VERSION ""

NS_ :

BS_:

BU_: FUSION IVI CMS

BO_ 2365479471 ASC1_A: 8 FUSION
 SG_ ASC1NomLvFAxis : 0|4@1+ (1,0) [0|15] "" IVI
 SG_ ASC1NomLvRAxis : 4|4@1+ (1,0) [0|15] "" IVI
 SG_ ASC1BlwNomLvFAxis : 8|2@1+ (1,0) [0|3] "" Vector__XXX
 SG_ ASC1BlwNomLvRAxis : 10|2@1+ (1,0) [0|3] "" Vector__XXX
 SG_ ASC1AbvNomLvFAxis : 12|2@1+ (1,0) [0|3] "" Vector__XXX
 SG_ ASC1AbvNomLvRAxis : 14|2@1+ (1,0) [0|3] "" Vector__XXX
 SG_ ASC1LowCtrlFAxis : 16|2@1+ (1,0) [0|3] "" Vector__XXX
 SG_ ASC1LowCtrlRAxis : 18|2@1+ (1,0) [0|3] "" Vector__XXX
 SG_ ASC1LiftCtrlFAxis : 20|2@1+ (1,0) [0|3] "" Vector__XXX
 SG_ ASC1LiftCtrlRAxis : 22|2@1+ (1,0) [0|3] "" Vector__XXX
 SG_ ASC1KneelingInfo : 24|4@1+ (1,0) [0|15] "" IVI
 SG_ ASC1LvCtrlM : 28|4@1+ (1,0) [0|15] "" Vector__XXX
 SG_ SADev : 32|2@1+ (1,0) [0|3] "" Vector__XXX
 SG_ VehMotion : 34|2@1+ (1,0) [0|3] "" Vector__XXX
 SG_ DoorRls : 36|2@1+ (1,0) [0|3] "" Vector__XXX
 SG_ ASC1LiftAxle1P : 38|2@1+ (1,0) [0|3] "" Vector__XXX
 SG_ FABumpR : 40|2@1+ (1,0) [0|3] "" Vector__XXX
 SG_ RABumpR : 42|2@1+ (1,0) [0|3] "" Vector__XXX
 SG_ LA2Pos : 46|2@1+ (1,0) [0|3] "" Vector__XXX
 SG_ SuspenRmCtrl1 : 48|2@1+ (1,0) [0|3] "" Vector__XXX
 SG_ SuspenRmCtrl2 : 50|2@1+ (1,0) [0|3] "" Vector__XXX
 SG_ SuspCtrlrefuInfo : 56|4@1+ (1,0) [0|15] "" Vector__XXX

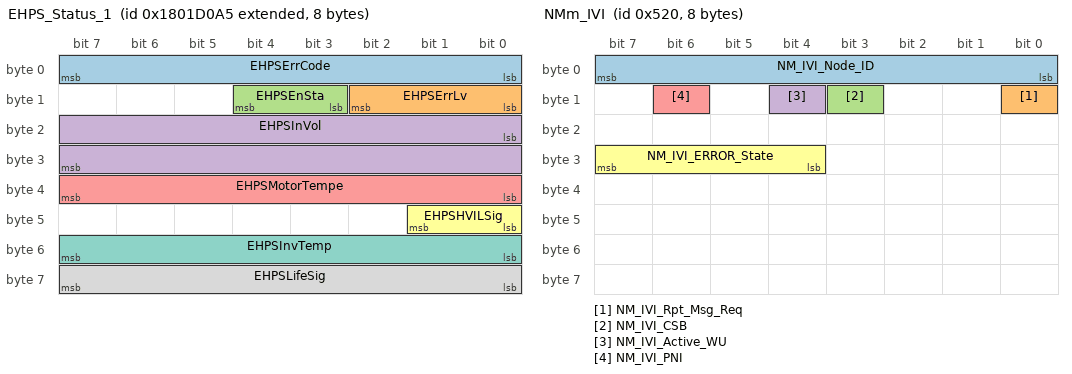
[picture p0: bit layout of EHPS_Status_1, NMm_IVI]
BO_ 2550255781 EHPS_Status_1: 8 FUSION
 SG_ EHPSErrCode : 0|8@1+ (1,0) [0|255] "" Vector__XXX
 SG_ EHPSErrLv : 8|3@1+ (1,0) [0|7] "" IVI
 SG_ EHPSEnSta : 11|2@1+ (1,0) [0|3] "" Vector__XXX
 SG_ EHPSInVol : 16|16@1+ (0.1,0) [0|1000] "V" Vector__XXX
 SG_ EHPSMotorTempe : 32|8@1+ (1,-40) [-40|200] "degC" Vector__XXX
 SG_ EHPSHVILSig : 40|2@1+ (1,0) [0|3] "" Vector__XXX
 SG_ EHPSInvTemp : 48|8@1+ (1,-40) [-40|150] "degC" Vector__XXX
 SG_ EHPSLifeSig : 56|8@1+ (1,0) [0|255] "" Vector__XXX

BO_ 2565865739 EBC1: 8 FUSION
 SG_ ASREngCtrlAtc : 0|2@1+ (1,0) [0|3] "" IVI
 SG_ ASRBrakeCtrlAtc : 2|2@1+ (1,0) [0|3] "" IVI
 SG_ AntiLBrakABSAct : 4|2@1+ (1,0) [0|3] "" Vector__XXX
 SG_ EBSBrakeSw : 6|2@1+ (1,0) [0|3] "" Vector__XXX
 SG_ BrakePedalPos : 8|8@1+ (0.4,0) [0|100] "%" Vector__XXX
 SG_ ABSOffroadSw : 16|2@1+ (1,0) [0|3] "" Vector__XXX
 SG_ ASROffroadSw : 18|2@1+ (1,0) [0|3] "" IVI
 SG_ ASRHillHolderSw : 20|2@1+ (1,0) [0|3] "" IVI
 SG_ TractCtrlOvrSw : 22|2@1+ (1,0) [0|3] "" Vector__XXX
 SG_ AcltrInterlockSw : 24|2@1+ (1,0) [0|3] "" Vector__XXX
 SG_ EngDerateSw : 26|2@1+ (1,0) [0|3] "" Vector__XXX
 SG_ EngAuxShutdownSw : 28|2@1+ (1,0) [0|3] "" Vector__XXX
 SG_ RmAccelEnSw : 30|2@1+ (1,0) [0|3] "" Vector__XXX
 SG_ EngRetSel : 32|8@1+ (0.4,0) [0|100] "%" Vector__XXX
 SG_ ABSFullyOper : 40|2@1+ (1,0) [0|3] "" IVI
 SG_ EBSRedWarnLampSta : 42|2@1+ (1,0) [0|3] "" IVI
 SG_ EBSAmWarnLampSta : 44|2@1+ (1,0) [0|3] "" IVI
 SG_ ATCASRInfoSig : 46|2@1+ (1,0) [0|3] "" IVI
 SG_ SACtrlBrakeCtrl : 48|8@1+ (1,0) [0|255] "SA" Vector__XXX
 SG_ HaltBrakeSw : 58|2@1+ (1,0) [0|3] "" Vector__XXX
 SG_ TrailerABSSta : 60|2@1+ (1,0) [0|3] "" Vector__XXX
 SG_ TrailerABSWarnSig : 62|2@1+ (1,0) [0|3] "" Vector__XXX

BO_ 513 IVI_P20_0: 64 IVI
 SG_ IVI_RrRoomlamp_Cmd : 0|1@0+ (1,0) [0|1] "" FUSION
 SG_ IVI_FrAtmoLamp_Cmd : 1|1@0+ (1,0) [0|1] "" FUSION
 SG_ IVI_RrAtmoLamp_Cmd : 2|1@0+ (1,0) [0|1] "" FUSION
 SG_ IVI_RrRmLampBright_Cmd : 6|4@0+ (1,0) [0|15] "" FUSION
 SG_ IVI_AmbiLgtSta : 7|1@0+ (1,0) [0|1] "" FUSION
 SG_ IVI_Passengerdoor_Sta : 10|1@0+ (1,0) [0|1] "" FUSION
 SG_ IVI_Frontindoorlight_Sta : 11|1@0+ (1,0) [0|1] "" FUSION
 SG_ IVI_FrRmLampBright_Cmd : 15|4@0+ (1,0) [0|15] "" FUSION

BO_ 602 METER1: 24 IVI
 SG_ METER_KPH_Calcu : 15|8@0+ (1,0) [0|254] "km/h" FUSION
 SG_ METER_MPH_Calcu : 23|8@0+ (1,0) [0|160] "mph" FUSION
 SG_ METER_KPH_Real : 31|12@0+ (0.125,0) [0|255.875] "km/h" FUSION
 SG_ METER_MPH_Real : 35|12@0+ (0.077675,0) [0|160.0105] "mph" FUSION
 SG_ Averaged_vehspeed : 49|10@0+ (1,0) [0|300] "km/h" FUSION
 SG_ AVGPwrConsumption : 71|16@0+ (0.1,-999.9) [-999.9|999.9] "Wh/km" FUSION
 SG_ APCforDTE : 87|16@0+ (0.1,-999.9) [-999.9|999.9] "Wh/km" FUSION
 SG_ AvailableTrip : 103|16@0+ (0.1,0) [0|999.9] "KM" FUSION
 SG_ ParkBrake : 112|1@0+ (1,0) [0|1] "" FUSION
 SG_ Charge : 113|1@0+ (1,0) [0|1] "" FUSION
 SG_ LEDlitWarnReq : 114|1@0+ (1,0) [0|1] "" FUSION
 SG_ Spd_Crl_Sta : 115|1@0+ (1,0) [0|1] "" FUSION
 SG_ Spd_Crl_Mode : 118|3@0+ (1,0) [0|7] "" FUSION
 SG_ Trip_B : 127|24@0+ (0.1,0) [0|99999.9] "KM" FUSION
 SG_ Trip_A : 151|24@0+ (0.1,0) [0|99999.9] "KM" FUSION
 SG_ ODOMETER : 175|24@0+ (0.1,0) [0|999999.9] "KM" FUSION

BO_ 1168 IVI1: 20 IVI
 SG_ FCP_FrEvt_BtnSyncReq : 16|1@0+ (1,0) [0|1] "" FUSION
 SG_ FCP_MidEvt_BtnAutoReq : 17|1@0+ (1,0) [0|1] "" FUSION
 SG_ FCP_FrEvt_BtnAutoReq : 18|1@0+ (1,0) [0|1] "" FUSION
 SG_ FCP_FrEvt_BtnACReq : 19|1@0+ (1,0) [0|1] "" FUSION
 SG_ FCP_FrEvt_BtnACMaxReq : 20|1@0+ (1,0) [0|1] "" FUSION
 SG_ VehACModReq : 23|3@0+ (1,0) [0|7] "" FUSION
 SG_ LINKtoDrive : 24|1@0+ (1,0) [0|1] "" FUSION
 SG_ SmartEco_Mode_SW : 25|1@0+ (1,0) [0|1] "" FUSION
 SG_ OTA_CancelDL_Req : 26|1@0+ (1,0) [0|1] "" FUSION
 SG_ IVI_OTA_Upd_Sta : 28|2@0+ (1,0) [0|3] "" FUSION
 SG_ OTA_UpdStart_Req : 29|1@0+ (1,0) [0|1] "" FUSION
 SG_ OTA_SuspendDL_Req : 30|1@0+ (1,0) [0|1] "" FUSION
 SG_ OTA_DL_Req : 31|1@0+ (1,0) [0|1] "" FUSION
 SG_ AmbLigh_SafetyAlert_SW : 32|1@0+ (1,0) [0|1] "" FUSION
 SG_ AmbLigh_LowBatAlert_SW : 33|1@0+ (1,0) [0|1] "" FUSION
 SG_ AmbLight_WlcmLight_SW : 34|1@0+ (1,0) [0|1] "" FUSION
 SG_ AmbLight_DimInDark_SW : 35|1@0+ (1,0) [0|1] "" FUSION
 SG_ AmbLight_SW : 36|1@0+ (1,0) [0|1] "" FUSION
 SG_ OpenDrOpenWdo_SW : 37|1@0+ (1,0) [0|1] "" FUSION
 SG_ Upd_Countdown_Cancel : 38|1@0+ (1,0) [0|1] "" FUSION
 SG_ Upd_Countdown_Skip : 39|1@0+ (1,0) [0|1] "" FUSION
 SG_ AmbLightColorSet : 46|7@0+ (1,0) [0|127] "" FUSION
 SG_ Sched_OTA_wake : 47|1@0+ (1,0) [0|1] "" FUSION
 SG_ A2B_Node_sta : 55|1@0+ (1,0) [0|1] "" FUSION
 SG_ Sched_Chg_St_Time_Min : 61|6@0+ (1,0) [0|59] "MINUTE" FUSION
 SG_ Sched_Chg_Day_Set : 62|1@0+ (1,0) [0|1] "" FUSION
 SG_ Re_Radio_Sta : 63|1@0+ (1,0) [0|1] "" FUSION
 SG_ Sched_Chg_St_Time_HR : 68|5@0+ (1,0) [0|23] "HOUR" FUSION
 SG_ UserSet : 71|3@0+ (1,0) [0|7] "" FUSION
 SG_ Sched_Chg_End_Time_Min : 77|6@0+ (1,0) [0|59] "MINUTE" FUSION
 SG_ Sched_Chg_End_Time_HR : 84|5@0+ (1,0) [0|23] "HOUR" FUSION
 SG_ BrkAbn_GoReady_SW : 85|1@0+ (1,0) [0|1] "" FUSION
 SG_ OTA_CompNTFY_Pres : 86|1@0+ (1,0) [0|1] "" FUSION
 SG_ mFRD_link_Sta : 87|1@0+ (1,0) [0|1] "" FUSION
 SG_ IVI_Time_Check : 95|8@0+ (1,0) [0|255] "" FUSION
 SG_ IVI_Time_Second : 101|6@0+ (1,0) [0|63] "SECOND" FUSION
 SG_ PW_CLOSE_IMD : 102|1@0+ (1,0) [0|1] "" FUSION
 SG_ PW_CONTINUE_USE : 103|1@0+ (1,0) [0|1] "" FUSION
 SG_ IVI_Time_Minute : 109|6@0+ (1,0) [0|63] "MINUTE" FUSION
 SG_ IVI_Time_Day : 116|5@0+ (1,0) [0|31] "DAY" FUSION
 SG_ IVI_DelAccReq_Sta : 119|3@0+ (1,0) [0|7] "" FUSION
 SG_ IVI_Time_Hour : 124|5@0+ (1,0) [0|31] "HOUR" FUSION
 SG_ IVI_CreateAccReq_Sta : 127|3@0+ (1,0) [0|7] "" FUSION
 SG_ IVI_Time_Month : 131|4@0+ (1,0) [0|12] "MONTH" FUSION
 SG_ IVI_LinkKey_Sta : 135|4@0+ (1,0) [0|15] "" FUSION
 SG_ IVI_Time_Year : 142|7@0+ (1,2000) [2000|2127] "YEAR" FUSION
 SG_ IVI_LinkAccReq_Sta : 143|1@0+ (1,0) [0|1] "" FUSION
 SG_ IVI_LinkAcc_Sta : 146|3@0+ (1,0) [0|7] "" FUSION
 SG_ IVI_FrTrunk_UnlockReq_Sta : 147|1@0+ (1,0) [0|1] "" FUSION
 SG_ IVI_CLWin_LockDoorSW_Sta : 148|1@0+ (1,0) [0|1] "" FUSION
 SG_ IVI_Lock_SoundSW_Sta : 149|1@0+ (1,0) [0|1] "" FUSION
 SG_ AmbLightBrightnessSet : 54|7@0+ (1,0) [0|127] "" FUSION
 SG_ IVI_Located_STA : 79|2@0+ (1,0) [0|3] "" FUSION
 SG_ IVI_AutoTheme_But_Sta : 154|1@0+ (1,0) [0|1] "" FUSION
 SG_ IVI_NAVI_Foreground_Sta : 155|1@0+ (1,0) [0|1] "" FUSION
 SG_ IVI_HMI_Undefined_Sta : 158|3@0+ (1,0) [0|7] "" FUSION
 SG_ IVI_QuickRefresh_Sta : 159|1@0+ (1,0) [0|1] "" FUSION
 SG_ IVI_DMS_SW_Sta : 150|1@0+ (1,0) [0|1] "" FUSION
 SG_ IVI_AirRefresh_ByDMS_Sta : 151|1@0+ (1,0) [0|1] "" FUSION
 SG_ IVI_SWC_VibMode_Sta : 111|2@0+ (1,0) [0|3] "" FUSION
 SG_ IVI_sigScreenReq_Sta : 152|1@0+ (1,0) [0|1] "" FUSION
 SG_ IVI_DSEAT_anti_set_Sta : 153|1@0+ (1,0) [0|1] "" FUSION

BO_ 1173 IVI2: 64 IVI
 SG_ Perd_V2L : 3|4@0+ (1,0) [0|15] "" FUSION
 SG_ SOC_V2LLimit : 7|4@0+ (5,20) [20|80] "%" FUSION
 SG_ Walkaway_Lock_SW : 8|1@0+ (1,0) [0|1] "" FUSION
 SG_ FalseNPrevent_SW : 10|1@0+ (1,0) [0|1] "" FUSION
 SG_ IVI_CreepSW_Req : 11|1@0+ (1,0) [0|1] "" FUSION
 SG_ IVI_CfmTo_Rdy : 15|1@0+ (1,0) [0|1] "" FUSION
 SG_ IVI_Req_V2L : 17|2@0+ (1,0) [0|2] "" FUSION
 SG_ IVI_PSEATHeater_Cmd : 20|3@0+ (1,0) [0|7] "" FUSION
 SG_ IVI_DSEATHeater_Cmd : 23|3@0+ (1,0) [0|7] "" FUSION
 SG_ Light_ShowStop_Req : 28|1@0+ (1,0) [0|1] "" FUSION
 SG_ Light_ShowStart_Req : 29|1@0+ (1,0) [0|1] "" FUSION
 SG_ WlcmLight_Mode : 31|2@0+ (1,0) [0|3] "" FUSION
 SG_ IVI_SWC_LUndefined_Sta : 75|4@0+ (1,0) [0|15] "" FUSION
 SG_ IVI_SWC_RUndefined_Sta : 79|4@0+ (1,0) [0|15] "" FUSION
 SG_ Sched_Chg_limit : 84|5@0+ (2,50) [50|100] "%" FUSION
 SG_ METER_Malfunc_Sta : 89|2@0+ (1,0) [0|2] "" FUSION
 SG_ sigFootReq : 90|1@0+ (1,0) [0|1] "" FUSION
 SG_ sigFaceReq : 91|1@0+ (1,0) [0|1] "" FUSION
 SG_ Sched_Chg_Start : 92|1@0+ (1,0) [0|1] "" FUSION
 SG_ Sched_Chg_wake : 93|1@0+ (1,0) [0|1] "" FUSION
 SG_ Sched_Chg_butt : 94|1@0+ (1,0) [0|1] "" FUSION
 SG_ Sched_Chg_Stop : 95|1@0+ (1,0) [0|1] "" FUSION
 SG_ L_RRD_ControlCommand : 102|7@0+ (1,0) [0|127] "%" FUSION
 SG_ IVI_Start_Chg_req : 103|1@0+ (1,0) [0|1] "" FUSION
 SG_ L_RLD_ControlCommand : 110|7@0+ (1,0) [0|127] "%" FUSION
 SG_ IVI_Stop_Chg_req : 111|1@0+ (1,0) [0|1] "" FUSION
 SG_ L_Pas_ControlCommand : 118|7@0+ (1,0) [0|127] "%" FUSION
 SG_ IVI_Unlock_Chg_req : 119|1@0+ (1,0) [0|1] "" FUSION
 SG_ L_Drv_ControlCommand : 126|7@0+ (1,0) [0|127] "%" FUSION
 SG_ TPMS_Cali_Butt : 127|1@0+ (1,0) [0|1] "" FUSION
 SG_ GPS_LONG : 135|32@0+ (1,0) [0|4.294967295E9] "" FUSION
 SG_ GPS_LAT : 167|32@0+ (1,0) [0|4.294967295E9] "SECOND" FUSION
 SG_ sigSetTempZon1Req : 197|6@0+ (0.5,17) [17|32] "Deg^C" FUSION
 SG_ sigHvacFrontReq : 198|1@0+ (1,0) [0|1] "" FUSION
 SG_ sigDfrstReq : 199|1@0+ (1,0) [0|1] "" FUSION
 SG_ sigSetTempZon2Req : 205|6@0+ (0.5,17) [17|32] "Deg^C" FUSION
 SG_ sigRecircReq : 206|1@0+ (1,0) [0|1] "" FUSION
 SG_ sigHvacReq : 207|1@0+ (1,0) [0|1] "" FUSION
 SG_ AEB_BUTT : 209|2@0+ (1,0) [0|3] "" FUSION
 SG_ sigSetTempZon3Req : 215|6@0+ (0.5,17) [17|32] "Deg^C" FUSION
 SG_ sigAirIntenZon3Req : 219|4@0+ (1,0) [0|15] "" FUSION
 SG_ sigAirIntenZon1Req : 223|4@0+ (1,0) [0|15] "" FUSION
 SG_ BSDMute_BUTT : 225|2@0+ (1,0) [0|3] "" FUSION
 SG_ sigWindDirZon3Req : 228|3@0+ (1,0) [0|7] "" FUSION
 SG_ FCWMute_BUTT : 233|2@0+ (1,0) [0|3] "" FUSION
 SG_ LKA_BUTT : 235|2@0+ (1,0) [0|3] "" FUSION
 SG_ ODAMute_BUTT : 237|2@0+ (1,0) [0|3] "" FUSION
 SG_ LDWMute_BUTT : 239|2@0+ (1,0) [0|3] "" FUSION
 SG_ NAVI_Speed_Limit_A : 241|2@0+ (1,0) [0|3] "" FUSION
 SG_ Temperature_unit : 242|1@0+ (1,0) [0|1] "" FUSION
 SG_ Distance_unit : 243|1@0+ (1,0) [0|1] "" FUSION
 SG_ ESC_SW_Cmd : 245|2@0+ (1,0) [0|3] "" FUSION
 SG_ IVI_Panel_Act : 246|1@0+ (1,0) [0|1] "" FUSION
 SG_ sigHvacRearReq : 247|1@0+ (1,0) [0|1] "" FUSION
 SG_ Time_system : 255|8@0+ (1,0) [0|255] "" FUSION
 SG_ Pressure_unit : 263|8@0+ (1,0) [0|255] "" FUSION
 SG_ IVI_Screen : 269|6@0+ (1,0) [0|62] "" FUSION
 SG_ TurnSwTimeSet : 271|2@0+ (1,0) [0|3] "" FUSION
 SG_ NAVI_Direction_STA : 279|8@0+ (1,0) [0|255] "" FUSION
 SG_ OFF_AC_MODE : 282|3@0+ (1,0) [0|7] "" FUSION
 SG_ IVI_PW_Mode_Req : 284|2@0+ (1,0) [0|3] "" FUSION
 SG_ User_p_upload : 285|1@0+ (1,0) [0|1] "" FUSION
 SG_ CameraWrn : 286|1@0+ (1,0) [0|1] "" FUSION
 SG_ Wifi_Reset : 287|1@0+ (1,0) [0|1] "" FUSION
 SG_ NAVI_Cam_Dist_info : 295|8@0+ (1,0) [0|255] "m" FUSION
 SG_ IVI_Panel_X_Coor : 303|12@0+ (1,0) [0|4095] "" FUSION
 SG_ IVI_Panel_Y_Coor : 307|12@0+ (1,0) [0|4095] "" FUSION
 SG_ HeadLampSW : 321|2@0+ (1,0) [0|3] "" FUSION
 SG_ NAVI_State : 323|2@0+ (1,0) [0|3] "" FUSION
 SG_ Wifi_Sta_IVI_TBOX : 327|4@0+ (1,0) [0|15] "" FUSION
 SG_ MFRD_N_Bright_Req : 334|7@0+ (1,0) [0|100] "%" FUSION
 SG_ User_p_download : 335|1@0+ (1,0) [0|1] "" FUSION
 SG_ PSEAT_vent_req : 338|3@0+ (1,0) [0|7] "" FUSION
 SG_ FFogLampSW : 339|1@0+ (1,0) [0|1] "" FUSION
 SG_ DSEAT_vent_req : 342|3@0+ (1,0) [0|7] "" FUSION
 SG_ RFogLampSW : 343|1@0+ (1,0) [0|1] "" FUSION
 SG_ IVI_PTG_Mode_SW : 345|2@0+ (1,0) [0|3] "" FUSION
 SG_ IVI_PTG_Sta_SW : 347|2@0+ (1,0) [0|3] "" FUSION
 SG_ SLG_Sw : 349|2@0+ (1,0) [0|3] "" FUSION
 SG_ FS_Off_Sw : 351|2@0+ (1,0) [0|3] "" FUSION
 SG_ CAAS_Sw : 353|2@0+ (1,0) [0|3] "" FUSION
 SG_ DSEAT_entryfun_set : 354|1@0+ (1,0) [0|1] "" FUSION
 SG_ DSEAT_anti_set : 355|1@0+ (1,0) [0|1] "" FUSION
 SG_ IVI_TrailerCheckReq_Sta : 356|1@0+ (1,0) [0|1] "" FUSION
 SG_ TPMS_Res_Butt : 357|1@0+ (1,0) [0|1] "" FUSION
 SG_ FollowMeSW : 358|1@0+ (1,0) [0|1] "" FUSION
 SG_ SetUnlockSingle : 359|1@0+ (1,0) [0|1] "" FUSION
 SG_ IVI_Mute_Sta : 360|1@0+ (1,0) [0|1] "" FUSION
 SG_ IVI_PTG_USSta_SW : 361|1@0+ (1,0) [0|1] "" FUSION
 SG_ IVI_WI_MAIN_SW : 362|1@0+ (1,0) [0|1] "" FUSION
 SG_ IVI_RR_Def_Req : 363|1@0+ (1,0) [0|1] "" FUSION
 SG_ IVI_Night_Mode_Sta : 364|1@0+ (1,0) [0|1] "" FUSION
 SG_ IVI_Status : 365|1@0+ (1,0) [0|1] "" FUSION
 SG_ LVDAMute_BUTT : 367|2@0+ (1,0) [0|3] "" FUSION
 SG_ NAVI_Distance_info : 375|24@0+ (1,0) [0|1.6777215E7] "m" FUSION
 SG_ Hood_Latch_SW : 393|2@0+ (1,0) [0|3] "" FUSION
 SG_ IVI_TrailerModeSW_Sta : 394|1@0+ (1,0) [0|1] "" FUSION
 SG_ RCTA_BUTT : 396|2@0+ (1,0) [0|3] "" FUSION
 SG_ IVI_Pwroff_req : 397|1@0+ (1,0) [0|1] "" FUSION
 SG_ IVI_Trigger_req : 398|1@0+ (1,0) [0|1] "" FUSION
 SG_ AVM_Err_STA : 399|1@0+ (1,0) [0|1] "" FUSION
 SG_ SenstivityPosition : 403|4@0+ (1,0) [0|15] "" FUSION
 SG_ AVM_Parking_mode : 407|4@0+ (1,0) [0|15] "" FUSION
 SG_ NAVI_Tunnel : 411|12@0+ (1,0) [0|2000] "m" FUSION
 SG_ NAVI_ForwardLinkLevel : 415|4@0+ (1,0) [0|15] "" FUSION
 SG_ NAVI_Tollgate : 427|12@0+ (1,0) [0|2000] "m" FUSION
 SG_ NAVI_LinkClass : 431|4@0+ (1,0) [0|15] "" FUSION
 SG_ NAVI_SpeedLimit : 444|5@0+ (1,0) [0|31] "km/h" FUSION
 SG_ NAVI_RoadClass : 447|3@0+ (1,0) [0|7] "" FUSION
 SG_ RoomLampMode : 455|1@0+ (1,0) [0|1] "" FUSION
 SG_ AC_Chg_Cur_Set : 462|7@0+ (1,5) [5|132] "A" FUSION
 SG_ IVI_SWC_ACCMode_Sta : 463|1@0+ (1,0) [0|1] "" FUSION
 SG_ SOC_Limit_Set : 468|5@0+ (2,50) [50|100] "%" FUSION
 SG_ CDL_Lock_Butt : 469|1@0+ (1,0) [0|1] "" FUSION
 SG_ CDL_Unlock_Butt : 470|1@0+ (1,0) [0|1] "" FUSION
 SG_ SOC_ADJ_BUTT : 471|1@0+ (1,0) [0|1] "" FUSION
 SG_ Roll_Mode_SW_Cmd : 473|2@0+ (1,0) [0|3] "" FUSION
 SG_ TCS_SW_Cmd : 475|2@0+ (1,0) [0|3] "" FUSION
 SG_ SLIF_BUTT : 477|2@0+ (1,0) [0|2] "" FUSION
 SG_ Roll_Eng_Mode : 478|1@0+ (1,0) [0|1] "" FUSION
 SG_ IVI_LVChrgFuncSW : 497|2@0+ (1,0) [0|3] "" FUSION
 SG_ IVI_PwrLockSW : 499|2@0+ (1,0) [0|3] "" FUSION
 SG_ IVI_CoastDwSW : 501|2@0+ (1,0) [0|3] "" FUSION
 SG_ IVI_ActvDmpDisabSW : 503|2@0+ (1,0) [0|3] "" FUSION
 SG_ AVM_parking_cancel : 505|2@0+ (1,0) [0|3] "" FUSION
 SG_ AVM_parking_excute : 507|2@0+ (1,0) [0|3] "" FUSION
 SG_ AVM_OFF_Rec_Butt : 508|1@0+ (1,0) [0|1] "" FUSION
 SG_ Approach_Unlock_SW : 9|1@0+ (1,0) [0|1] "" FUSION
 SG_ IVI_ISA_OffsetSpd : 451|4@0+ (1,0) [0|14] "" FUSION
 SG_ IVI_PTG_Open_Height : 14|3@0+ (1,0) [0|7] "" FUSION
 SG_ IVI_ChargePortSW_Sta : 479|1@0+ (1,0) [0|1] "" FUSION
 SG_ IVI_SLIF_Warning_Sta : 453|2@0+ (1,0) [0|3] "" FUSION
 SG_ IVI_ACC_Adaptive_Sta : 454|1@0+ (1,0) [0|1] "" FUSION
 SG_ IVI_PSEAT_Slide_Cmd : 49|2@0+ (1,0) [0|3] "" FUSION
 SG_ IVI_DSEAT_FroEdge_Height_Cmd : 51|2@0+ (1,0) [0|3] "" FUSION
 SG_ IVI_DSEAT_Height_Cmd : 53|2@0+ (1,0) [0|3] "" FUSION
 SG_ IVI_DSEAT_Recline_Cmd : 55|2@0+ (1,0) [0|3] "" FUSION
 SG_ IVI_PSEAT_Recline_Cmd : 41|2@0+ (1,0) [0|3] "" FUSION
 SG_ IVI_DSEAT_Memory_OPTCLS_Sta : 42|1@0+ (1,0) [0|1] "" FUSION
 SG_ IVI_SetTempZon2_Sta : 47|5@0+ (1,0) [0|31] "" FUSION
 SG_ IVI_AirIntZ3_Cmd : 34|3@0+ (1,0) [0|7] "" FUSION
 SG_ IVI_SetTempZon1_Sta : 39|5@0+ (1,0) [0|31] "" FUSION
 SG_ IVI_DSEAT_Slide_Cmd : 25|2@0+ (1,0) [0|3] "" FUSION
 SG_ IVI_DSEAT_Memory1_Sta : 27|1@0+ (1,0) [0|1] "" FUSION
 SG_ IVI_DSEAT_Memory2_Sta : 26|1@0+ (1,0) [0|1] "" FUSION
 SG_ DMS_Status : 61|2@0+ (1,0) [0|3] "" FUSION
 SG_ DMS_Warning_Distraction : 59|2@0+ (1,0) [0|3] "" FUSION
 SG_ DMS_Warning_Fatigue : 57|2@0+ (1,0) [0|3] "" FUSION
 SG_ DMS_Warning_Unresponsive : 62|1@0+ (1,0) [0|1] "" FUSION

BO_ 1312 NMm_IVI: 8 IVI
 SG_ NM_IVI_Node_ID : 7|8@0+ (1,0) [0|127] "" FUSION
 SG_ NM_IVI_Rpt_Msg_Req : 8|1@0+ (1,0) [0|1] "" FUSION
 SG_ NM_IVI_CSB : 11|1@0+ (1,0) [0|1] "" FUSION
 SG_ NM_IVI_Active_WU : 12|1@0+ (1,0) [0|1] "" FUSION
 SG_ NM_IVI_PNI : 14|1@0+ (1,0) [0|1] "" FUSION
 SG_ NM_IVI_ERROR_State : 31|4@0+ (1,0) [0|8] "" FUSION

BO_ 1568 DiagRespFromIVI: 8 IVI
 SG_ DiagRespFromIVI : 7|64@0+ (1,0) [0|0] "" FUSION

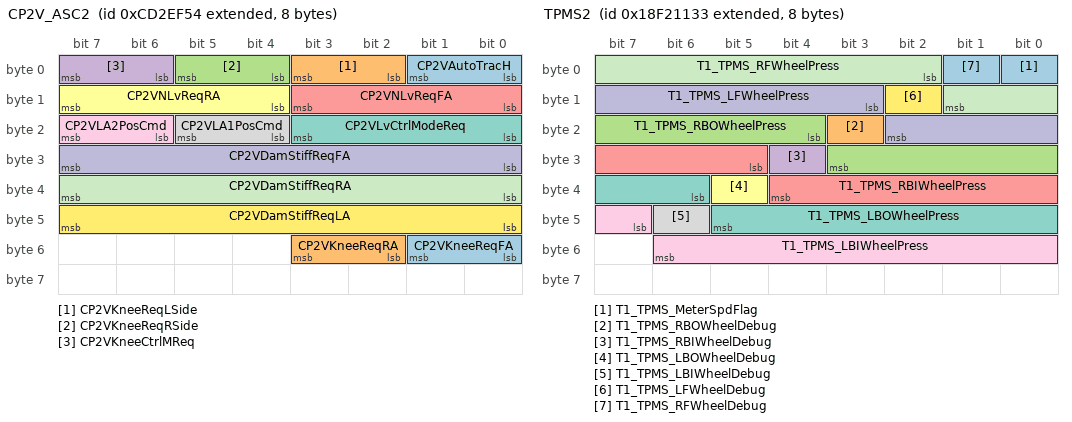
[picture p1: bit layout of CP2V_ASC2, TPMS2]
BO_ 2362634068 CP2V_ASC2: 8 IVI
 SG_ CP2VAutoTracH : 0|2@1+ (1,0) [0|3] "" FUSION
 SG_ CP2VKneeReqLSide : 2|2@1+ (1,0) [0|3] "" FUSION
 SG_ CP2VKneeReqRSide : 4|2@1+ (1,0) [0|3] "" FUSION
 SG_ CP2VKneeCtrlMReq : 6|2@1+ (1,0) [0|3] "" FUSION
 SG_ CP2VNLvReqFA : 8|4@1+ (1,0) [0|15] "" FUSION
 SG_ CP2VNLvReqRA : 12|4@1+ (1,0) [0|15] "" FUSION
 SG_ CP2VLvCtrlModeReq : 16|4@1+ (1,0) [0|15] "" FUSION
 SG_ CP2VLA1PosCmd : 20|2@1+ (1,0) [0|3] "" FUSION
 SG_ CP2VLA2PosCmd : 22|2@1+ (1,0) [0|3] "" FUSION
 SG_ CP2VDamStiffReqFA : 24|8@1+ (0.4,0) [0|102] "%" FUSION
 SG_ CP2VDamStiffReqRA : 32|8@1+ (0.4,0) [0|102] "%" FUSION
 SG_ CP2VDamStiffReqLA : 40|8@1+ (0.4,0) [0|102] "%" FUSION
 SG_ CP2VKneeReqFA : 48|2@1+ (1,0) [0|3] "" FUSION
 SG_ CP2VKneeReqRA : 50|2@1+ (1,0) [0|3] "" FUSION

BO_ 2147484162 FD2_CE100_1: 32 FUSION
 SG_ FDC_VCU_DACStatus_Sta : 7|2@0+ (1,0) [0|3] "" IVI
 SG_ FDC_VCU_TUpASta_Sta : 5|2@0+ (1,0) [0|3] "" IVI
 SG_ FDC_BCM_WelcomeDemo_Sta : 3|1@0+ (1,0) [0|1] "" IVI
 SG_ FDC_BCM_TgateSWL_Sta : 2|1@0+ (1,0) [0|1] "" IVI
 SG_ FDC_BCM_TgateSWR_Sta : 1|1@0+ (1,0) [0|1] "" IVI

BO_ 2566000691 TPMS1: 8 FUSION
 SG_ T1_TPMS_RBOPressIndi : 4|2@1+ (1,0) [0|3] "" IVI
 SG_ T1_TPMS_LBOPressIndi : 6|2@1+ (1,0) [0|3] "" IVI
 SG_ T1_TPMS_RBIPressIndi : 8|2@1+ (1,0) [0|3] "" IVI
 SG_ T1_TPMS_LBIPressIndi : 10|2@1+ (1,0) [0|3] "" IVI
 SG_ T1_TPMS_RBOWheelTmpIndi : 14|1@1+ (1,0) [0|1] "" IVI
 SG_ T1_TPMS_LBOWheelTmpIndi : 15|1@1+ (1,0) [0|1] "" IVI
 SG_ T1_TPMS_RBIWheelTmpIndi : 16|1@1+ (1,0) [0|1] "" IVI
 SG_ T1_TPMS_LBIWheelTmpIndi : 17|1@1+ (1,0) [0|1] "" IVI
 SG_ T1_TPMS_RBOSensorFail : 20|1@1+ (1,0) [0|1] "" IVI
 SG_ T1_TPMS_LBOSensorFail : 21|1@1+ (1,0) [0|1] "" IVI
 SG_ T1_TPMS_RBISensorFail : 22|1@1+ (1,0) [0|1] "" IVI
 SG_ T1_TPMS_LBISensorFail : 23|1@1+ (1,0) [0|1] "" IVI
 SG_ T1_TPMS_RBOBatWarn : 26|1@1+ (1,0) [0|1] "" IVI
 SG_ T1_TPMS_LBOBatWarn : 27|1@1+ (1,0) [0|1] "" IVI
 SG_ T1_TPMS_RBIBatWarn : 28|1@1+ (1,0) [0|1] "" IVI
 SG_ T1_TPMS_LBIBatWarn : 29|1@1+ (1,0) [0|1] "" IVI
 SG_ T1_TPMS_TPMSExist : 30|1@1+ (1,0) [0|1] "" Vector__XXX
 SG_ T1_TPMS_TPMSHWVer : 40|8@1+ (1,0) [0|255] "" Vector__XXX
 SG_ T1_TPMS_TPMSSWVer : 48|8@1+ (1,0) [0|255] "" Vector__XXX
 SG_ T1_TPMS_RFPressIndi : 0|2@1+ (1,0) [0|3] "" Vector__XXX
 SG_ T1_TPMS_TPMSWarnIndi : 31|2@1+ (1,0) [0|3] "" Vector__XXX
 SG_ T1_TPMS_LFBatWarn : 25|1@1+ (1,0) [0|1] "" Vector__XXX
 SG_ T1_TPMS_LFPressIndi : 2|2@1+ (1,0) [0|3] "" Vector__XXX
 SG_ T1_TPMS_LFSensorFail : 19|1@1+ (1,0) [0|1] "" Vector__XXX
 SG_ T1_TPMS_LFWheelTmpIndi : 13|1@1+ (1,0) [0|1] "" Vector__XXX
 SG_ T1_TPMS_RFBatWarn : 24|1@1+ (1,0) [0|1] "" Vector__XXX
 SG_ T1_TPMS_RFSensorFail : 18|1@1+ (1,0) [0|1] "" Vector__XXX
 SG_ T1_TPMS_RFWheelTmpIndi : 12|1@1+ (1,0) [0|1] "" Vector__XXX

BO_ 2566000947 TPMS2: 8 FUSION
 SG_ T1_TPMS_MeterSpdFlag : 0|1@1+ (1,0) [0|1] "" Vector__XXX
 SG_ T1_TPMS_RBOWheelDebug : 19|1@1+ (1,0) [0|1] "" Vector__XXX
 SG_ T1_TPMS_RBOWheelPress : 20|8@1+ (1,0) [0|254] "psi" IVI
 SG_ T1_TPMS_RBIWheelDebug : 28|1@1+ (1,0) [0|1] "" Vector__XXX
 SG_ T1_TPMS_RBIWheelPress : 29|8@1+ (1,0) [0|254] "psi" IVI
 SG_ T1_TPMS_LBOWheelDebug : 37|1@1+ (1,0) [0|1] "" Vector__XXX
 SG_ T1_TPMS_LBOWheelPress : 38|8@1+ (1,0) [0|254] "psi" IVI
 SG_ T1_TPMS_LBIWheelDebug : 46|1@1+ (1,0) [0|1] "" Vector__XXX
 SG_ T1_TPMS_LBIWheelPress : 47|8@1+ (1,0) [0|254] "psi" IVI
 SG_ T1_TPMS_LFWheelPress : 11|8@1+ (1,0) [0|250] "" Vector__XXX
 SG_ T1_TPMS_RFWheelPress : 2|8@1+ (1,0) [0|250] "" Vector__XXX
 SG_ T1_TPMS_LFWheelDebug : 10|1@1+ (1,0) [0|1] "" Vector__XXX
 SG_ T1_TPMS_RFWheelDebug : 1|1@1+ (1,0) [0|1] "" Vector__XXX

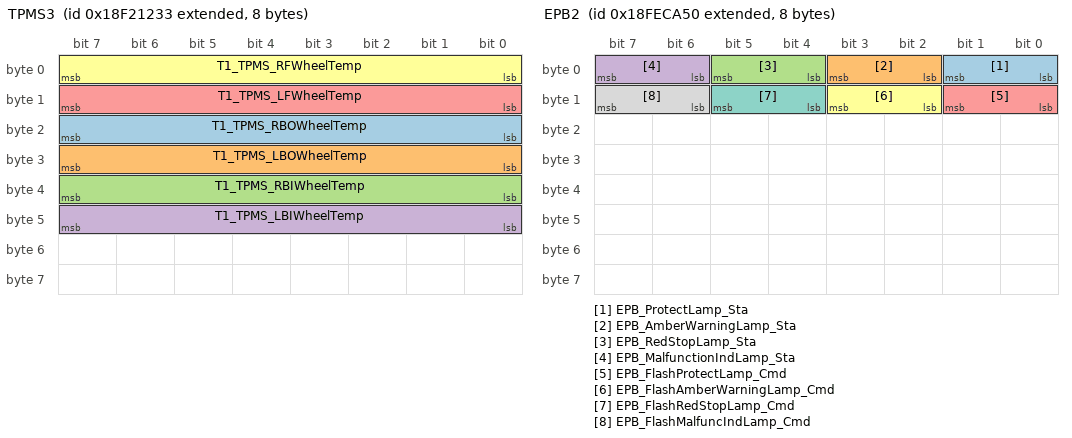
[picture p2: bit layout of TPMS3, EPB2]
BO_ 2566001203 TPMS3: 8 FUSION
 SG_ T1_TPMS_RBOWheelTemp : 16|8@1+ (1,-40) [-40|125] "deg^C" IVI
 SG_ T1_TPMS_LBOWheelTemp : 24|8@1+ (1,-40) [-40|125] "deg^C" IVI
 SG_ T1_TPMS_RBIWheelTemp : 32|8@1+ (1,-40) [-40|125] "deg^C" IVI
 SG_ T1_TPMS_LBIWheelTemp : 40|8@1+ (1,-40) [-40|215] "deg^C" IVI
 SG_ T1_TPMS_LFWheelTemp : 8|8@1+ (1,-40) [-40|215] "Deg^C" Vector__XXX
 SG_ T1_TPMS_RFWheelTemp : 0|8@1+ (1,-40) [-40|215] "Deg^C" Vector__XXX

BO_ 2566844752 EPB1: 8 FUSION
 SG_ EPB_ParkingBrake_Sta : 2|2@1+ (1,0) [0|3] "" IVI

BO_ 2566834768 EPB2: 8 FUSION
 SG_ EPB_ProtectLamp_Sta : 0|2@1+ (1,0) [0|3] "" Vector__XXX
 SG_ EPB_AmberWarningLamp_Sta : 2|2@1+ (1,0) [0|3] "" Vector__XXX
 SG_ EPB_RedStopLamp_Sta : 4|2@1+ (1,0) [0|3] "" Vector__XXX
 SG_ EPB_MalfunctionIndLamp_Sta : 6|2@1+ (1,0) [0|3] "" Vector__XXX
 SG_ EPB_FlashProtectLamp_Cmd : 8|2@1+ (1,0) [0|3] "" Vector__XXX
 SG_ EPB_FlashAmberWarningLamp_Cmd : 10|2@1+ (1,0) [0|3] "" Vector__XXX
 SG_ EPB_FlashRedStopLamp_Cmd : 12|2@1+ (1,0) [0|3] "" Vector__XXX
 SG_ EPB_FlashMalfuncIndLamp_Cmd : 14|2@1+ (1,0) [0|3] "" Vector__XXX

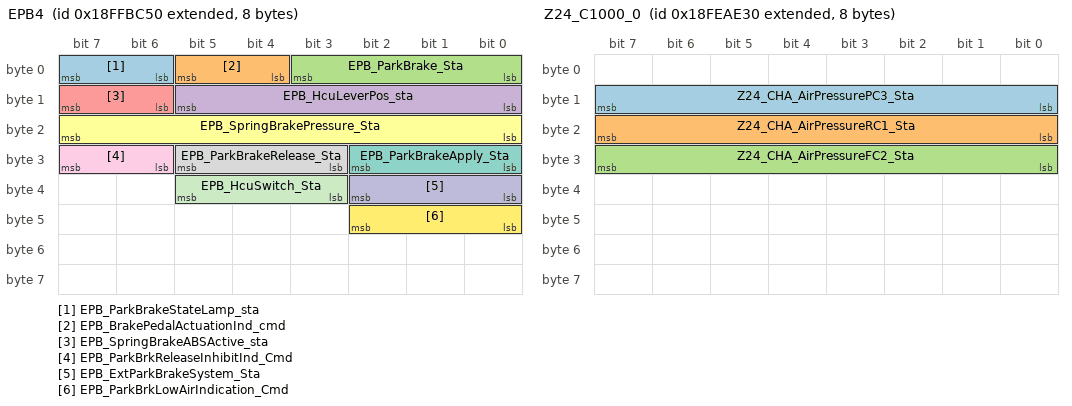
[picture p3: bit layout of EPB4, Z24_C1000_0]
BO_ 2566896720 EPB4: 8 FUSION
 SG_ EPB_ParkBrakeStateLamp_sta : 6|2@1+ (1,0) [0|3] "" IVI
 SG_ EPB_BrakePedalActuationInd_cmd : 4|2@1+ (1,0) [0|3] "" IVI
 SG_ EPB_ParkBrake_Sta : 0|4@1+ (1,0) [0|15] "" IVI
 SG_ EPB_HcuLeverPos_sta : 8|6@1+ (2,0) [0|126] "%" IVI
 SG_ EPB_SpringBrakeABSActive_sta : 14|2@1+ (1,0) [0|3] "" IVI
 SG_ EPB_SpringBrakePressure_Sta : 16|8@1+ (5,0) [0|1250] "KPa" IVI
 SG_ EPB_ParkBrakeApply_Sta : 24|3@1+ (1,0) [0|7] "" IVI
 SG_ EPB_ParkBrakeRelease_Sta : 27|3@1+ (1,0) [0|7] "" IVI
 SG_ EPB_ParkBrkReleaseInhibitInd_Cmd : 30|2@1+ (1,0) [0|3] "" IVI
 SG_ EPB_ExtParkBrakeSystem_Sta : 32|3@1+ (1,0) [0|7] "" IVI
 SG_ EPB_HcuSwitch_Sta : 35|3@1+ (1,0) [0|7] "" IVI
 SG_ EPB_ParkBrkLowAirIndication_Cmd : 40|3@1+ (1,0) [0|7] "" IVI

BO_ 515 Z24_CE100_0: 32 FUSION
 SG_ Z24_BCM_FLTurnLampC_Sta : 7|8@0+ (10,0) [0|2550] "mA" Vector__XXX
 SG_ Z24_BCM_FRTurnLampC_Sta : 15|8@0+ (10,0) [0|2550] "mA" Vector__XXX
 SG_ Z24_BCM_RLTurnLampC_Sta : 23|8@0+ (10,0) [0|2550] "mA" Vector__XXX
 SG_ Z24_BCM_RRTurnLampC_Sta : 31|8@0+ (10,0) [0|2550] "mA" Vector__XXX
 SG_ Z24_BCM_FWiperProtection_Sta : 39|1@0+ (1,0) [0|1] "" Vector__XXX
 SG_ Z24_BCM_FWiperAS_Sta : 38|1@0+ (1,0) [0|1] "" Vector__XXX
 SG_ Z24_BCM_EmExitOP_Sta : 37|1@0+ (1,0) [0|1] "" Vector__XXX
 SG_ Z24_BCM_innerBuzzer_Sta : 36|1@0+ (1,0) [0|1] "" Vector__XXX
 SG_ Z24_BCM_SeatBeltSW_Sta : 35|1@0+ (1,0) [0|1] "" IVI

BO_ 2566827568 Z24_C1000_0: 8 FUSION
 SG_ Z24_CHA_AirPressurePC3_Sta : 8|8@1+ (8,0) [0|1400] "KPa" Vector__XXX
 SG_ Z24_CHA_AirPressureRC1_Sta : 16|8@1+ (8,0) [0|1400] "KPa" IVI
 SG_ Z24_CHA_AirPressureFC2_Sta : 24|8@1+ (8,0) [0|1400] "KPa" IVI

BO_ 2565865967 FD2_C200_1: 8 FUSION
 SG_ FDC_CHA_CACTempWarn_Sta : 48|1@0+ (1,0) [0|1] "" IVI
 SG_ FDC_CHA_CACPresWarn_Sta : 9|1@1+ (1,0) [0|1] "" IVI

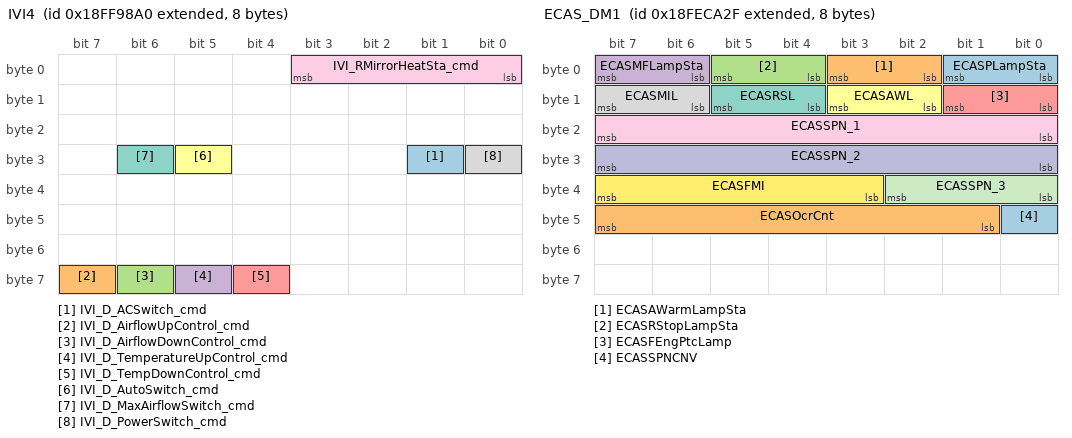
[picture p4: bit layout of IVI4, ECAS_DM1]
BO_ 2566887584 IVI4: 8 IVI
 SG_ IVI_D_ACSwitch_cmd : 25|1@0+ (1,0) [0|1] "" FUSION
 SG_ IVI_D_AirflowUpControl_cmd : 63|1@0+ (1,0) [0|1] "" FUSION
 SG_ IVI_D_AirflowDownControl_cmd : 62|1@0+ (1,0) [0|1] "" FUSION
 SG_ IVI_D_TemperatureUpControl_cmd : 61|1@0+ (1,0) [0|1] "" FUSION
 SG_ IVI_D_TempDownControl_cmd : 60|1@0+ (1,0) [0|1] "" FUSION
 SG_ IVI_D_AutoSwitch_cmd : 29|1@0+ (1,0) [0|1] "" FUSION
 SG_ IVI_D_MaxAirflowSwitch_cmd : 30|1@0+ (1,0) [0|1] "" FUSION
 SG_ IVI_D_PowerSwitch_cmd : 24|1@0+ (1,0) [0|1] "" FUSION
 SG_ IVI_RMirrorHeatSta_cmd : 3|4@0+ (1,0) [0|15] "" FUSION

BO_ 2566834735 ECAS_DM1: 8 FUSION
 SG_ ECASPLampSta : 0|2@1+ (1,0) [0|3] "" Vector__XXX
 SG_ ECASAWarmLampSta : 2|2@1+ (1,0) [0|3] "" IVI
 SG_ ECASRStopLampSta : 4|2@1+ (1,0) [0|3] "" Vector__XXX
 SG_ ECASMFLampSta : 6|2@1+ (1,0) [0|3] "" Vector__XXX
 SG_ ECASFEngPtcLamp : 8|2@1+ (1,0) [0|3] "" Vector__XXX
 SG_ ECASAWL : 10|2@1+ (1,0) [0|3] "" Vector__XXX
 SG_ ECASRSL : 12|2@1+ (1,0) [0|3] "" Vector__XXX
 SG_ ECASMIL : 14|2@1+ (1,0) [0|3] "" Vector__XXX
 SG_ ECASSPN_1 : 16|8@1+ (1,0) [0|255] "" Vector__XXX
 SG_ ECASSPN_2 : 24|8@1+ (1,0) [0|255] "" Vector__XXX
 SG_ ECASSPN_3 : 32|3@1+ (1,0) [0|7] "" Vector__XXX
 SG_ ECASFMI : 35|5@1+ (1,0) [0|31] "" Vector__XXX
 SG_ ECASSPNCNV : 40|1@1+ (1,0) [0|1] "" Vector__XXX
 SG_ ECASOcrCnt : 41|7@1+ (1,0) [0|127] "" Vector__XXX

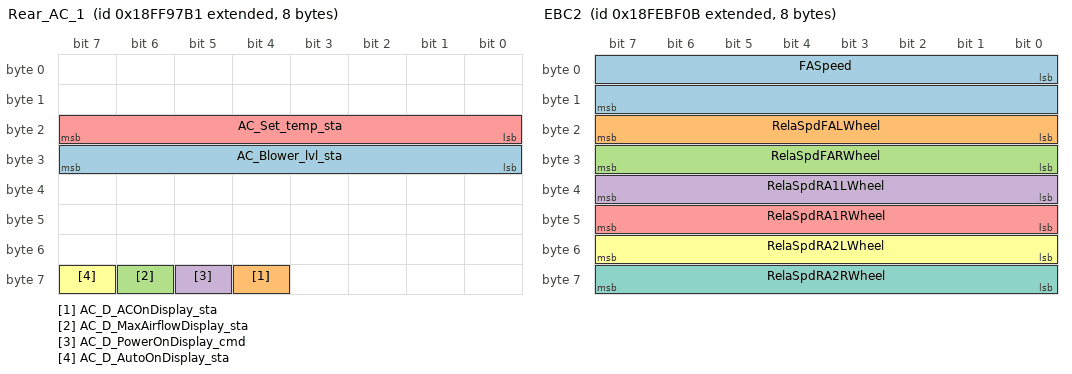
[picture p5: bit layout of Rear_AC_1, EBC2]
BO_ 2566887345 Rear_AC_1: 8 FUSION
 SG_ AC_Blower_lvl_sta : 31|8@0+ (1,0) [0|255] "" IVI
 SG_ AC_D_ACOnDisplay_sta : 60|1@0+ (1,0) [0|1] "" IVI
 SG_ AC_D_MaxAirflowDisplay_sta : 62|1@0+ (1,0) [0|1] "" IVI
 SG_ AC_D_PowerOnDisplay_cmd : 61|1@0+ (1,0) [0|1] "" IVI
 SG_ AC_Set_temp_sta : 23|8@0+ (1,0) [0|25] "Deg^C" IVI
 SG_ AC_D_AutoOnDisplay_sta : 63|1@0+ (1,0) [0|1] "" Vector__XXX

BO_ 2566831883 EBC2: 8 FUSION
 SG_ FASpeed : 0|16@1+ (0.00390625,0) [0|250.99609375] "km/h" Vector__XXX
 SG_ RelaSpdFALWheel : 16|8@1+ (0.0625,-7.8125) [-7.8125|7.8125] "km/h" Vector__XXX
 SG_ RelaSpdFARWheel : 24|8@1+ (0.0625,-7.8125) [-7.8125|7.8125] "km/h" Vector__XXX
 SG_ RelaSpdRA1LWheel : 32|8@1+ (0.0625,-7.8125) [-7.8125|7.8125] "km/h" Vector__XXX
 SG_ RelaSpdRA1RWheel : 40|8@1+ (0.0625,-7.8125) [-7.8125|7.8125] "km/h" Vector__XXX
 SG_ RelaSpdRA2LWheel : 48|8@1+ (0.0625,-7.8125) [-7.8125|7.8125] "km/h" Vector__XXX
 SG_ RelaSpdRA2RWheel : 56|8@1+ (0.0625,-7.8125) [-7.8125|7.8125] "km/h" Vector__XXX

BO_ 1175 IVI3: 32 IVI
 SG_ IVI_CLBlower_Y_Sta : 38|7@0+ (1,0) [0|127] "%" FUSION
 SG_ IVI_CLBlower_Z_Sta : 46|7@0+ (1,0) [0|127] "%" FUSION
 SG_ IVI_CRBlower_Y_Sta : 54|7@0+ (1,0) [0|127] "%" FUSION
 SG_ IVI_CRBlower_Z_Sta : 62|7@0+ (1,0) [0|127] "%" FUSION
 SG_ IVI_DrBlower_Mode_Sta : 71|2@0+ (1,0) [0|3] "" FUSION
 SG_ IVI_DrBlower_Y_Sta : 6|7@0+ (1,0) [0|127] "%" FUSION
 SG_ IVI_DrBlower_Z_Sta : 14|7@0+ (1,0) [0|127] "%" FUSION
 SG_ IVI_LSEATvent_Cmd : 101|3@0+ (1,0) [0|7] "" FUSION
 SG_ IVI_MLFMost_Cmd : 31|1@0+ (1,0) [0|1] "" FUSION
 SG_ IVI_MLFootLift_Cmd : 75|2@0+ (1,0) [0|3] "" FUSION
 SG_ IVI_MLNapMode_Cmd : 23|1@0+ (1,0) [0|1] "" FUSION
 SG_ IVI_MLRecliner_Cmd : 79|2@0+ (1,0) [0|3] "" FUSION
 SG_ IVI_MLRestore_Cmd : 15|1@0+ (1,0) [0|1] "" FUSION
 SG_ IVI_MLSEATvent_Cmd : 93|3@0+ (1,0) [0|7] "" FUSION
 SG_ IVI_MLSeatLift_Cmd : 73|2@0+ (1,0) [0|3] "" FUSION
 SG_ IVI_MLSldRestore_Cmd : 7|1@0+ (1,0) [0|1] "" FUSION
 SG_ IVI_MLSlider_Cmd : 77|2@0+ (1,0) [0|3] "" FUSION
 SG_ IVI_MLZeroGravity_Cmd : 39|1@0+ (1,0) [0|1] "" FUSION
 SG_ IVI_MRFMost_Cmd : 94|1@0+ (1,0) [0|1] "" FUSION
 SG_ IVI_MRFootLift_Cmd : 83|2@0+ (1,0) [0|3] "" FUSION
 SG_ IVI_MRNapMode_Cmd : 63|1@0+ (1,0) [0|1] "" FUSION
 SG_ IVI_MRRecliner_Cmd : 87|2@0+ (1,0) [0|3] "" FUSION
 SG_ IVI_MRRestore_Cmd : 55|1@0+ (1,0) [0|1] "" FUSION
 SG_ IVI_MRSEATvent_Cmd : 90|3@0+ (1,0) [0|7] "" FUSION
 SG_ IVI_MRSeatLift_Cmd : 81|2@0+ (1,0) [0|3] "" FUSION
 SG_ IVI_MRSldRestore_Cmd : 47|1@0+ (1,0) [0|1] "" FUSION
 SG_ IVI_MRSlider_Cmd : 85|2@0+ (1,0) [0|3] "" FUSION
 SG_ IVI_MRZeroGravity_Cmd : 95|1@0+ (1,0) [0|1] "" FUSION
 SG_ IVI_PsBlower_Mode_Sta : 69|2@0+ (1,0) [0|3] "" FUSION
 SG_ IVI_PsBlower_Y_Sta : 22|7@0+ (1,0) [0|127] "%" FUSION
 SG_ IVI_PsBlower_Z_Sta : 30|7@0+ (1,0) [0|127] "%" FUSION
 SG_ IVI_RSEATvent_Cmd : 98|3@0+ (1,0) [0|7] "" FUSION

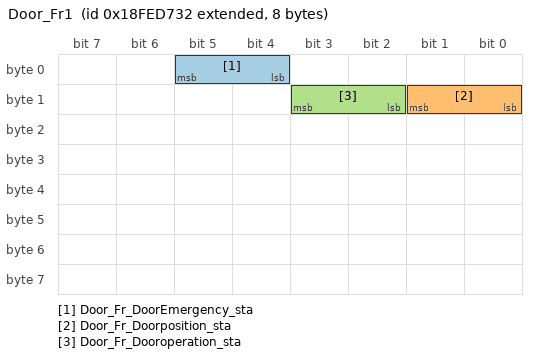
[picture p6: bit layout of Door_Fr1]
BO_ 2566838066 Door_Fr1: 8 FUSION
 SG_ Door_Fr_DoorEmergency_sta : 4|2@1+ (1,0) [0|3] "" Vector__XXX
 SG_ Door_Fr_Doorposition_sta : 8|2@1+ (1,0) [0|3] "" IVI
 SG_ Door_Fr_Dooroperation_sta : 10|2@1+ (1,0) [0|3] "" Vector__XXX

CM_ SG_ 2365479471 ASC1NomLvFAxis "Nominal level front axle";
CM_ SG_ 2365479471 ASC1NomLvRAxis "Nominal level rear axle";
CM_ SG_ 2365479471 ASC1BlwNomLvFAxis "Below nominal level front axle";
CM_ SG_ 2365479471 ASC1BlwNomLvRAxis "Below nominal level rear axle";
CM_ SG_ 2365479471 ASC1AbvNomLvFAxis "Above nominal level front axle";
CM_ SG_ 2365479471 ASC1AbvNomLvRAxis "Above nominal level rear axle";
CM_ SG_ 2365479471 ASC1LowCtrlFAxis "Lowering control mode front axle";
CM_ SG_ 2365479471 ASC1LowCtrlRAxis "Lowering control mode rear axle";
CM_ SG_ 2365479471 ASC1LiftCtrlFAxis "Lifting control mode front axle";
CM_ SG_ 2365479471 ASC1LiftCtrlRAxis "Lifting control mode rear axle";
CM_ SG_ 2365479471 ASC1KneelingInfo "Kneeling information
ECAS側傾指示";
CM_ SG_ 2365479471 ASC1LvCtrlM "Level control mode";
CM_ SG_ 2365479471 SADev "Security device";
CM_ SG_ 2365479471 VehMotion "Vehicle motion inhibit";
CM_ SG_ 2365479471 DoorRls "Door release";
CM_ SG_ 2365479471 ASC1LiftAxle1P "Lift axle 1 position";
CM_ SG_ 2365479471 FABumpR "Front axle in bumper range";
CM_ SG_ 2365479471 RABumpR "Rear axle in bumper range";
CM_ SG_ 2365479471 LA2Pos "Lift axle 2 position";
CM_ SG_ 2365479471 SuspenRmCtrl1 "Suspension Remote control #1";
CM_ SG_ 2365479471 SuspenRmCtrl2 "Suspension Remote control #2";
CM_ SG_ 2365479471 SuspCtrlrefuInfo "Suspension control refusal information";
CM_ SG_ 2550255781 EHPSErrCode "EHPS故障代碼
EHPS fault code
詳見動力總成系統故障代碼總冊-EHPS
Refer to powertrain system failure code general -EHPS";
CM_ SG_ 2550255781 EHPSErrLv "EHPS故障等級
EHPS fault level";
CM_ SG_ 2550255781 EHPSEnSta "EHPS使能狀態
EHPS enable state";
CM_ SG_ 2550255781 EHPSInVol "EHPS輸入電壓
EHPS input voltage";
CM_ SG_ 2550255781 EHPSMotorTempe "EHPS電機溫度(預留）
EHPS_Motor_Temperature（reserved）";
CM_ SG_ 2550255781 EHPSHVILSig "高壓互鎖信號(預留）
HV_interlock signal（reserved）";
CM_ SG_ 2550255781 EHPSInvTemp "EHPS溫度
The EHPS temperature";
CM_ SG_ 2550255781 EHPSLifeSig "EHPS生命信號
EHPS Life signal";
CM_ SG_ 2565865739 ASREngCtrlAtc "State signal which indicates that ASR engine control has been commanded to be active. Active means that ASR actually tries to control the engine. This state signal is independent of other control commands to the engine (e.g., from the transmission) which may have higher priority.

00b = ASR engine control passive but installed
01b = ASR engine control active
10b = Reserved
11b = Not available";
CM_ SG_ 2565865739 ASRBrakeCtrlAtc "State signal which indicates that ASR brake control is active. Active means that ASR actually controls wheel brake pressure at one or more wheels of the driven axle(s).

00b = ASR brake control passive but installed
01b = ASR brake control active
10b = Reserved
11b = Not available";
CM_ SG_ 2565865739 AntiLBrakABSAct "State signal which indicates that the ABS is active.  The signal is set active when wheel brake pressure actually starts to be modulated by ABS and is reset to passive when all wheels are in a stable condition for a certain time.  The signal can also be set active when driven wheels are in high slip  (e.g., caused by retarder).  Whenever the ABS system is not fully operational (due to a defect or during off-road ABS operation) , this signal is only valid for that part of the system that is still working.  ";
CM_ SG_ 2565865739 EBSBrakeSw "Switch signal which indicates that the brake pedal is being pressed.  The EBS brake switch is independent of the brake light switch and has no provisions for external connections.

00b = Brake pedal is not being pressed
01b = Brake pedal is being pressed
10b = Error
11b = Not available";
CM_ SG_ 2565865739 BrakePedalPos "Ratio of brake pedal position to maximum pedal position.  Used for electric brake applications. 0% means no braking. Also when there are two brake pedals on the machine (Left Brake Pedal Position SPN 3033 and Right Brake Pedal Position SPN 3032) the maximum of the two should be transmitted for Brake Pedal Position.";
CM_ SG_ 2565865739 ABSOffroadSw "Switch signal which indicates the position of the ABS off-road switch.

00b = ABS off-road switch passive
01b = ABS off-road switch active
10b = Error
11b = Not available";
CM_ SG_ 2565865739 ASROffroadSw "Switch signal which indicates the position of the ASR off-road switch.

00b = ASR off-road switch passive
01b = ASR off-road switch active
10b = Error
11b = Not available";
CM_ SG_ 2565865739 ASRHillHolderSw "Switch signal which indicates the position of the ASR “hill holder“ switch.

00b = ASR “hill holder“ switch passive
01b = ASR “hill holder“ switch active
10b = Error
11b = Not available";
CM_ SG_ 2565865739 TractCtrlOvrSw "Switch signal which indicates the position of the traction control override switch.  The traction control override signal disables the automatic traction control function allowing the wheels to spin.

00b = Off
01b = On
10b = Error
11b = Not available or not installed";
CM_ SG_ 2565865739 AcltrInterlockSw "Switch signal used to disable the accelerator and remote accelerator inputs, causing the engine to return to idle.

00b = Off
01b = On
10b = Error
11b = Not available";
CM_ SG_ 2565865739 EngDerateSw "Switch signal used to activate the torque limiting feature of the engine.  The specific nature of torque limiting should be verified with the manufacturer.

00b = Off
01b = On
10b = Error
11b = Not available";
CM_ SG_ 2565865739 EngAuxShutdownSw "Switch signal which requests that all engine fueling stop.

00b = Off
01b = On
10b = Error
11b = Not available";
CM_ SG_ 2565865739 RmAccelEnSw "Switch signal which indicates that the remote accelerator has been enabled and controls the engine.  

00b = Off
01b = On
10b = Error
11b = Not available

NOTE—The accelerator interlock switch (see SPN 972) must be disabled in order for the remote accelerator to perform engine control.";
CM_ SG_ 2565865739 EngRetSel "The position of the operator controlled selector, expressed as a percentage and determined by the ratio of the current position of the selector to its maximum possible position. Zero percent means no braking torque is requested by the operator from the engine while 100% means maximum braking.";
CM_ SG_ 2565865739 ABSFullyOper "Signal which indicates whether an ABS system is fully operational or whether its functionality is reduced by a defect or by an intended action (e.g., by activation of an ABS-off-road switch or during special diagnostic procedures).  There are cases where the signal is necessary to fulfill legal regulations for special applications (e.g., switching off integrated retarders).

00b = Not Fully Operational
01b = Fully Operational
10b = Reserved
11b = Not available";
CM_ SG_ 2565865739 EBSRedWarnLampSta "This parameter commands the EBS red optical warning signal

00b = Off
01b = On
10b = Reserved
11b = Take no action";
CM_ SG_ 2565865739 EBSAmWarnLampSta "This parameter commands the ABS/EBS amber/yellow optical warning signal

00b = Off
01b = On
10b = Reserved
11b = Take no action";
CM_ SG_ 2565865739 ATCASRInfoSig "This parameter commands the ATC/ASR driver information signal, for example a dash lamp.

00b = Off
01b = On 
10b = Reserved
11b = Take no action";
CM_ SG_ 2565865739 SACtrlBrakeCtrl "The source address of the SAE J1939 device currently controlling the brake system. Its value may be the source address of the ECU transmitting the message (which means that no external SAE J1939 message is providing the active command) or the source address of the SAE J1939 ECU that is currently providing the active command in a TSC1 (see PGN 0) or similar message.  Note that if this parameter value is the same as the source address of the device transmitting it, the control may be due to a message on a no";
CM_ SG_ 2565865739 HaltBrakeSw "Switch signal which indicates the position of the Railroad mode switch.

00b = Railroad mode switch passive (City/Highway mode)
01b = Railroad mode switch active (Railroad mode)
10b = Error
11b = Not available

Note:  This switch signal to be used to inform the ABS/ASR ECU or other ECUs that the vehicle is operating in a railroad mode vs. a normal driving mode. Railroad mode is when a vehicle (i.e. vocational truck) has deployed the railroad gear such that the vehicle can be driven on a railroad tra";
CM_ SG_ 2565865739 TrailerABSSta "Switch signal which indicates the position of the halt brake switch.

00b = Halt brake switch passive
01b = Halt brake switch active
10b = Error
11b = Not available";
CM_ SG_ 2565865739 TrailerABSWarnSig "State signal which indicates that ABS in the trailer is actively controlling the brakes.  A message is sent to the tractor from the trailer (i.e. by PLC). The receiving device in the tractor transfers this information to the J1939 network.  At the beginning of power on the message is sent by the trailer to indicate if this status information is supported. Timeout of the trailer ABS active can be done by monitoring of the Trailer warning light information.

00b = Trailer ABS Status Information Available B";
CM_ SG_ 513 IVI_RrRoomlamp_Cmd "Rear Room lamp";
CM_ SG_ 513 IVI_FrAtmoLamp_Cmd "Front Bright Set changing";
CM_ SG_ 513 IVI_RrAtmoLamp_Cmd "Rear Room lamp  changing";
CM_ SG_ 513 IVI_RrRmLampBright_Cmd "Rear Room Lamp  Bright adjustment";
CM_ SG_ 513 IVI_AmbiLgtSta "AmbiLgtSta";
CM_ SG_ 513 IVI_Passengerdoor_Sta "Passenger doort";
CM_ SG_ 513 IVI_Frontindoorlight_Sta "Front indoor light";
CM_ SG_ 513 IVI_FrRmLampBright_Cmd "Front Room Lamp  Bright adjustment";
CM_ SG_ 602 METER_KPH_Calcu "METER Calculated Speed(KPH)";
CM_ SG_ 602 METER_MPH_Calcu "METER Calculated Speed(MPH)";
CM_ SG_ 602 METER_KPH_Real "METER Real Speed(KPH)";
CM_ SG_ 602 METER_MPH_Real "METER Real Speed(MPH)";
CM_ SG_ 602 Averaged_vehspeed "Averaged_vehspeed";
CM_ SG_ 602 AVGPwrConsumption "average power consumption";
CM_ SG_ 602 AvailableTrip "Distance to Empty";
CM_ SG_ 602 ParkBrake "Park Brake";
CM_ SG_ 602 Charge "Charge";
CM_ SG_ 602 LEDlitWarnReq "LED lit Warning Request";
CM_ SG_ 602 Spd_Crl_Sta "Speed Control Function Status";
CM_ SG_ 602 Spd_Crl_Mode "Speed Control Function Mode";
CM_ SG_ 602 Trip_B "TripB";
CM_ SG_ 602 Trip_A "TripA";
CM_ SG_ 602 ODOMETER "Odometer";
CM_ SG_ 1168 FCP_FrEvt_BtnSyncReq "Sync Button Press";
CM_ SG_ 1168 FCP_MidEvt_BtnAutoReq "Middle Auto Button Press";
CM_ SG_ 1168 FCP_FrEvt_BtnAutoReq "Front Auto Button Press";
CM_ SG_ 1168 FCP_FrEvt_BtnACReq "AC Max Button Press max cooling";
CM_ SG_ 1168 FCP_FrEvt_BtnACMaxReq "AC Max Button Press max cooling";
CM_ SG_ 1168 VehACModReq "Vehicle Air Conition mode
0x2~0x5:Reserved
0x2~0x5:Reserved";
CM_ SG_ 1168 LINKtoDrive "LINK to Drive";
CM_ SG_ 1168 SmartEco_Mode_SW "Smart ECO Mode Switch";
CM_ SG_ 1168 OTA_CancelDL_Req "OTA Cancel Download Request";
CM_ SG_ 1168 IVI_OTA_Upd_Sta "IVI OTA Update Status";
CM_ SG_ 1168 OTA_UpdStart_Req "OTA Update Start Request";
CM_ SG_ 1168 OTA_SuspendDL_Req "OTA Suspend Download Request";
CM_ SG_ 1168 OTA_DL_Req "OTA Download Request";
CM_ SG_ 1168 AmbLigh_SafetyAlert_SW "AmbLight Safety alert Switch";
CM_ SG_ 1168 AmbLigh_LowBatAlert_SW "AmbLight Low battery alert Switch";
CM_ SG_ 1168 AmbLight_WlcmLight_SW "AmbLight Welcome light Switch";
CM_ SG_ 1168 AmbLight_DimInDark_SW "AmbLight Dimmed In Dark Switch";
CM_ SG_ 1168 AmbLight_SW "AmbLight Switch";
CM_ SG_ 1168 OpenDrOpenWdo_SW "Open Door Link Open Window Switch";
CM_ SG_ 1168 Upd_Countdown_Cancel "Update Countdown Cancel";
CM_ SG_ 1168 Upd_Countdown_Skip "Update Countdown Skip";
CM_ SG_ 1168 AmbLightColorSet "AmbLight Color Set";
CM_ SG_ 1168 Sched_OTA_wake "Scheduled OTA wake up";
CM_ SG_ 1168 A2B_Node_sta "A2B node status";
CM_ SG_ 1168 Sched_Chg_St_Time_Min "Scheduled Charging Start Time Minute Setting";
CM_ SG_ 1168 Sched_Chg_Day_Set "Scheduled Charging Daily setting";
CM_ SG_ 1168 Re_Radio_Sta "Re-active Radio Status";
CM_ SG_ 1168 Sched_Chg_St_Time_HR "Scheduled Charging Start Time Hour Setting";
CM_ SG_ 1168 UserSet "UserSet";
CM_ SG_ 1168 Sched_Chg_End_Time_Min "Scheduled Charging End Time Minute Setting";
CM_ SG_ 1168 Sched_Chg_End_Time_HR "Scheduled Charging End Time Hour Setting";
CM_ SG_ 1168 BrkAbn_GoReady_SW "Brake Abnormal Go Ready";
CM_ SG_ 1168 OTA_CompNTFY_Pres "OTA Complete notify presented";
CM_ SG_ 1168 mFRD_link_Sta "Meter FRD Link status";
CM_ SG_ 1168 IVI_Time_Check "IVI_GPS Satellite Time_Check Sum";
CM_ SG_ 1168 IVI_Time_Second "IVI_GPS Satellite Time_Second";
CM_ SG_ 1168 PW_CLOSE_IMD "Power Close Immediately";
CM_ SG_ 1168 PW_CONTINUE_USE "Power Continue Use";
CM_ SG_ 1168 IVI_Time_Minute "IVI_GPS Satellite Time_Minute";
CM_ SG_ 1168 IVI_Time_Day "IVI_GPS Satellite Time_Day";
CM_ SG_ 1168 IVI_DelAccReq_Sta "IVI Delete account request";
CM_ SG_ 1168 IVI_Time_Hour "IVI_GPS Satellite Time_Hour";
CM_ SG_ 1168 IVI_CreateAccReq_Sta "IVI Create account request";
CM_ SG_ 1168 IVI_Time_Month "IVI_GPS Satellite Time_Month";
CM_ SG_ 1168 IVI_LinkKey_Sta "Target key of link key function";
CM_ SG_ 1168 IVI_Time_Year "IVI_GPS Satellite Time_Year";
CM_ SG_ 1168 IVI_LinkAccReq_Sta "IVI link target key to target user request";
CM_ SG_ 1168 IVI_LinkAcc_Sta "Target user of link key function (0x6 is default user, is not linkable)";
CM_ SG_ 1168 IVI_FrTrunk_UnlockReq_Sta "IVI Front Trunk Unlock Request";
CM_ SG_ 1168 IVI_CLWin_LockDoorSW_Sta "Close window when lock door";
CM_ SG_ 1168 IVI_Lock_SoundSW_Sta "IVI_Lock_SoundSW_Sta";
CM_ SG_ 1168 AmbLightBrightnessSet "Ambient Light Brightness Set";
CM_ SG_ 1168 IVI_Located_STA "IVI_GPS Satellite Located status";
CM_ SG_ 1168 IVI_AutoTheme_But_Sta "IVI Auto Light/Dark Theme Button Status";
CM_ SG_ 1168 IVI_NAVI_Foreground_Sta "IVI Navigation Foreground Status";
CM_ SG_ 1168 IVI_HMI_Undefined_Sta "IVI HMI Undefined button Mode ";
CM_ SG_ 1168 IVI_QuickRefresh_Sta "IVI Quick Refresh Switch";
CM_ SG_ 1168 IVI_DMS_SW_Sta "IVI Driver Monitoring System Switch";
CM_ SG_ 1168 IVI_AirRefresh_ByDMS_Sta "IVI Air Refresh Detect by DMS switch";
CM_ SG_ 1168 IVI_SWC_VibMode_Sta "IVI Steering Wheel  Vibration Mode";
CM_ SG_ 1168 IVI_sigScreenReq_Sta "IVI SCREEN BLOWER REQUEST ";
CM_ SG_ 1168 IVI_DSEAT_anti_set_Sta "Driver Seat Antitheft on/off request";
CM_ SG_ 1173 Perd_V2L "V2L Period Setting";
CM_ SG_ 1173 SOC_V2LLimit "SOC V2LLimitation";
CM_ SG_ 1173 Walkaway_Lock_SW "Lock when walking away";
CM_ SG_ 1173 FalseNPrevent_SW "Prevent FALSE turn GEAR into N";
CM_ SG_ 1173 IVI_CreepSW_Req "IVI Creep On/Off Switch Request";
CM_ SG_ 1173 IVI_CfmTo_Rdy "IVI Confirm to Ready";
CM_ SG_ 1173 IVI_Req_V2L "Driver trigs V2L function via IVI";
CM_ SG_ 1173 IVI_PSEATHeater_Cmd "IVI Passenger seat heater request";
CM_ SG_ 1173 IVI_DSEATHeater_Cmd "IVI Driver seat heater request";
CM_ SG_ 1173 Light_ShowStop_Req "Light Show Stop Request";
CM_ SG_ 1173 Light_ShowStart_Req "Light Show Start Request";
CM_ SG_ 1173 WlcmLight_Mode "Welcome Light Mode";
CM_ SG_ 1173 IVI_SWC_LUndefined_Sta "IVI Steering Wheel Left Undefined button Mode";
CM_ SG_ 1173 IVI_SWC_RUndefined_Sta "IVI Steering Wheel Right Undefined button Mode ";
CM_ SG_ 1173 Sched_Chg_limit "Scheduled Charging charging limit";
CM_ SG_ 1173 METER_Malfunc_Sta "Meter Malfunction Status";
CM_ SG_ 1173 sigFootReq "FOOT BLOWER REQUEST";
CM_ SG_ 1173 sigFaceReq "FACE BLOWER REQUEST";
CM_ SG_ 1173 Sched_Chg_Start "Scheduled Charging Start";
CM_ SG_ 1173 Sched_Chg_wake "Scheduled Charging wake up";
CM_ SG_ 1173 Sched_Chg_butt "Scheduled Charging Button";
CM_ SG_ 1173 Sched_Chg_Stop "Scheduled Charging stop";
CM_ SG_ 1173 L_RRD_ControlCommand "Rear Right  window control command";
CM_ SG_ 1173 IVI_Start_Chg_req "IVI Start Charging Request";
CM_ SG_ 1173 L_RLD_ControlCommand "Rear Left window control command";
CM_ SG_ 1173 IVI_Stop_Chg_req "IVI Stop Charging Request";
CM_ SG_ 1173 L_Pas_ControlCommand "Passenger window control command";
CM_ SG_ 1173 IVI_Unlock_Chg_req "IVI unlock Charging port Request";
CM_ SG_ 1173 L_Drv_ControlCommand "Driver window control command";
CM_ SG_ 1173 TPMS_Cali_Butt "TPMS tire calibrate button";
CM_ SG_ 1173 GPS_LONG "GPS Location_Longitude";
CM_ SG_ 1173 GPS_LAT "GPS Location_Latitude";
CM_ SG_ 1173 sigSetTempZon1Req "Temperature setpoint  for HVAC Zone 1";
CM_ SG_ 1173 sigHvacFrontReq "Request for operation for the front HVAC (ON / OFF)";
CM_ SG_ 1173 sigDfrstReq "Defrost request for the HVAC (ON / AUTO)";
CM_ SG_ 1173 sigSetTempZon2Req "Temperature setpoint  for HVAC Zone 2";
CM_ SG_ 1173 sigRecircReq "Recirculation request for the HVAC (ON / AUTO)";
CM_ SG_ 1173 sigHvacReq "Request for operation for the HVAC (ON / OFF)";
CM_ SG_ 1173 AEB_BUTT "AEB  ON/OFF Buttom";
CM_ SG_ 1173 sigSetTempZon3Req "Temperature setpoint  for HVAC Zone 3";
CM_ SG_ 1173 sigAirIntenZon3Req "Request to HVAC FAN Level/Air Intensirty: 0-Max or Auto for zone 3
0xb~0xE:Reserved
0xb~0xE:Reserved
0xb~0xE:Reserved";
CM_ SG_ 1173 sigAirIntenZon1Req "Request to HVAC FAN Level/Air Intensirty: 0-Max or Auto for zone 1
0xb~0xE:Reserved
0xb~0xE:Reserved
0xb~0xE:Reserved";
CM_ SG_ 1173 BSDMute_BUTT "BSD Mute Buttom";
CM_ SG_ 1173 sigWindDirZon3Req "Request to HVAC Wind Direction Zone 3. 
Feed, Body and/or Auto";
CM_ SG_ 1173 FCWMute_BUTT "FCW Mute Buttom";
CM_ SG_ 1173 LKA_BUTT "LKA  ON/OFF Buttom";
CM_ SG_ 1173 ODAMute_BUTT "ODA Mute Buttom";
CM_ SG_ 1173 LDWMute_BUTT "LDW Mute Buttom";
CM_ SG_ 1173 NAVI_Speed_Limit_A "NAVI Speed Limitation Applicable";
CM_ SG_ 1173 Temperature_unit "Temperature unit";
CM_ SG_ 1173 Distance_unit "Distance unit";
CM_ SG_ 1173 ESC_SW_Cmd "ESC ON/OFF Buttom";
CM_ SG_ 1173 IVI_Panel_Act "IVI Touch Panel Active";
CM_ SG_ 1173 sigHvacRearReq "Request for operation for the rear HVAC (ON / OFF)";
CM_ SG_ 1173 Time_system "Time system";
CM_ SG_ 1173 Pressure_unit "Pressure unit";
CM_ SG_ 1173 IVI_Screen "IVI Screen
0x1d~0x3E:undefined";
CM_ SG_ 1173 TurnSwTimeSet "turning switch flash time set";
CM_ SG_ 1173 NAVI_Direction_STA "NAVI Direction Status";
CM_ SG_ 1173 OFF_AC_MODE "OFF AC MODE";
CM_ SG_ 1173 IVI_PW_Mode_Req "IVI Power Mode require";
CM_ SG_ 1173 User_p_upload "User profile upload";
CM_ SG_ 1173 CameraWrn "Speed cameras Warming";
CM_ SG_ 1173 Wifi_Reset "Wifi Reset between VIG and OBU";
CM_ SG_ 1173 NAVI_Cam_Dist_info "Navigation speed camera distance information";
CM_ SG_ 1173 IVI_Panel_X_Coor "IVI Touch Panel X coordinate";
CM_ SG_ 1173 IVI_Panel_Y_Coor "IVI Touch Panel Y coordinate";
CM_ SG_ 1173 HeadLampSW "Head Lamp Switch";
CM_ SG_ 1173 NAVI_State "Information for Navigation Status";
CM_ SG_ 1173 Wifi_Sta_IVI_TBOX "Wifi signal status between IVI and TBOX";
CM_ SG_ 1173 MFRD_N_Bright_Req "MFRD night Brightness setting";
CM_ SG_ 1173 User_p_download "User profile download";
CM_ SG_ 1173 PSEAT_vent_req "Passenger Seat Ventilate request
0= No Request,
1= Vent1,
2= Vent2,
3= Vent3,
4= Off";
CM_ SG_ 1173 FFogLampSW "Front Fog Lamp Switch";
CM_ SG_ 1173 DSEAT_vent_req "Driver Seat ventilate request";
CM_ SG_ 1173 RFogLampSW "Rear Fog Lamp Switch";
CM_ SG_ 1173 IVI_PTG_Mode_SW "Power Tail Gate Manual and Automatic mode Switch";
CM_ SG_ 1173 IVI_PTG_Sta_SW "Power Tail Gate Open and Close Switch";
CM_ SG_ 1173 SLG_Sw "Smart liftgate Switch Status";
CM_ SG_ 1173 FS_Off_Sw "F_USS Switch Status";
CM_ SG_ 1173 CAAS_Sw "Collision Avoidance Assistance System Switch Status";
CM_ SG_ 1173 DSEAT_entryfun_set "Driver Seat Entry on/off request";
CM_ SG_ 1173 DSEAT_anti_set "Driver Seat Antitheft on/off request";
CM_ SG_ 1173 IVI_TrailerCheckReq_Sta "Trailer Check request";
CM_ SG_ 1173 TPMS_Res_Butt "TPMS_Reset_button";
CM_ SG_ 1173 FollowMeSW "Follow Me Home SW";
CM_ SG_ 1173 SetUnlockSingle "Single Set Unlock DOOR SETTING";
CM_ SG_ 1173 IVI_Mute_Sta "IVI Mute status";
CM_ SG_ 1173 IVI_PTG_USSta_SW "Power Tail Gate Ultrasonic Switch";
CM_ SG_ 1173 IVI_WI_MAIN_SW "IVI Wiper Maintance_Switch";
CM_ SG_ 1173 IVI_RR_Def_Req "IVI Rear Deffogger Status";
CM_ SG_ 1173 IVI_Night_Mode_Sta "IVI Night Mode Status";
CM_ SG_ 1173 IVI_Status "IVI Status";
CM_ SG_ 1173 LVDAMute_BUTT "LDW Mute Buttom";
CM_ SG_ 1173 NAVI_Distance_info "NAVI Distance Information";
CM_ SG_ 1173 Hood_Latch_SW "Hood Latch Switch";
CM_ SG_ 1173 IVI_TrailerModeSW_Sta "Trailer Mode Switch";
CM_ SG_ 1173 RCTA_BUTT "RCTA ON/OFF Button";
CM_ SG_ 1173 IVI_Pwroff_req "IVI Power off request";
CM_ SG_ 1173 IVI_Trigger_req "IVI Trigger VCU to Ready request";
CM_ SG_ 1173 AVM_Err_STA "AVM Error Status";
CM_ SG_ 1173 SenstivityPosition "wiper Senstivity Position";
CM_ SG_ 1173 AVM_Parking_mode "AVM_Parking Mode";
CM_ SG_ 1173 NAVI_Tunnel "Information for Tunnel exist (Exist information shall be informed 500m ahead)";
CM_ SG_ 1173 NAVI_ForwardLinkLevel "Information for Forward Link Level in Freeway (Change information shall be informed 500m ahead)";
CM_ SG_ 1173 NAVI_Tollgate "Information for Tollgate exist (Exist information shall be informed 500m ahead)";
CM_ SG_ 1173 NAVI_LinkClass "Information for Link Class Value of Segment";
CM_ SG_ 1173 NAVI_SpeedLimit "Information for Current Link Speed Limit expressed as km/h or mph";
CM_ SG_ 1173 NAVI_RoadClass "Information for Road Class";
CM_ SG_ 1173 RoomLampMode "Room lampt on/off connected with car door open/close";
CM_ SG_ 1173 AC_Chg_Cur_Set "AC Charging Current Setting";
CM_ SG_ 1173 IVI_SWC_ACCMode_Sta "IVI Steering Wheel ACC Mode";
CM_ SG_ 1173 SOC_Limit_Set "SOC Charging Limitation Setting";
CM_ SG_ 1173 CDL_Lock_Butt "Central Door Lock_LOCK_Button";
CM_ SG_ 1173 CDL_Unlock_Butt "Central Door Lock_UNLOCK_Button";
CM_ SG_ 1173 SOC_ADJ_BUTT "SOC Charging Limitation Adjust Button";
CM_ SG_ 1173 Roll_Mode_SW_Cmd "Roll Mode Switch command";
CM_ SG_ 1173 TCS_SW_Cmd "TCS Switch command";
CM_ SG_ 1173 SLIF_BUTT "SLIF  ON/OFF Buttom";
CM_ SG_ 1173 Roll_Eng_Mode "Roll Engine Mode";
CM_ SG_ 1173 IVI_LVChrgFuncSW "IVI LV Charging function switch";
CM_ SG_ 1173 IVI_PwrLockSW "IVI Power State Lock Switch";
CM_ SG_ 1173 IVI_CoastDwSW "IVI Coastdown switch";
CM_ SG_ 1173 IVI_ActvDmpDisabSW "IVI Active Damping Disable Switch";
CM_ SG_ 1173 AVM_parking_cancel "auto parking cancel";
CM_ SG_ 1173 AVM_parking_excute "confirm and start to auto parking";
CM_ SG_ 1173 AVM_OFF_Rec_Butt "AVM KEYOFF Recording Button";
CM_ SG_ 1173 Approach_Unlock_SW "Unlock when approaching Switch";
CM_ SG_ 1173 IVI_ISA_OffsetSpd "IVI ISA Offset speed";
CM_ SG_ 1173 IVI_PTG_Open_Height "IVI 'PTG Open Height' Menu Status";
CM_ SG_ 1173 IVI_ChargePortSW_Sta "IVI Charge Port Switch";
CM_ SG_ 1173 IVI_SLIF_Warning_Sta "IVI SLIF Warning Status";
CM_ SG_ 1173 IVI_ACC_Adaptive_Sta "IVI ACC Adaptive Mode";
CM_ SG_ 1173 IVI_PSEAT_Slide_Cmd "IVI Passenger Seat Slide Adjustment";
CM_ SG_ 1173 IVI_DSEAT_FroEdge_Height_Cmd "IVI Driver Seat Front Edge Height Adjustment";
CM_ SG_ 1173 IVI_DSEAT_Height_Cmd "IVI Driver Seat Height Adjustment";
CM_ SG_ 1173 IVI_DSEAT_Recline_Cmd "IVI Driver Seat Recline Adjustment";
CM_ SG_ 1173 IVI_PSEAT_Recline_Cmd "IVI Passenger Seat Recline Adjustment";
CM_ SG_ 1173 IVI_DSEAT_Memory_OPTCLS_Sta "IVI Driver Seat Memory Options Closed ";
CM_ SG_ 1173 IVI_SetTempZon2_Sta "IVI Temperature setpoint? for HVAC Zone 2";
CM_ SG_ 1173 IVI_AirIntZ3_Cmd "IVI AiR intetion Zone 3 Command";
CM_ SG_ 1173 IVI_SetTempZon1_Sta "IVI Temperature setpoint? for HVAC Zone 1 ";
CM_ SG_ 1173 IVI_DSEAT_Slide_Cmd "IVI Driver Seat Slide Adjustment";
CM_ SG_ 1173 IVI_DSEAT_Memory1_Sta "IVI Driver Seat Memory 1 Button";
CM_ SG_ 1173 IVI_DSEAT_Memory2_Sta "IVI Driver Seat Memory 2 Button";
CM_ SG_ 1173 DMS_Status "DMS Status";
CM_ SG_ 1173 DMS_Warning_Distraction "DMS Warning Distraction";
CM_ SG_ 1173 DMS_Warning_Fatigue "DMS Warning Fatigue";
CM_ SG_ 1173 DMS_Warning_Unresponsive "DMS Warning Unresponsive";
CM_ SG_ 1312 NM_IVI_Node_ID "Source Node Identifier";
CM_ SG_ 1312 NM_IVI_Rpt_Msg_Req "Repeat Message Request";
CM_ SG_ 1312 NM_IVI_CSB "NM Coordinator Sleep Bit";
CM_ SG_ 1312 NM_IVI_Active_WU "Active Wakeup Bit";
CM_ SG_ 1312 NM_IVI_PNI "Partial Network Information Bit (PNI)";
CM_ SG_ 1312 NM_IVI_ERROR_State "Defined Error states of the CAN Controller";
CM_ SG_ 1568 DiagRespFromIVI "Diagnostic Response from IVI";
CM_ SG_ 2362634068 CP2VAutoTracH "Automatic traction help (load transfer)";
CM_ SG_ 2362634068 CP2VKneeReqLSide "Kneeling request left side";
CM_ SG_ 2362634068 CP2VKneeReqRSide "Kneeling request right side";
CM_ SG_ 2362634068 CP2VKneeCtrlMReq "Kneeling control mode request";
CM_ SG_ 2362634068 CP2VNLvReqFA "Nominal level request front axle";
CM_ SG_ 2362634068 CP2VNLvReqRA "Nominal level request rear axle";
CM_ SG_ 2362634068 CP2VLvCtrlModeReq "Level control mode reques";
CM_ SG_ 2362634068 CP2VLA1PosCmd "Lift axle 1 position command";
CM_ SG_ 2362634068 CP2VLA2PosCmd "Lift axle 2 position command";
CM_ SG_ 2362634068 CP2VDamStiffReqFA "Damper stiffness request front axle";
CM_ SG_ 2362634068 CP2VDamStiffReqRA "Damper stiffness request rear axle";
CM_ SG_ 2362634068 CP2VDamStiffReqLA "Damper stiffness request tag/lift axle";
CM_ SG_ 2362634068 CP2VKneeReqFA "Kneeling request front axle";
CM_ SG_ 2362634068 CP2VKneeReqRA "Kneeling request rear axle";
CM_ SG_ 2147484162 FDC_VCU_DACStatus_Sta "DAC Status";
CM_ SG_ 2147484162 FDC_VCU_TUpASta_Sta "Take Up Assist Status";
CM_ SG_ 2147484162 FDC_BCM_WelcomeDemo_Sta "welcome demo";
CM_ SG_ 2147484162 FDC_BCM_TgateSWL_Sta "Right Tailgate Switch Status";
CM_ SG_ 2147484162 FDC_BCM_TgateSWR_Sta "Left Tailgate Switch Status";
CM_ SG_ 2566000691 T1_TPMS_RBOPressIndi "Right_Back_outside Wheel Pressure Warning Indicator";
CM_ SG_ 2566000691 T1_TPMS_LBOPressIndi "Left_Back_outside Wheel Pressure Warning Indicator";
CM_ SG_ 2566000691 T1_TPMS_RBIPressIndi "Right_Back_Inside Wheel Pressure Warning Indicator";
CM_ SG_ 2566000691 T1_TPMS_LBIPressIndi "Left_Back_Inside Wheel Pressure Warning Indicator";
CM_ SG_ 2566000691 T1_TPMS_RBOWheelTmpIndi "Right_Back_Outside Wheel Temperature Warning Indicator";
CM_ SG_ 2566000691 T1_TPMS_LBOWheelTmpIndi "Left_Back_Outside Wheel Temperature Warning Indicator";
CM_ SG_ 2566000691 T1_TPMS_RBIWheelTmpIndi "Right_Back_Inside Wheel Temperature Warning Indicator";
CM_ SG_ 2566000691 T1_TPMS_LBIWheelTmpIndi "Left_Back_Inside Wheel Temperature Warning Indicator";
CM_ SG_ 2566000691 T1_TPMS_RBOSensorFail "Right_Back_Outside Wheel Sensor Fail Indicator";
CM_ SG_ 2566000691 T1_TPMS_LBOSensorFail "Left_Back_Outside Wheel Sensor Fail Indicator";
CM_ SG_ 2566000691 T1_TPMS_RBISensorFail "Right_Back_Inside Wheel Sensor Fail Indicator";
CM_ SG_ 2566000691 T1_TPMS_LBISensorFail "Left_Back_Inside Wheel Sensor Fail Indicator";
CM_ SG_ 2566000691 T1_TPMS_RBOBatWarn "Right_Back_Outside Wheel Battery Warning";
CM_ SG_ 2566000691 T1_TPMS_LBOBatWarn "Left_Back_Outside Wheel Battery Warning";
CM_ SG_ 2566000691 T1_TPMS_RBIBatWarn "Right_Back_Inside Wheel Battery Warning";
CM_ SG_ 2566000691 T1_TPMS_LBIBatWarn "Left_Back_Inside Wheel Battery Warning";
CM_ SG_ 2566000691 T1_TPMS_TPMSExist "TPMS Exist";
CM_ SG_ 2566000691 T1_TPMS_TPMSHWVer "TPMS Hardware Version Number";
CM_ SG_ 2566000691 T1_TPMS_TPMSSWVer "TPMS Software Version Number";
CM_ SG_ 2566000691 T1_TPMS_RFPressIndi "Right_Forward Wheel Pressure Warning Indicator";
CM_ SG_ 2566000691 T1_TPMS_TPMSWarnIndi "TPMS Warning Indicator";
CM_ SG_ 2566000691 T1_TPMS_LFBatWarn "Left_Forward Wheel Battery Warning";
CM_ SG_ 2566000691 T1_TPMS_LFPressIndi "Left_Forward Wheel Pressure Warning Indicator";
CM_ SG_ 2566000691 T1_TPMS_LFSensorFail "Left_Forward Wheel Sensor Fail Indicator";
CM_ SG_ 2566000691 T1_TPMS_LFWheelTmpIndi "Left_Forward Wheel Temperature Warning Indicator";
CM_ SG_ 2566000691 T1_TPMS_RFBatWarn "Right_Forward Wheel Battery Warning";
CM_ SG_ 2566000691 T1_TPMS_RFSensorFail "Right_Forward Wheel Sensor Fail Indicator";
CM_ SG_ 2566000691 T1_TPMS_RFWheelTmpIndi "Right_Forward Wheel Temperature Warning Indicator";
CM_ SG_ 2566000947 T1_TPMS_MeterSpdFlag "Couting Flag for Speed Signal Lost";
CM_ SG_ 2566000947 T1_TPMS_RBOWheelDebug "Right_Back_Outside wheel debug";
CM_ SG_ 2566000947 T1_TPMS_RBOWheelPress "Rirht_Back_Outside Wheel Pressure";
CM_ SG_ 2566000947 T1_TPMS_RBIWheelDebug "Right_Back_Inside wheel debug";
CM_ SG_ 2566000947 T1_TPMS_RBIWheelPress "Rirht_Back_Inside Wheel Pressure";
CM_ SG_ 2566000947 T1_TPMS_LBOWheelDebug "Left_Back_Outside wheel debug";
CM_ SG_ 2566000947 T1_TPMS_LBOWheelPress "Left_Back_Outside Wheel Pressure";
CM_ SG_ 2566000947 T1_TPMS_LBIWheelDebug "Left_Back_Inside wheel debug";
CM_ SG_ 2566000947 T1_TPMS_LBIWheelPress "Left_Back_Inside Wheel Pressure";
CM_ SG_ 2566000947 T1_TPMS_LFWheelPress "Left_Forward Wheel Pressure";
CM_ SG_ 2566000947 T1_TPMS_RFWheelPress "Right_Forward Wheel Pressure";
CM_ SG_ 2566000947 T1_TPMS_LFWheelDebug "Left_Forward wheel debug";
CM_ SG_ 2566000947 T1_TPMS_RFWheelDebug "Right_Forward wheel debug";
CM_ SG_ 2566001203 T1_TPMS_RBOWheelTemp "Right_Back_Outside Temperature";
CM_ SG_ 2566001203 T1_TPMS_LBOWheelTemp "Left_Back_Outside Temperature";
CM_ SG_ 2566001203 T1_TPMS_RBIWheelTemp "Right_Back_Inside Temperature";
CM_ SG_ 2566001203 T1_TPMS_LBIWheelTemp "Left_Back_Inside Temperature";
CM_ SG_ 2566001203 T1_TPMS_LFWheelTemp "Left_Forward Temperature";
CM_ SG_ 2566001203 T1_TPMS_RFWheelTemp "Right_Forward Temperature";
CM_ SG_ 2566844752 EPB_ParkingBrake_Sta "ParkingBrakeSwitch";
CM_ SG_ 2566834768 EPB_ProtectLamp_Sta "ProtectLampStatus";
CM_ SG_ 2566834768 EPB_AmberWarningLamp_Sta "AmberWarningLampStatus";
CM_ SG_ 2566834768 EPB_RedStopLamp_Sta "RedStopLampState";
CM_ SG_ 2566834768 EPB_MalfunctionIndLamp_Sta "MalfunctionIndicatorLampStatus";
CM_ SG_ 2566834768 EPB_FlashProtectLamp_Cmd "FlashProtectLamp";
CM_ SG_ 2566834768 EPB_FlashAmberWarningLamp_Cmd "FlashAmberWarningLamp";
CM_ SG_ 2566834768 EPB_FlashRedStopLamp_Cmd "FlashRedStopLamp";
CM_ SG_ 2566834768 EPB_FlashMalfuncIndLamp_Cmd "FlashMalfuncIndicatorLamp";
CM_ SG_ 2566896720 EPB_ParkBrakeStateLamp_sta "ParkBrakeStateLamp";
CM_ SG_ 2566896720 EPB_BrakePedalActuationInd_cmd "BrakePedalActuationIndicator";
CM_ SG_ 2566896720 EPB_ParkBrake_Sta "ParkBrakeState";
CM_ SG_ 2566896720 EPB_HcuLeverPos_sta "HcuLeverPos";
CM_ SG_ 2566896720 EPB_SpringBrakeABSActive_sta "SpringBrakeABSActive";
CM_ SG_ 2566896720 EPB_ParkBrakeRelease_Sta "ParkBrakeReleaseState";
CM_ SG_ 2566896720 EPB_ParkBrkReleaseInhibitInd_Cmd "ParkBrakeReleaseInhibitInd";
CM_ SG_ 2566896720 EPB_ExtParkBrakeSystem_Sta "ExtParkBrakeSystemState";
CM_ SG_ 2566896720 EPB_HcuSwitch_Sta "HcuSwitchState";
CM_ SG_ 2566896720 EPB_ParkBrkLowAirIndication_Cmd "ParkBrakeLowAirIndication";
CM_ SG_ 2566827568 Z24_CHA_AirPressurePC3_Sta "Parking Tank Pressure";
CM_ SG_ 2566827568 Z24_CHA_AirPressureRC1_Sta "Rear Tank Pressure";
CM_ SG_ 2566827568 Z24_CHA_AirPressureFC2_Sta "Front Tank Pressure";
CM_ SG_ 2565865967 FDC_CHA_CACTempWarn_Sta "Chasis Air Compressor over Temperature warning";
CM_ SG_ 2565865967 FDC_CHA_CACPresWarn_Sta "Brake system low pressure/pressure sensor invalid warning";
CM_ SG_ 2566887584 IVI_D_ACSwitch_cmd "compressor on/off";
CM_ SG_ 2566887584 IVI_D_AirflowUpControl_cmd "Airflow upcontrol";
CM_ SG_ 2566887584 IVI_D_AirflowDownControl_cmd "Airflow Downcontrol";
CM_ SG_ 2566887584 IVI_D_TemperatureUpControl_cmd "Temperature up control";
CM_ SG_ 2566887584 IVI_D_TempDownControl_cmd "Temperature down control";
CM_ SG_ 2566887584 IVI_D_AutoSwitch_cmd "Auto switch";
CM_ SG_ 2566887584 IVI_D_MaxAirflowSwitch_cmd "Max Airflow Switch";
CM_ SG_ 2566887584 IVI_D_PowerSwitch_cmd "AC PowerSwitch";
CM_ SG_ 2566887584 IVI_RMirrorHeatSta_cmd "Mirror Heat start ";
CM_ SG_ 2566834735 ECASPLampSta "Diagnostic Message 1-
Protect lamp status";
CM_ SG_ 2566834735 ECASAWarmLampSta "Diagnostic Message 1-
Amber warning lamp status";
CM_ SG_ 2566834735 ECASRStopLampSta "Diagnostic Message 1-
Red stop lamp status";
CM_ SG_ 2566834735 ECASMFLampSta "Diagnostic Message 1-Malfunction indicator lamp status";
CM_ SG_ 2566834735 ECASFEngPtcLamp "Flash engine protect lamp";
CM_ SG_ 2566834735 ECASAWL "Flash engine amber warning lamp
(AWL)";
CM_ SG_ 2566834735 ECASRSL "Flash engine red stop lamp (RSL)";
CM_ SG_ 2566834735 ECASMIL "Flash engine malfunction indicator lamp (MIL)";
CM_ SG_ 2566834735 ECASSPN_1 "SPN, 8 least significant bits of SPN
(most significant at bit 8)";
CM_ SG_ 2566834735 ECASSPN_2 "SPN, second byte of SPN
(most significant at bit 8)";
CM_ SG_ 2566834735 ECASSPN_3 "SPN, 3 most significant bits of SPN
(most significant at bit 8)";
CM_ SG_ 2566834735 ECASFMI "FMI";
CM_ SG_ 2566834735 ECASSPNCNV "SPN conversion method";
CM_ SG_ 2566834735 ECASOcrCnt "Occurence count";
CM_ SG_ 2566887345 AC_Blower_lvl_sta "Blower_lever";
CM_ SG_ 2566887345 AC_D_ACOnDisplay_sta "Switch on";
CM_ SG_ 2566887345 AC_D_MaxAirflowDisplay_sta "MaxAirflowDisplay";
CM_ SG_ 2566887345 AC_D_PowerOnDisplay_cmd "PowerOnDisplay";
CM_ SG_ 2566887345 AC_Set_temp_sta "setting tempertaure";
CM_ SG_ 2566887345 AC_D_AutoOnDisplay_sta "AutoOnDisplay";
CM_ SG_ 2566831883 FASpeed "Front Axle Vehicle Speed(64256~65535=Error)";
CM_ SG_ 2566831883 RelaSpdFALWheel "The speed of the front axle, left wheel relative to the front axle speed, SPN 904.";
CM_ SG_ 2566831883 RelaSpdFARWheel "The speed of the front axle, right wheel relative to the front axle speed, SPN 904.";
CM_ SG_ 2566831883 RelaSpdRA1LWheel "The speed of the rear axle #1, left wheel relative to the front axle speed, SPN 904.";
CM_ SG_ 2566831883 RelaSpdRA1RWheel "The speed of the rear axle #1, right wheel relative to the front axle speed, SPN 904.";
CM_ SG_ 2566831883 RelaSpdRA2LWheel "The speed of the rear axle #2, left wheel relative to the front axle speed, SPN 904.";
CM_ SG_ 2566831883 RelaSpdRA2RWheel "The speed of the rear axle #2, right wheel relative to the front axle speed, SPN 904.";
CM_ SG_ 1175 IVI_CLBlower_Y_Sta "IVI Center Left Blower Y axis Status";
CM_ SG_ 1175 IVI_CLBlower_Z_Sta "IVI Center Left Blower Z axis Status";
CM_ SG_ 1175 IVI_CRBlower_Y_Sta "IVI Center Right Blower Y axis Status";
CM_ SG_ 1175 IVI_CRBlower_Z_Sta "IVI Center Right Blower Z axis Status";
CM_ SG_ 1175 IVI_DrBlower_Mode_Sta "IVI Driver Blower Mode Switch";
CM_ SG_ 1175 IVI_DrBlower_Y_Sta "IVI Driver Blower Y axis Status";
CM_ SG_ 1175 IVI_DrBlower_Z_Sta "IVI Driver Blower Z axis Status";
CM_ SG_ 1175 IVI_LSEATvent_Cmd "IVI FL SEAT Vent command";
CM_ SG_ 1175 IVI_MLFMost_Cmd "IVI ML SEAT Forward to Most command";
CM_ SG_ 1175 IVI_MLFootLift_Cmd "IVI ML Foot Lift command";
CM_ SG_ 1175 IVI_MLNapMode_Cmd "IVI ML SEAT Nap Mode command";
CM_ SG_ 1175 IVI_MLRecliner_Cmd "IVI ML SEAT Recliner command";
CM_ SG_ 1175 IVI_MLRestore_Cmd "IVI ML SEAT Restore command";
CM_ SG_ 1175 IVI_MLSEATvent_Cmd "IVI ML SEAT Vent command";
CM_ SG_ 1175 IVI_MLSeatLift_Cmd "IVI ML SEAT Lift command";
CM_ SG_ 1175 IVI_MLSldRestore_Cmd "IVI ML SEAT Slider Restore command";
CM_ SG_ 1175 IVI_MLSlider_Cmd "IVI ML SEAT Slider command";
CM_ SG_ 1175 IVI_MLZeroGravity_Cmd "IVI ML Zero Gravity command";
CM_ SG_ 1175 IVI_MRFMost_Cmd "IVI MR SEAT Forward to Most command";
CM_ SG_ 1175 IVI_MRFootLift_Cmd "IVI MR Foot Lift command";
CM_ SG_ 1175 IVI_MRNapMode_Cmd "IVI MR SEAT Nap Mode command";
CM_ SG_ 1175 IVI_MRRecliner_Cmd "IVI MR SEAT Recliner command";
CM_ SG_ 1175 IVI_MRRestore_Cmd "IVI MR SEAT Restore command";
CM_ SG_ 1175 IVI_MRSEATvent_Cmd "IVI MR SEAT Vent command";
CM_ SG_ 1175 IVI_MRSeatLift_Cmd "IVI MR SEAT Lift command";
CM_ SG_ 1175 IVI_MRSldRestore_Cmd "IVI MR SEAT Slider Restore command";
CM_ SG_ 1175 IVI_MRSlider_Cmd "IVI MR SEAT Slider command";
CM_ SG_ 1175 IVI_MRZeroGravity_Cmd "IVI MR Zero Gravity command";
CM_ SG_ 1175 IVI_PsBlower_Mode_Sta "IVI Passenger Blower Mode Switch";
CM_ SG_ 1175 IVI_PsBlower_Y_Sta "IVI Passenger Blower Y axis Status";
CM_ SG_ 1175 IVI_PsBlower_Z_Sta "IVI Passenger Blower Z axis Status";
CM_ SG_ 1175 IVI_RSEATvent_Cmd "IVI FR SEAT Vent command";
CM_ SG_ 2566838066 Door_Fr_DoorEmergency_sta "Door Emergency";
CM_ SG_ 2566838066 Door_Fr_Doorposition_sta "Door position";
CM_ SG_ 2566838066 Door_Fr_Dooroperation_sta "Door operation";

BA_DEF_ BO_ "GenMsgSendType" ENUM "Cycle","NoMsgSendType","IfActive","Event","CA","CE";
BA_DEF_ BO_ "GenMsgNrOfRepetition" INT 0 0;
BA_DEF_ BO_ "GenMsgILSupport" ENUM "No","Yes";
BA_DEF_ BO_ "GenMsgDelayTime" INT 0 0;
BA_DEF_ BO_ "GenMsgCycleTimeFast" INT 0 0;
BA_DEF_ BO_ "GenMsgCycleTime" INT 0 0;
BA_DEF_ BO_ "DiagResponse" ENUM "No","Yes";
BA_DEF_ BO_ "DiagRequest" ENUM "No","Yes";
BA_DEF_ BO_ "NmMessage" ENUM "No","Yes";
BA_DEF_ BO_ "VFrameFormat" ENUM "StandardCAN","ExtendedCAN","reserved","reserved","reserved","reserved","reserved","reserved","reserved","reserved","reserved","reserved","reserved","reserved","StandardCAN_FD","ExtendedCAN_FD";
BA_DEF_ BO_ "DoIPLogicalAddress" STRING ;
BA_DEF_ BO_ "CANFD_BRS" ENUM "0","1";
BA_DEF_ BO_ "GenMsgRequestable" INT 0 1;
BA_DEF_ SG_ "GenSigInvalidValue" HEX 0 0;
BA_DEF_ SG_ "GenSigStartValue" HEX 0 0;
BA_DEF_ SG_ "GenSigInactiveValue" HEX 0 0;
BA_DEF_ SG_ "GenSigRoutingTimeoutValue_String" STRING ;
BA_DEF_ SG_ "GenSigRoutingTimeoutValue" HEX 0 0;
BA_DEF_ SG_ "GenSigSendType" ENUM "Cycle","OnWrite","OnWriteWithRepetition","OnChange","OnChangeWithRepetition","IfActive","IfActiveWithRepetition","NoSigSendType","vector_leerstring";
BA_DEF_ SG_ "SigType" ENUM "Default","Range","RangeSigned","ASCII","Discrete","Control","ReferencePGN","DTC","StringDelimiter","StringLength","StringLengthControl","MessageCounter","MessageChecksum";
BA_DEF_ SG_ "GenSigILSupport" ENUM "No","Yes";
BA_DEF_DEF_ "GenMsgSendType" "Cycle";
BA_DEF_DEF_ "GenMsgNrOfRepetition" 0;
BA_DEF_DEF_ "GenMsgILSupport" "Yes";
BA_DEF_DEF_ "GenMsgDelayTime" 0;
BA_DEF_DEF_ "GenMsgCycleTimeFast" 0;
BA_DEF_DEF_ "GenMsgCycleTime" 100;
BA_DEF_DEF_ "DiagResponse" "No";
BA_DEF_DEF_ "DiagRequest" "No";
BA_DEF_DEF_ "NmMessage" "No";
BA_DEF_DEF_ "VFrameFormat" "StandardCAN";
BA_DEF_DEF_ "DoIPLogicalAddress" "";
BA_DEF_DEF_ "CANFD_BRS" "1";
BA_DEF_DEF_ "GenMsgRequestable" 1;
BA_DEF_DEF_ "GenSigInvalidValue" 0;
BA_DEF_DEF_ "GenSigStartValue" 0;
BA_DEF_DEF_ "GenSigInactiveValue" 0;
BA_DEF_DEF_ "GenSigRoutingTimeoutValue_String" "";
BA_DEF_DEF_ "GenSigRoutingTimeoutValue" 0;
BA_DEF_DEF_ "GenSigSendType" "Cycle";
BA_DEF_DEF_ "SigType" "Default";
BA_DEF_DEF_ "GenSigILSupport" "Yes";
BA_ "GenMsgCycleTimeFast" BO_ 2365479471 100;
BA_ "VFrameFormat" BO_ 2365479471 1;
BA_ "GenMsgCycleTimeFast" BO_ 2550255781 100;
BA_ "VFrameFormat" BO_ 2550255781 1;
BA_ "VFrameFormat" BO_ 2565865739 1;
BA_ "GenMsgCycleTime" BO_ 513 20;
BA_ "VFrameFormat" BO_ 513 14;
BA_ "GenMsgNrOfRepetition" BO_ 602 1;
BA_ "GenMsgCycleTimeFast" BO_ 602 10;
BA_ "GenMsgSendType" BO_ 602 5;
BA_ "VFrameFormat" BO_ 602 14;
BA_ "GenMsgNrOfRepetition" BO_ 1168 1;
BA_ "GenMsgCycleTime" BO_ 1168 500;
BA_ "GenMsgCycleTimeFast" BO_ 1168 50;
BA_ "GenMsgSendType" BO_ 1168 5;
BA_ "VFrameFormat" BO_ 1168 14;
BA_ "GenMsgNrOfRepetition" BO_ 1173 1;
BA_ "GenMsgCycleTime" BO_ 1173 200;
BA_ "GenMsgDelayTime" BO_ 1173 5;
BA_ "GenMsgCycleTimeFast" BO_ 1173 20;
BA_ "GenMsgSendType" BO_ 1173 5;
BA_ "VFrameFormat" BO_ 1173 14;
BA_ "GenMsgCycleTime" BO_ 1312 0;
BA_ "NmMessage" BO_ 1312 1;
BA_ "GenMsgSendType" BO_ 1312 3;
BA_ "GenMsgCycleTime" BO_ 1568 0;
BA_ "DiagResponse" BO_ 1568 1;
BA_ "GenMsgSendType" BO_ 1568 3;
BA_ "VFrameFormat" BO_ 1568 14;
BA_ "DoIPLogicalAddress" BO_ 1568 "0x06A0";
BA_ "VFrameFormat" BO_ 2362634068 1;
BA_ "GenMsgNrOfRepetition" BO_ 2147484162 10;
BA_ "GenMsgSendType" BO_ 2147484162 5;
BA_ "VFrameFormat" BO_ 2147484162 15;
BA_ "GenMsgCycleTime" BO_ 2566000691 1000;
BA_ "VFrameFormat" BO_ 2566000691 1;
BA_ "GenMsgCycleTime" BO_ 2566000947 1000;
BA_ "VFrameFormat" BO_ 2566000947 1;
BA_ "GenMsgCycleTime" BO_ 2566001203 1000;
BA_ "VFrameFormat" BO_ 2566001203 1;
BA_ "VFrameFormat" BO_ 2566844752 1;
BA_ "GenMsgCycleTime" BO_ 2566834768 1000;
BA_ "VFrameFormat" BO_ 2566834768 15;
BA_ "GenMsgCycleTime" BO_ 2566896720 20;
BA_ "VFrameFormat" BO_ 2566896720 1;
BA_ "GenMsgNrOfRepetition" BO_ 515 1;
BA_ "GenMsgCycleTimeFast" BO_ 515 10;
BA_ "GenMsgSendType" BO_ 515 5;
BA_ "VFrameFormat" BO_ 515 14;
BA_ "GenMsgCycleTime" BO_ 2566827568 1000;
BA_ "VFrameFormat" BO_ 2566827568 1;
BA_ "VFrameFormat" BO_ 2565865967 1;
BA_ "GenMsgCycleTime" BO_ 2566887584 50;
BA_ "VFrameFormat" BO_ 2566887584 1;
BA_ "GenMsgCycleTime" BO_ 2566834735 0;
BA_ "GenMsgSendType" BO_ 2566834735 3;
BA_ "VFrameFormat" BO_ 2566834735 1;
BA_ "GenMsgCycleTime" BO_ 2566887345 200;
BA_ "VFrameFormat" BO_ 2566887345 1;
BA_ "VFrameFormat" BO_ 2566831883 15;
BA_ "GenMsgNrOfRepetition" BO_ 1175 1;
BA_ "GenMsgCycleTime" BO_ 1175 500;
BA_ "GenMsgSendType" BO_ 1175 5;
BA_ "VFrameFormat" BO_ 1175 14;
BA_ "GenMsgNrOfRepetition" BO_ 2566838066 10;
BA_ "GenMsgCycleTimeFast" BO_ 2566838066 10;
BA_ "GenMsgSendType" BO_ 2566838066 5;
BA_ "VFrameFormat" BO_ 2566838066 1;
BA_ "GenSigRoutingTimeoutValue_String" SG_ 2365479471 ASC1NomLvFAxis "0x8";
BA_ "GenSigRoutingTimeoutValue" SG_ 2365479471 ASC1NomLvFAxis 8;
BA_ "GenSigRoutingTimeoutValue_String" SG_ 2365479471 ASC1NomLvRAxis "0x8";
BA_ "GenSigRoutingTimeoutValue" SG_ 2365479471 ASC1NomLvRAxis 8;
BA_ "GenSigRoutingTimeoutValue_String" SG_ 2365479471 ASC1LowCtrlFAxis "0x2";
BA_ "GenSigRoutingTimeoutValue" SG_ 2365479471 ASC1LowCtrlFAxis 2;
BA_ "GenSigRoutingTimeoutValue_String" SG_ 2365479471 ASC1LowCtrlRAxis "0x2";
BA_ "GenSigRoutingTimeoutValue" SG_ 2365479471 ASC1LowCtrlRAxis 2;
BA_ "GenSigRoutingTimeoutValue_String" SG_ 2365479471 ASC1LiftCtrlFAxis "0x2";
BA_ "GenSigRoutingTimeoutValue" SG_ 2365479471 ASC1LiftCtrlFAxis 2;
BA_ "GenSigRoutingTimeoutValue_String" SG_ 2365479471 ASC1LiftCtrlRAxis "0x2";
BA_ "GenSigRoutingTimeoutValue" SG_ 2365479471 ASC1LiftCtrlRAxis 2;
BA_ "GenSigRoutingTimeoutValue_String" SG_ 2365479471 ASC1KneelingInfo "0x5";
BA_ "GenSigRoutingTimeoutValue" SG_ 2365479471 ASC1KneelingInfo 5;
BA_ "GenSigRoutingTimeoutValue_String" SG_ 2365479471 ASC1LvCtrlM "0x9";
BA_ "GenSigRoutingTimeoutValue" SG_ 2365479471 ASC1LvCtrlM 9;
BA_ "GenSigRoutingTimeoutValue_String" SG_ 2365479471 SADev "0x2";
BA_ "GenSigRoutingTimeoutValue" SG_ 2365479471 SADev 2;
BA_ "GenSigRoutingTimeoutValue_String" SG_ 2365479471 VehMotion "0x2";
BA_ "GenSigRoutingTimeoutValue" SG_ 2365479471 VehMotion 2;
BA_ "GenSigRoutingTimeoutValue_String" SG_ 2365479471 FABumpR "0x2";
BA_ "GenSigRoutingTimeoutValue" SG_ 2365479471 FABumpR 2;
BA_ "GenSigRoutingTimeoutValue_String" SG_ 2365479471 RABumpR "0x2";
BA_ "GenSigRoutingTimeoutValue" SG_ 2365479471 RABumpR 2;
BA_ "GenSigRoutingTimeoutValue_String" SG_ 2365479471 LA2Pos "0x2";
BA_ "GenSigRoutingTimeoutValue" SG_ 2365479471 LA2Pos 2;
BA_ "GenSigRoutingTimeoutValue_String" SG_ 2365479471 SuspenRmCtrl1 "0x2";
BA_ "GenSigRoutingTimeoutValue" SG_ 2365479471 SuspenRmCtrl1 2;
BA_ "GenSigRoutingTimeoutValue_String" SG_ 2365479471 SuspenRmCtrl2 "0x2";
BA_ "GenSigRoutingTimeoutValue" SG_ 2365479471 SuspenRmCtrl2 2;
BA_ "GenSigRoutingTimeoutValue_String" SG_ 2365479471 SuspCtrlrefuInfo "0x7";
BA_ "GenSigRoutingTimeoutValue" SG_ 2365479471 SuspCtrlrefuInfo 7;
BA_ "GenSigInvalidValue" SG_ 2550255781 EHPSErrLv 5;
BA_ "GenSigRoutingTimeoutValue_String" SG_ 2550255781 EHPSErrLv "0x5";
BA_ "GenSigRoutingTimeoutValue" SG_ 2550255781 EHPSErrLv 5;
BA_ "GenSigRoutingTimeoutValue_String" SG_ 2550255781 EHPSEnSta "0x3";
BA_ "GenSigRoutingTimeoutValue" SG_ 2550255781 EHPSEnSta 3;
BA_ "GenSigRoutingTimeoutValue_String" SG_ 2550255781 EHPSHVILSig "0x1";
BA_ "GenSigRoutingTimeoutValue" SG_ 2550255781 EHPSHVILSig 1;
BA_ "GenSigInvalidValue" SG_ 2565865739 ASREngCtrlAtc 3;
BA_ "GenSigRoutingTimeoutValue_String" SG_ 2565865739 ASREngCtrlAtc "0x3";
BA_ "GenSigRoutingTimeoutValue" SG_ 2565865739 ASREngCtrlAtc 3;
BA_ "GenSigInvalidValue" SG_ 2565865739 ASRBrakeCtrlAtc 3;
BA_ "GenSigRoutingTimeoutValue_String" SG_ 2565865739 ASRBrakeCtrlAtc "0x3";
BA_ "GenSigRoutingTimeoutValue" SG_ 2565865739 ASRBrakeCtrlAtc 3;
BA_ "GenSigInvalidValue" SG_ 2565865739 AntiLBrakABSAct 3;
BA_ "GenSigRoutingTimeoutValue_String" SG_ 2565865739 AntiLBrakABSAct "0x3";
BA_ "GenSigRoutingTimeoutValue" SG_ 2565865739 AntiLBrakABSAct 3;
BA_ "GenSigInvalidValue" SG_ 2565865739 EBSBrakeSw 3;
BA_ "GenSigRoutingTimeoutValue_String" SG_ 2565865739 EBSBrakeSw "0x2";
BA_ "GenSigRoutingTimeoutValue" SG_ 2565865739 EBSBrakeSw 2;
BA_ "GenSigInvalidValue" SG_ 2565865739 BrakePedalPos 251;
BA_ "GenSigRoutingTimeoutValue_String" SG_ 2565865739 BrakePedalPos "0xFB";
BA_ "GenSigRoutingTimeoutValue" SG_ 2565865739 BrakePedalPos 251;
BA_ "GenSigInvalidValue" SG_ 2565865739 ABSOffroadSw 3;
BA_ "GenSigRoutingTimeoutValue_String" SG_ 2565865739 ABSOffroadSw "0x2";
BA_ "GenSigRoutingTimeoutValue" SG_ 2565865739 ABSOffroadSw 2;
BA_ "GenSigInvalidValue" SG_ 2565865739 ASROffroadSw 3;
BA_ "GenSigRoutingTimeoutValue_String" SG_ 2565865739 ASROffroadSw "0x2";
BA_ "GenSigRoutingTimeoutValue" SG_ 2565865739 ASROffroadSw 2;
BA_ "GenSigInvalidValue" SG_ 2565865739 ASRHillHolderSw 3;
BA_ "GenSigRoutingTimeoutValue_String" SG_ 2565865739 ASRHillHolderSw "0x2";
BA_ "GenSigRoutingTimeoutValue" SG_ 2565865739 ASRHillHolderSw 2;
BA_ "GenSigInvalidValue" SG_ 2565865739 TractCtrlOvrSw 3;
BA_ "GenSigRoutingTimeoutValue_String" SG_ 2565865739 TractCtrlOvrSw "0x2";
BA_ "GenSigRoutingTimeoutValue" SG_ 2565865739 TractCtrlOvrSw 2;
BA_ "GenSigInvalidValue" SG_ 2565865739 AcltrInterlockSw 3;
BA_ "GenSigRoutingTimeoutValue_String" SG_ 2565865739 AcltrInterlockSw "0x2";
BA_ "GenSigRoutingTimeoutValue" SG_ 2565865739 AcltrInterlockSw 2;
BA_ "GenSigInvalidValue" SG_ 2565865739 EngDerateSw 3;
BA_ "GenSigRoutingTimeoutValue_String" SG_ 2565865739 EngDerateSw "0x2";
BA_ "GenSigRoutingTimeoutValue" SG_ 2565865739 EngDerateSw 2;
BA_ "GenSigInvalidValue" SG_ 2565865739 EngAuxShutdownSw 3;
BA_ "GenSigRoutingTimeoutValue_String" SG_ 2565865739 EngAuxShutdownSw "0x2";
BA_ "GenSigRoutingTimeoutValue" SG_ 2565865739 EngAuxShutdownSw 2;
BA_ "GenSigInvalidValue" SG_ 2565865739 RmAccelEnSw 3;
BA_ "GenSigRoutingTimeoutValue_String" SG_ 2565865739 RmAccelEnSw "0x2";
BA_ "GenSigRoutingTimeoutValue" SG_ 2565865739 RmAccelEnSw 2;
BA_ "GenSigInvalidValue" SG_ 2565865739 ABSFullyOper 3;
BA_ "GenSigRoutingTimeoutValue_String" SG_ 2565865739 ABSFullyOper "0x3";
BA_ "GenSigRoutingTimeoutValue" SG_ 2565865739 ABSFullyOper 3;
BA_ "GenSigRoutingTimeoutValue_String" SG_ 2565865739 ATCASRInfoSig "0x2";
BA_ "GenSigRoutingTimeoutValue" SG_ 2565865739 ATCASRInfoSig 2;
BA_ "GenSigInvalidValue" SG_ 2565865739 HaltBrakeSw 3;
BA_ "GenSigRoutingTimeoutValue_String" SG_ 2565865739 HaltBrakeSw "0x2";
BA_ "GenSigRoutingTimeoutValue" SG_ 2565865739 HaltBrakeSw 2;
BA_ "GenSigInvalidValue" SG_ 602 METER_KPH_Calcu 255;
BA_ "GenSigRoutingTimeoutValue_String" SG_ 602 METER_KPH_Calcu "0xFF";
BA_ "GenSigRoutingTimeoutValue" SG_ 602 METER_KPH_Calcu 255;
BA_ "GenSigInvalidValue" SG_ 602 METER_MPH_Calcu 255;
BA_ "GenSigInvalidValue" SG_ 602 METER_KPH_Real 4095;
BA_ "GenSigInvalidValue" SG_ 602 METER_MPH_Real 4095;
BA_ "GenSigInvalidValue" SG_ 602 Averaged_vehspeed 1023;
BA_ "GenSigInvalidValue" SG_ 602 AVGPwrConsumption 65535;
BA_ "GenSigStartValue" SG_ 602 AVGPwrConsumption 9999;
BA_ "GenSigInvalidValue" SG_ 602 APCforDTE 65535;
BA_ "GenSigStartValue" SG_ 602 APCforDTE 9999;
BA_ "GenSigInvalidValue" SG_ 602 AvailableTrip 65535;
BA_ "GenSigSendType" SG_ 602 ParkBrake 3;
BA_ "GenSigSendType" SG_ 602 Charge 3;
BA_ "GenSigSendType" SG_ 602 LEDlitWarnReq 3;
BA_ "GenSigInvalidValue" SG_ 602 Spd_Crl_Mode 5;
BA_ "GenSigSendType" SG_ 602 Trip_B 3;
BA_ "GenSigSendType" SG_ 602 Trip_A 3;
BA_ "GenSigSendType" SG_ 602 ODOMETER 3;
BA_ "GenSigSendType" SG_ 1168 FCP_FrEvt_BtnSyncReq 3;
BA_ "GenSigSendType" SG_ 1168 FCP_MidEvt_BtnAutoReq 3;
BA_ "GenSigSendType" SG_ 1168 FCP_FrEvt_BtnAutoReq 3;
BA_ "GenSigSendType" SG_ 1168 FCP_FrEvt_BtnACReq 3;
BA_ "GenSigSendType" SG_ 1168 FCP_FrEvt_BtnACMaxReq 3;
BA_ "GenSigInvalidValue" SG_ 1168 VehACModReq 7;
BA_ "GenSigRoutingTimeoutValue_String" SG_ 1168 VehACModReq "0x7";
BA_ "GenSigRoutingTimeoutValue" SG_ 1168 VehACModReq 7;
BA_ "GenSigSendType" SG_ 1168 VehACModReq 3;
BA_ "GenSigSendType" SG_ 1168 LINKtoDrive 3;
BA_ "GenSigSendType" SG_ 1168 SmartEco_Mode_SW 3;
BA_ "GenSigSendType" SG_ 1168 OTA_CancelDL_Req 3;
BA_ "GenSigSendType" SG_ 1168 IVI_OTA_Upd_Sta 3;
BA_ "GenSigSendType" SG_ 1168 OTA_UpdStart_Req 3;
BA_ "GenSigSendType" SG_ 1168 OTA_SuspendDL_Req 3;
BA_ "GenSigSendType" SG_ 1168 OTA_DL_Req 3;
BA_ "GenSigSendType" SG_ 1168 AmbLigh_SafetyAlert_SW 3;
BA_ "GenSigSendType" SG_ 1168 AmbLigh_LowBatAlert_SW 3;
BA_ "GenSigSendType" SG_ 1168 AmbLight_WlcmLight_SW 3;
BA_ "GenSigSendType" SG_ 1168 AmbLight_DimInDark_SW 3;
BA_ "GenSigSendType" SG_ 1168 AmbLight_SW 3;
BA_ "GenSigSendType" SG_ 1168 OpenDrOpenWdo_SW 3;
BA_ "GenSigSendType" SG_ 1168 Upd_Countdown_Cancel 3;
BA_ "GenSigSendType" SG_ 1168 Upd_Countdown_Skip 3;
BA_ "GenSigInvalidValue" SG_ 1168 AmbLightColorSet 127;
BA_ "GenSigStartValue" SG_ 1168 AmbLightColorSet 64;
BA_ "GenSigRoutingTimeoutValue_String" SG_ 1168 AmbLightColorSet "0x7F";
BA_ "GenSigInactiveValue" SG_ 1168 AmbLightColorSet 64;
BA_ "GenSigRoutingTimeoutValue" SG_ 1168 AmbLightColorSet 127;
BA_ "GenSigSendType" SG_ 1168 AmbLightColorSet 3;
BA_ "GenSigSendType" SG_ 1168 Sched_OTA_wake 3;
BA_ "GenSigSendType" SG_ 1168 A2B_Node_sta 3;
BA_ "GenSigSendType" SG_ 1168 Sched_Chg_St_Time_Min 3;
BA_ "GenSigSendType" SG_ 1168 Sched_Chg_Day_Set 3;
BA_ "GenSigSendType" SG_ 1168 Re_Radio_Sta 3;
BA_ "GenSigInvalidValue" SG_ 1168 Sched_Chg_St_Time_HR 31;
BA_ "GenSigSendType" SG_ 1168 Sched_Chg_St_Time_HR 3;
BA_ "GenSigSendType" SG_ 1168 UserSet 3;
BA_ "GenSigSendType" SG_ 1168 Sched_Chg_End_Time_Min 3;
BA_ "GenSigInvalidValue" SG_ 1168 Sched_Chg_End_Time_HR 31;
BA_ "GenSigSendType" SG_ 1168 Sched_Chg_End_Time_HR 3;
BA_ "GenSigSendType" SG_ 1168 BrkAbn_GoReady_SW 3;
BA_ "GenSigSendType" SG_ 1168 OTA_CompNTFY_Pres 3;
BA_ "GenSigSendType" SG_ 1168 mFRD_link_Sta 3;
BA_ "GenSigRoutingTimeoutValue_String" SG_ 1168 IVI_Time_Check "0x0";
BA_ "GenSigRoutingTimeoutValue_String" SG_ 1168 IVI_Time_Second "0x0";
BA_ "GenSigSendType" SG_ 1168 PW_CLOSE_IMD 3;
BA_ "GenSigSendType" SG_ 1168 PW_CONTINUE_USE 3;
BA_ "GenSigRoutingTimeoutValue_String" SG_ 1168 IVI_Time_Minute "0x0";
BA_ "GenSigRoutingTimeoutValue_String" SG_ 1168 IVI_Time_Day "0x0";
BA_ "GenSigSendType" SG_ 1168 IVI_DelAccReq_Sta 3;
BA_ "GenSigRoutingTimeoutValue_String" SG_ 1168 IVI_Time_Hour "0x0";
BA_ "GenSigSendType" SG_ 1168 IVI_CreateAccReq_Sta 3;
BA_ "GenSigRoutingTimeoutValue_String" SG_ 1168 IVI_Time_Month "0x0";
BA_ "GenSigSendType" SG_ 1168 IVI_LinkKey_Sta 3;
BA_ "GenSigRoutingTimeoutValue_String" SG_ 1168 IVI_Time_Year "0x0";
BA_ "GenSigSendType" SG_ 1168 IVI_LinkAccReq_Sta 3;
BA_ "GenSigSendType" SG_ 1168 IVI_LinkAcc_Sta 3;
BA_ "GenSigSendType" SG_ 1168 IVI_FrTrunk_UnlockReq_Sta 3;
BA_ "GenSigSendType" SG_ 1168 IVI_CLWin_LockDoorSW_Sta 3;
BA_ "GenSigSendType" SG_ 1168 IVI_Lock_SoundSW_Sta 3;
BA_ "GenSigInvalidValue" SG_ 1168 AmbLightBrightnessSet 127;
BA_ "GenSigStartValue" SG_ 1168 AmbLightBrightnessSet 101;
BA_ "GenSigRoutingTimeoutValue_String" SG_ 1168 AmbLightBrightnessSet "0x7F";
BA_ "GenSigInactiveValue" SG_ 1168 AmbLightBrightnessSet 101;
BA_ "GenSigRoutingTimeoutValue" SG_ 1168 AmbLightBrightnessSet 127;
BA_ "GenSigSendType" SG_ 1168 AmbLightBrightnessSet 3;
BA_ "GenSigInvalidValue" SG_ 1168 IVI_Located_STA 3;
BA_ "GenSigStartValue" SG_ 1168 IVI_Located_STA 3;
BA_ "GenSigRoutingTimeoutValue_String" SG_ 1168 IVI_Located_STA "0x3";
BA_ "GenSigInactiveValue" SG_ 1168 IVI_Located_STA 3;
BA_ "GenSigRoutingTimeoutValue" SG_ 1168 IVI_Located_STA 3;
BA_ "GenSigSendType" SG_ 1168 IVI_Located_STA 3;
BA_ "GenSigRoutingTimeoutValue_String" SG_ 1168 IVI_AutoTheme_But_Sta "0x0";
BA_ "GenSigSendType" SG_ 1168 IVI_AutoTheme_But_Sta 3;
BA_ "GenSigRoutingTimeoutValue_String" SG_ 1168 IVI_NAVI_Foreground_Sta "0x0";
BA_ "GenSigSendType" SG_ 1168 IVI_NAVI_Foreground_Sta 3;
BA_ "GenSigSendType" SG_ 1168 IVI_HMI_Undefined_Sta 3;
BA_ "GenSigSendType" SG_ 1168 IVI_QuickRefresh_Sta 3;
BA_ "GenSigSendType" SG_ 1168 IVI_DMS_SW_Sta 3;
BA_ "GenSigSendType" SG_ 1168 IVI_AirRefresh_ByDMS_Sta 3;
BA_ "GenSigSendType" SG_ 1168 IVI_SWC_VibMode_Sta 3;
BA_ "GenSigSendType" SG_ 1168 IVI_sigScreenReq_Sta 3;
BA_ "GenSigSendType" SG_ 1168 IVI_DSEAT_anti_set_Sta 3;
BA_ "GenSigRoutingTimeoutValue_String" SG_ 1173 Perd_V2L "0x0";
BA_ "GenSigSendType" SG_ 1173 Perd_V2L 3;
BA_ "GenSigInvalidValue" SG_ 1173 SOC_V2LLimit 15;
BA_ "GenSigRoutingTimeoutValue_String" SG_ 1173 SOC_V2LLimit "0xF";
BA_ "GenSigRoutingTimeoutValue" SG_ 1173 SOC_V2LLimit 15;
BA_ "GenSigStartValue" SG_ 1173 Walkaway_Lock_SW 1;
BA_ "GenSigRoutingTimeoutValue_String" SG_ 1173 Walkaway_Lock_SW "0x0";
BA_ "GenSigSendType" SG_ 1173 Walkaway_Lock_SW 3;
BA_ "GenSigStartValue" SG_ 1173 FalseNPrevent_SW 1;
BA_ "GenSigSendType" SG_ 1173 FalseNPrevent_SW 3;
BA_ "GenSigSendType" SG_ 1173 IVI_CreepSW_Req 3;
BA_ "GenSigSendType" SG_ 1173 IVI_CfmTo_Rdy 3;
BA_ "GenSigRoutingTimeoutValue_String" SG_ 1173 IVI_Req_V2L "0x0";
BA_ "GenSigSendType" SG_ 1173 IVI_Req_V2L 3;
BA_ "GenSigRoutingTimeoutValue_String" SG_ 1173 IVI_PSEATHeater_Cmd "0x0";
BA_ "GenSigSendType" SG_ 1173 IVI_PSEATHeater_Cmd 3;
BA_ "GenSigRoutingTimeoutValue_String" SG_ 1173 IVI_DSEATHeater_Cmd "0x0";
BA_ "GenSigSendType" SG_ 1173 IVI_DSEATHeater_Cmd 3;
BA_ "GenSigRoutingTimeoutValue_String" SG_ 1173 Light_ShowStop_Req "0x0";
BA_ "GenSigSendType" SG_ 1173 Light_ShowStop_Req 3;
BA_ "GenSigRoutingTimeoutValue_String" SG_ 1173 Light_ShowStart_Req "0x0";
BA_ "GenSigSendType" SG_ 1173 Light_ShowStart_Req 3;
BA_ "GenSigRoutingTimeoutValue_String" SG_ 1173 WlcmLight_Mode "0x0";
BA_ "GenSigSendType" SG_ 1173 WlcmLight_Mode 3;
BA_ "GenSigSendType" SG_ 1173 IVI_SWC_LUndefined_Sta 3;
BA_ "GenSigSendType" SG_ 1173 IVI_SWC_RUndefined_Sta 3;
BA_ "GenSigInvalidValue" SG_ 1173 Sched_Chg_limit 31;
BA_ "GenSigStartValue" SG_ 1173 Sched_Chg_limit 25;
BA_ "GenSigRoutingTimeoutValue_String" SG_ 1173 Sched_Chg_limit "0x1F";
BA_ "GenSigRoutingTimeoutValue" SG_ 1173 Sched_Chg_limit 31;
BA_ "GenSigInvalidValue" SG_ 1173 METER_Malfunc_Sta 3;
BA_ "GenSigSendType" SG_ 1173 METER_Malfunc_Sta 3;
BA_ "GenSigSendType" SG_ 1173 sigFootReq 3;
BA_ "GenSigSendType" SG_ 1173 sigFaceReq 3;
BA_ "GenSigRoutingTimeoutValue_String" SG_ 1173 Sched_Chg_Start "0x0";
BA_ "GenSigSendType" SG_ 1173 Sched_Chg_Start 3;
BA_ "GenSigSendType" SG_ 1173 Sched_Chg_wake 3;
BA_ "GenSigRoutingTimeoutValue_String" SG_ 1173 Sched_Chg_butt "0x0";
BA_ "GenSigSendType" SG_ 1173 Sched_Chg_butt 3;
BA_ "GenSigRoutingTimeoutValue_String" SG_ 1173 Sched_Chg_Stop "0x0";
BA_ "GenSigSendType" SG_ 1173 Sched_Chg_Stop 3;
BA_ "GenSigInvalidValue" SG_ 1173 L_RRD_ControlCommand 127;
BA_ "GenSigStartValue" SG_ 1173 L_RRD_ControlCommand 127;
BA_ "GenSigRoutingTimeoutValue_String" SG_ 1173 L_RRD_ControlCommand "0x7F";
BA_ "GenSigInactiveValue" SG_ 1173 L_RRD_ControlCommand 127;
BA_ "GenSigRoutingTimeoutValue" SG_ 1173 L_RRD_ControlCommand 127;
BA_ "GenSigRoutingTimeoutValue_String" SG_ 1173 IVI_Start_Chg_req "0x0";
BA_ "GenSigSendType" SG_ 1173 IVI_Start_Chg_req 3;
BA_ "GenSigInvalidValue" SG_ 1173 L_RLD_ControlCommand 127;
BA_ "GenSigStartValue" SG_ 1173 L_RLD_ControlCommand 127;
BA_ "GenSigRoutingTimeoutValue_String" SG_ 1173 L_RLD_ControlCommand "0x7F";
BA_ "GenSigInactiveValue" SG_ 1173 L_RLD_ControlCommand 127;
BA_ "GenSigRoutingTimeoutValue" SG_ 1173 L_RLD_ControlCommand 127;
BA_ "GenSigRoutingTimeoutValue_String" SG_ 1173 IVI_Stop_Chg_req "0x0";
BA_ "GenSigSendType" SG_ 1173 IVI_Stop_Chg_req 3;
BA_ "GenSigInvalidValue" SG_ 1173 L_Pas_ControlCommand 127;
BA_ "GenSigStartValue" SG_ 1173 L_Pas_ControlCommand 127;
BA_ "GenSigRoutingTimeoutValue_String" SG_ 1173 L_Pas_ControlCommand "0x7F";
BA_ "GenSigInactiveValue" SG_ 1173 L_Pas_ControlCommand 127;
BA_ "GenSigRoutingTimeoutValue" SG_ 1173 L_Pas_ControlCommand 127;
BA_ "GenSigRoutingTimeoutValue_String" SG_ 1173 IVI_Unlock_Chg_req "0x0";
BA_ "GenSigSendType" SG_ 1173 IVI_Unlock_Chg_req 3;
BA_ "GenSigInvalidValue" SG_ 1173 L_Drv_ControlCommand 127;
BA_ "GenSigStartValue" SG_ 1173 L_Drv_ControlCommand 127;
BA_ "GenSigRoutingTimeoutValue_String" SG_ 1173 L_Drv_ControlCommand "0x7F";
BA_ "GenSigInactiveValue" SG_ 1173 L_Drv_ControlCommand 127;
BA_ "GenSigRoutingTimeoutValue" SG_ 1173 L_Drv_ControlCommand 127;
BA_ "GenSigSendType" SG_ 1173 TPMS_Cali_Butt 3;
BA_ "GenSigSendType" SG_ 1173 sigSetTempZon1Req 3;
BA_ "GenSigSendType" SG_ 1173 sigHvacFrontReq 3;
BA_ "GenSigSendType" SG_ 1173 sigDfrstReq 3;
BA_ "GenSigSendType" SG_ 1173 sigSetTempZon2Req 3;
BA_ "GenSigSendType" SG_ 1173 sigRecircReq 3;
BA_ "GenSigSendType" SG_ 1173 sigHvacReq 3;
BA_ "GenSigInvalidValue" SG_ 1173 AEB_BUTT 2;
BA_ "GenSigRoutingTimeoutValue_String" SG_ 1173 AEB_BUTT "0x2";
BA_ "GenSigRoutingTimeoutValue" SG_ 1173 AEB_BUTT 2;
BA_ "GenSigSendType" SG_ 1173 AEB_BUTT 3;
BA_ "GenSigSendType" SG_ 1173 sigSetTempZon3Req 3;
BA_ "GenSigInvalidValue" SG_ 1173 sigAirIntenZon3Req 15;
BA_ "GenSigRoutingTimeoutValue_String" SG_ 1173 sigAirIntenZon3Req "0xF";
BA_ "GenSigRoutingTimeoutValue" SG_ 1173 sigAirIntenZon3Req 15;
BA_ "GenSigSendType" SG_ 1173 sigAirIntenZon3Req 3;
BA_ "GenSigInvalidValue" SG_ 1173 sigAirIntenZon1Req 15;
BA_ "GenSigRoutingTimeoutValue_String" SG_ 1173 sigAirIntenZon1Req "0xF";
BA_ "GenSigRoutingTimeoutValue" SG_ 1173 sigAirIntenZon1Req 15;
BA_ "GenSigSendType" SG_ 1173 sigAirIntenZon1Req 3;
BA_ "GenSigInvalidValue" SG_ 1173 BSDMute_BUTT 2;
BA_ "GenSigRoutingTimeoutValue_String" SG_ 1173 BSDMute_BUTT "0x2";
BA_ "GenSigRoutingTimeoutValue" SG_ 1173 BSDMute_BUTT 2;
BA_ "GenSigSendType" SG_ 1173 BSDMute_BUTT 3;
BA_ "GenSigInvalidValue" SG_ 1173 sigWindDirZon3Req 7;
BA_ "GenSigStartValue" SG_ 1173 sigWindDirZon3Req 7;
BA_ "GenSigRoutingTimeoutValue_String" SG_ 1173 sigWindDirZon3Req "0x7";
BA_ "GenSigInactiveValue" SG_ 1173 sigWindDirZon3Req 7;
BA_ "GenSigRoutingTimeoutValue" SG_ 1173 sigWindDirZon3Req 7;
BA_ "GenSigSendType" SG_ 1173 sigWindDirZon3Req 3;
BA_ "GenSigInvalidValue" SG_ 1173 FCWMute_BUTT 2;
BA_ "GenSigRoutingTimeoutValue_String" SG_ 1173 FCWMute_BUTT "0x2";
BA_ "GenSigRoutingTimeoutValue" SG_ 1173 FCWMute_BUTT 2;
BA_ "GenSigSendType" SG_ 1173 FCWMute_BUTT 3;
BA_ "GenSigInvalidValue" SG_ 1173 LKA_BUTT 2;
BA_ "GenSigRoutingTimeoutValue_String" SG_ 1173 LKA_BUTT "0x2";
BA_ "GenSigRoutingTimeoutValue" SG_ 1173 LKA_BUTT 2;
BA_ "GenSigSendType" SG_ 1173 LKA_BUTT 3;
BA_ "GenSigInvalidValue" SG_ 1173 ODAMute_BUTT 2;
BA_ "GenSigRoutingTimeoutValue_String" SG_ 1173 ODAMute_BUTT "0x2";
BA_ "GenSigRoutingTimeoutValue" SG_ 1173 ODAMute_BUTT 2;
BA_ "GenSigSendType" SG_ 1173 ODAMute_BUTT 3;
BA_ "GenSigInvalidValue" SG_ 1173 LDWMute_BUTT 2;
BA_ "GenSigRoutingTimeoutValue_String" SG_ 1173 LDWMute_BUTT "0x2";
BA_ "GenSigRoutingTimeoutValue" SG_ 1173 LDWMute_BUTT 2;
BA_ "GenSigSendType" SG_ 1173 LDWMute_BUTT 3;
BA_ "GenSigInvalidValue" SG_ 1173 NAVI_Speed_Limit_A 3;
BA_ "GenSigRoutingTimeoutValue_String" SG_ 1173 NAVI_Speed_Limit_A "0x3";
BA_ "GenSigRoutingTimeoutValue" SG_ 1173 NAVI_Speed_Limit_A 3;
BA_ "GenSigSendType" SG_ 1173 NAVI_Speed_Limit_A 3;
BA_ "GenSigSendType" SG_ 1173 Temperature_unit 3;
BA_ "GenSigRoutingTimeoutValue_String" SG_ 1173 Distance_unit "0x0";
BA_ "GenSigSendType" SG_ 1173 Distance_unit 3;
BA_ "GenSigInvalidValue" SG_ 1173 ESC_SW_Cmd 3;
BA_ "GenSigRoutingTimeoutValue_String" SG_ 1173 ESC_SW_Cmd "0x3";
BA_ "GenSigRoutingTimeoutValue" SG_ 1173 ESC_SW_Cmd 3;
BA_ "GenSigSendType" SG_ 1173 ESC_SW_Cmd 3;
BA_ "GenSigSendType" SG_ 1173 IVI_Panel_Act 3;
BA_ "GenSigSendType" SG_ 1173 sigHvacRearReq 3;
BA_ "GenSigSendType" SG_ 1173 Time_system 3;
BA_ "GenSigInvalidValue" SG_ 1173 IVI_Screen 63;
BA_ "GenSigRoutingTimeoutValue_String" SG_ 1173 IVI_Screen "0x3F";
BA_ "GenSigRoutingTimeoutValue" SG_ 1173 IVI_Screen 63;
BA_ "GenSigSendType" SG_ 1173 IVI_Screen 3;
BA_ "GenSigRoutingTimeoutValue_String" SG_ 1173 TurnSwTimeSet "0x3";
BA_ "GenSigRoutingTimeoutValue" SG_ 1173 TurnSwTimeSet 3;
BA_ "GenSigSendType" SG_ 1173 TurnSwTimeSet 3;
BA_ "GenSigInvalidValue" SG_ 1173 OFF_AC_MODE 7;
BA_ "GenSigRoutingTimeoutValue_String" SG_ 1173 OFF_AC_MODE "0x7";
BA_ "GenSigInactiveValue" SG_ 1173 OFF_AC_MODE 7;
BA_ "GenSigRoutingTimeoutValue" SG_ 1173 OFF_AC_MODE 7;
BA_ "GenSigSendType" SG_ 1173 OFF_AC_MODE 3;
BA_ "GenSigRoutingTimeoutValue_String" SG_ 1173 IVI_PW_Mode_Req "0x3";
BA_ "GenSigRoutingTimeoutValue" SG_ 1173 IVI_PW_Mode_Req 3;
BA_ "GenSigSendType" SG_ 1173 IVI_PW_Mode_Req 3;
BA_ "GenSigSendType" SG_ 1173 User_p_upload 3;
BA_ "GenSigSendType" SG_ 1173 CameraWrn 3;
BA_ "GenSigSendType" SG_ 1173 Wifi_Reset 3;
BA_ "GenSigInvalidValue" SG_ 1173 NAVI_Cam_Dist_info 255;
BA_ "GenSigRoutingTimeoutValue_String" SG_ 1173 NAVI_Cam_Dist_info "0xFF";
BA_ "GenSigRoutingTimeoutValue" SG_ 1173 NAVI_Cam_Dist_info 255;
BA_ "GenSigRoutingTimeoutValue_String" SG_ 1173 HeadLampSW "0x0";
BA_ "GenSigSendType" SG_ 1173 HeadLampSW 3;
BA_ "GenSigSendType" SG_ 1173 NAVI_State 3;
BA_ "GenSigSendType" SG_ 1173 Wifi_Sta_IVI_TBOX 3;
BA_ "GenSigInvalidValue" SG_ 1173 MFRD_N_Bright_Req 127;
BA_ "GenSigRoutingTimeoutValue_String" SG_ 1173 MFRD_N_Bright_Req "0x7F";
BA_ "GenSigRoutingTimeoutValue" SG_ 1173 MFRD_N_Bright_Req 127;
BA_ "GenSigSendType" SG_ 1173 MFRD_N_Bright_Req 3;
BA_ "GenSigSendType" SG_ 1173 User_p_download 3;
BA_ "GenSigRoutingTimeoutValue_String" SG_ 1173 PSEAT_vent_req "0x0";
BA_ "GenSigSendType" SG_ 1173 PSEAT_vent_req 3;
BA_ "GenSigSendType" SG_ 1173 FFogLampSW 3;
BA_ "GenSigRoutingTimeoutValue_String" SG_ 1173 DSEAT_vent_req "0x0";
BA_ "GenSigSendType" SG_ 1173 DSEAT_vent_req 3;
BA_ "GenSigSendType" SG_ 1173 RFogLampSW 3;
BA_ "GenSigInvalidValue" SG_ 1173 IVI_PTG_Mode_SW 2;
BA_ "GenSigRoutingTimeoutValue_String" SG_ 1173 IVI_PTG_Mode_SW "0x2";
BA_ "GenSigRoutingTimeoutValue" SG_ 1173 IVI_PTG_Mode_SW 2;
BA_ "GenSigSendType" SG_ 1173 IVI_PTG_Mode_SW 3;
BA_ "GenSigInvalidValue" SG_ 1173 IVI_PTG_Sta_SW 2;
BA_ "GenSigRoutingTimeoutValue_String" SG_ 1173 IVI_PTG_Sta_SW "0x2";
BA_ "GenSigRoutingTimeoutValue" SG_ 1173 IVI_PTG_Sta_SW 2;
BA_ "GenSigSendType" SG_ 1173 IVI_PTG_Sta_SW 3;
BA_ "GenSigInvalidValue" SG_ 1173 SLG_Sw 2;
BA_ "GenSigRoutingTimeoutValue_String" SG_ 1173 SLG_Sw "0x2";
BA_ "GenSigRoutingTimeoutValue" SG_ 1173 SLG_Sw 2;
BA_ "GenSigSendType" SG_ 1173 SLG_Sw 3;
BA_ "GenSigInvalidValue" SG_ 1173 FS_Off_Sw 2;
BA_ "GenSigRoutingTimeoutValue_String" SG_ 1173 FS_Off_Sw "0x2";
BA_ "GenSigRoutingTimeoutValue" SG_ 1173 FS_Off_Sw 2;
BA_ "GenSigSendType" SG_ 1173 FS_Off_Sw 3;
BA_ "GenSigInvalidValue" SG_ 1173 CAAS_Sw 2;
BA_ "GenSigRoutingTimeoutValue_String" SG_ 1173 CAAS_Sw "0x2";
BA_ "GenSigRoutingTimeoutValue" SG_ 1173 CAAS_Sw 2;
BA_ "GenSigSendType" SG_ 1173 CAAS_Sw 3;
BA_ "GenSigRoutingTimeoutValue_String" SG_ 1173 DSEAT_entryfun_set "0x0";
BA_ "GenSigSendType" SG_ 1173 DSEAT_entryfun_set 3;
BA_ "GenSigRoutingTimeoutValue_String" SG_ 1173 DSEAT_anti_set "0x0";
BA_ "GenSigSendType" SG_ 1173 DSEAT_anti_set 3;
BA_ "GenSigRoutingTimeoutValue_String" SG_ 1173 IVI_TrailerCheckReq_Sta "0x0";
BA_ "GenSigSendType" SG_ 1173 IVI_TrailerCheckReq_Sta 3;
BA_ "GenSigSendType" SG_ 1173 TPMS_Res_Butt 3;
BA_ "GenSigSendType" SG_ 1173 FollowMeSW 3;
BA_ "GenSigSendType" SG_ 1173 SetUnlockSingle 3;
BA_ "GenSigSendType" SG_ 1173 IVI_Mute_Sta 3;
BA_ "GenSigSendType" SG_ 1173 IVI_PTG_USSta_SW 3;
BA_ "GenSigSendType" SG_ 1173 IVI_WI_MAIN_SW 3;
BA_ "GenSigSendType" SG_ 1173 IVI_RR_Def_Req 3;
BA_ "GenSigSendType" SG_ 1173 IVI_Night_Mode_Sta 3;
BA_ "GenSigSendType" SG_ 1173 IVI_Status 3;
BA_ "GenSigInvalidValue" SG_ 1173 LVDAMute_BUTT 2;
BA_ "GenSigRoutingTimeoutValue_String" SG_ 1173 LVDAMute_BUTT "0x2";
BA_ "GenSigRoutingTimeoutValue" SG_ 1173 LVDAMute_BUTT 2;
BA_ "GenSigSendType" SG_ 1173 LVDAMute_BUTT 3;
BA_ "GenSigInvalidValue" SG_ 1173 Hood_Latch_SW 2;
BA_ "GenSigRoutingTimeoutValue_String" SG_ 1173 Hood_Latch_SW "0x2";
BA_ "GenSigRoutingTimeoutValue" SG_ 1173 Hood_Latch_SW 2;
BA_ "GenSigSendType" SG_ 1173 Hood_Latch_SW 3;
BA_ "GenSigRoutingTimeoutValue_String" SG_ 1173 IVI_TrailerModeSW_Sta "0x0";
BA_ "GenSigSendType" SG_ 1173 IVI_TrailerModeSW_Sta 3;
BA_ "GenSigInvalidValue" SG_ 1173 RCTA_BUTT 2;
BA_ "GenSigRoutingTimeoutValue_String" SG_ 1173 RCTA_BUTT "0x2";
BA_ "GenSigRoutingTimeoutValue" SG_ 1173 RCTA_BUTT 2;
BA_ "GenSigSendType" SG_ 1173 RCTA_BUTT 3;
BA_ "GenSigSendType" SG_ 1173 IVI_Pwroff_req 3;
BA_ "GenSigSendType" SG_ 1173 IVI_Trigger_req 3;
BA_ "GenSigSendType" SG_ 1173 AVM_Err_STA 3;
BA_ "GenSigRoutingTimeoutValue_String" SG_ 1173 SenstivityPosition "0x0";
BA_ "GenSigSendType" SG_ 1173 SenstivityPosition 3;
BA_ "GenSigSendType" SG_ 1173 AVM_Parking_mode 3;
BA_ "GenSigSendType" SG_ 1173 NAVI_ForwardLinkLevel 3;
BA_ "GenSigSendType" SG_ 1173 NAVI_LinkClass 3;
BA_ "GenSigSendType" SG_ 1173 NAVI_RoadClass 3;
BA_ "GenSigSendType" SG_ 1173 RoomLampMode 3;
BA_ "GenSigRoutingTimeoutValue_String" SG_ 1173 AC_Chg_Cur_Set "0x0";
BA_ "GenSigSendType" SG_ 1173 AC_Chg_Cur_Set 3;
BA_ "GenSigSendType" SG_ 1173 IVI_SWC_ACCMode_Sta 3;
BA_ "GenSigInvalidValue" SG_ 1173 SOC_Limit_Set 31;
BA_ "GenSigStartValue" SG_ 1173 SOC_Limit_Set 25;
BA_ "GenSigRoutingTimeoutValue_String" SG_ 1173 SOC_Limit_Set "0x1F";
BA_ "GenSigRoutingTimeoutValue" SG_ 1173 SOC_Limit_Set 31;
BA_ "GenSigSendType" SG_ 1173 CDL_Lock_Butt 3;
BA_ "GenSigSendType" SG_ 1173 CDL_Unlock_Butt 3;
BA_ "GenSigRoutingTimeoutValue_String" SG_ 1173 SOC_ADJ_BUTT "0x0";
BA_ "GenSigSendType" SG_ 1173 SOC_ADJ_BUTT 3;
BA_ "GenSigInvalidValue" SG_ 1173 Roll_Mode_SW_Cmd 3;
BA_ "GenSigRoutingTimeoutValue_String" SG_ 1173 Roll_Mode_SW_Cmd "0x3";
BA_ "GenSigRoutingTimeoutValue" SG_ 1173 Roll_Mode_SW_Cmd 3;
BA_ "GenSigSendType" SG_ 1173 Roll_Mode_SW_Cmd 3;
BA_ "GenSigInvalidValue" SG_ 1173 TCS_SW_Cmd 3;
BA_ "GenSigRoutingTimeoutValue_String" SG_ 1173 TCS_SW_Cmd "0x3";
BA_ "GenSigRoutingTimeoutValue" SG_ 1173 TCS_SW_Cmd 3;
BA_ "GenSigSendType" SG_ 1173 TCS_SW_Cmd 3;
BA_ "GenSigInvalidValue" SG_ 1173 SLIF_BUTT 2;
BA_ "GenSigRoutingTimeoutValue_String" SG_ 1173 SLIF_BUTT "0x2";
BA_ "GenSigRoutingTimeoutValue" SG_ 1173 SLIF_BUTT 2;
BA_ "GenSigSendType" SG_ 1173 SLIF_BUTT 3;
BA_ "GenSigSendType" SG_ 1173 Roll_Eng_Mode 3;
BA_ "GenSigInvalidValue" SG_ 1173 IVI_LVChrgFuncSW 2;
BA_ "GenSigRoutingTimeoutValue_String" SG_ 1173 IVI_LVChrgFuncSW "0x2";
BA_ "GenSigRoutingTimeoutValue" SG_ 1173 IVI_LVChrgFuncSW 2;
BA_ "GenSigSendType" SG_ 1173 IVI_LVChrgFuncSW 3;
BA_ "GenSigInvalidValue" SG_ 1173 IVI_PwrLockSW 2;
BA_ "GenSigRoutingTimeoutValue_String" SG_ 1173 IVI_PwrLockSW "0x2";
BA_ "GenSigRoutingTimeoutValue" SG_ 1173 IVI_PwrLockSW 2;
BA_ "GenSigSendType" SG_ 1173 IVI_PwrLockSW 3;
BA_ "GenSigInvalidValue" SG_ 1173 IVI_CoastDwSW 2;
BA_ "GenSigRoutingTimeoutValue_String" SG_ 1173 IVI_CoastDwSW "0x2";
BA_ "GenSigRoutingTimeoutValue" SG_ 1173 IVI_CoastDwSW 2;
BA_ "GenSigSendType" SG_ 1173 IVI_CoastDwSW 3;
BA_ "GenSigInvalidValue" SG_ 1173 IVI_ActvDmpDisabSW 2;
BA_ "GenSigRoutingTimeoutValue_String" SG_ 1173 IVI_ActvDmpDisabSW "0x2";
BA_ "GenSigRoutingTimeoutValue" SG_ 1173 IVI_ActvDmpDisabSW 2;
BA_ "GenSigSendType" SG_ 1173 IVI_ActvDmpDisabSW 3;
BA_ "GenSigInvalidValue" SG_ 1173 AVM_parking_cancel 2;
BA_ "GenSigRoutingTimeoutValue_String" SG_ 1173 AVM_parking_cancel "0x2";
BA_ "GenSigRoutingTimeoutValue" SG_ 1173 AVM_parking_cancel 2;
BA_ "GenSigSendType" SG_ 1173 AVM_parking_cancel 3;
BA_ "GenSigInvalidValue" SG_ 1173 AVM_parking_excute 2;
BA_ "GenSigRoutingTimeoutValue_String" SG_ 1173 AVM_parking_excute "0x2";
BA_ "GenSigRoutingTimeoutValue" SG_ 1173 AVM_parking_excute 2;
BA_ "GenSigSendType" SG_ 1173 AVM_parking_excute 3;
BA_ "GenSigSendType" SG_ 1173 AVM_OFF_Rec_Butt 3;
BA_ "GenSigRoutingTimeoutValue_String" SG_ 1173 Approach_Unlock_SW "0x0";
BA_ "GenSigSendType" SG_ 1173 Approach_Unlock_SW 3;
BA_ "GenSigInvalidValue" SG_ 1173 IVI_ISA_OffsetSpd 15;
BA_ "GenSigStartValue" SG_ 1173 IVI_ISA_OffsetSpd 15;
BA_ "GenSigRoutingTimeoutValue_String" SG_ 1173 IVI_ISA_OffsetSpd "0xF";
BA_ "GenSigInactiveValue" SG_ 1173 IVI_ISA_OffsetSpd 15;
BA_ "GenSigRoutingTimeoutValue" SG_ 1173 IVI_ISA_OffsetSpd 15;
BA_ "GenSigSendType" SG_ 1173 IVI_ISA_OffsetSpd 3;
BA_ "GenSigInvalidValue" SG_ 1173 IVI_PTG_Open_Height 7;
BA_ "GenSigStartValue" SG_ 1173 IVI_PTG_Open_Height 5;
BA_ "GenSigRoutingTimeoutValue_String" SG_ 1173 IVI_PTG_Open_Height "0x7";
BA_ "GenSigInactiveValue" SG_ 1173 IVI_PTG_Open_Height 5;
BA_ "GenSigRoutingTimeoutValue" SG_ 1173 IVI_PTG_Open_Height 7;
BA_ "GenSigSendType" SG_ 1173 IVI_PTG_Open_Height 3;
BA_ "GenSigRoutingTimeoutValue_String" SG_ 1173 IVI_ChargePortSW_Sta "0x0";
BA_ "GenSigSendType" SG_ 1173 IVI_ChargePortSW_Sta 3;
BA_ "GenSigInvalidValue" SG_ 1173 IVI_SLIF_Warning_Sta 3;
BA_ "GenSigStartValue" SG_ 1173 IVI_SLIF_Warning_Sta 3;
BA_ "GenSigRoutingTimeoutValue_String" SG_ 1173 IVI_SLIF_Warning_Sta "0x3";
BA_ "GenSigInactiveValue" SG_ 1173 IVI_SLIF_Warning_Sta 3;
BA_ "GenSigRoutingTimeoutValue" SG_ 1173 IVI_SLIF_Warning_Sta 3;
BA_ "GenSigSendType" SG_ 1173 IVI_SLIF_Warning_Sta 3;
BA_ "GenSigSendType" SG_ 1173 IVI_ACC_Adaptive_Sta 3;
BA_ "GenSigInvalidValue" SG_ 1173 IVI_PSEAT_Slide_Cmd 3;
BA_ "GenSigRoutingTimeoutValue_String" SG_ 1173 IVI_PSEAT_Slide_Cmd "0x3";
BA_ "GenSigRoutingTimeoutValue" SG_ 1173 IVI_PSEAT_Slide_Cmd 3;
BA_ "GenSigSendType" SG_ 1173 IVI_PSEAT_Slide_Cmd 3;
BA_ "GenSigInvalidValue" SG_ 1173 IVI_DSEAT_FroEdge_Height_Cmd 3;
BA_ "GenSigRoutingTimeoutValue_String" SG_ 1173 IVI_DSEAT_FroEdge_Height_Cmd "0x3";
BA_ "GenSigRoutingTimeoutValue" SG_ 1173 IVI_DSEAT_FroEdge_Height_Cmd 3;
BA_ "GenSigSendType" SG_ 1173 IVI_DSEAT_FroEdge_Height_Cmd 3;
BA_ "GenSigInvalidValue" SG_ 1173 IVI_DSEAT_Height_Cmd 3;
BA_ "GenSigRoutingTimeoutValue_String" SG_ 1173 IVI_DSEAT_Height_Cmd "0x3";
BA_ "GenSigRoutingTimeoutValue" SG_ 1173 IVI_DSEAT_Height_Cmd 3;
BA_ "GenSigSendType" SG_ 1173 IVI_DSEAT_Height_Cmd 3;
BA_ "GenSigInvalidValue" SG_ 1173 IVI_DSEAT_Recline_Cmd 3;
BA_ "GenSigRoutingTimeoutValue_String" SG_ 1173 IVI_DSEAT_Recline_Cmd "0x3";
BA_ "GenSigRoutingTimeoutValue" SG_ 1173 IVI_DSEAT_Recline_Cmd 3;
BA_ "GenSigSendType" SG_ 1173 IVI_DSEAT_Recline_Cmd 3;
BA_ "GenSigInvalidValue" SG_ 1173 IVI_PSEAT_Recline_Cmd 3;
BA_ "GenSigRoutingTimeoutValue_String" SG_ 1173 IVI_PSEAT_Recline_Cmd "0x3";
BA_ "GenSigRoutingTimeoutValue" SG_ 1173 IVI_PSEAT_Recline_Cmd 3;
BA_ "GenSigSendType" SG_ 1173 IVI_PSEAT_Recline_Cmd 3;
BA_ "GenSigRoutingTimeoutValue_String" SG_ 1173 IVI_DSEAT_Memory_OPTCLS_Sta "0x0";
BA_ "GenSigSendType" SG_ 1173 IVI_DSEAT_Memory_OPTCLS_Sta 3;
BA_ "GenSigInvalidValue" SG_ 1173 IVI_SetTempZon2_Sta 31;
BA_ "GenSigStartValue" SG_ 1173 IVI_SetTempZon2_Sta 31;
BA_ "GenSigRoutingTimeoutValue_String" SG_ 1173 IVI_SetTempZon2_Sta "0x1F";
BA_ "GenSigInactiveValue" SG_ 1173 IVI_SetTempZon2_Sta 31;
BA_ "GenSigRoutingTimeoutValue" SG_ 1173 IVI_SetTempZon2_Sta 31;
BA_ "GenSigSendType" SG_ 1173 IVI_SetTempZon2_Sta 3;
BA_ "GenSigRoutingTimeoutValue_String" SG_ 1173 IVI_AirIntZ3_Cmd "0x2";
BA_ "GenSigRoutingTimeoutValue" SG_ 1173 IVI_AirIntZ3_Cmd 2;
BA_ "GenSigSendType" SG_ 1173 IVI_AirIntZ3_Cmd 3;
BA_ "GenSigInvalidValue" SG_ 1173 IVI_SetTempZon1_Sta 31;
BA_ "GenSigStartValue" SG_ 1173 IVI_SetTempZon1_Sta 31;
BA_ "GenSigRoutingTimeoutValue_String" SG_ 1173 IVI_SetTempZon1_Sta "0x1F";
BA_ "GenSigInactiveValue" SG_ 1173 IVI_SetTempZon1_Sta 31;
BA_ "GenSigRoutingTimeoutValue" SG_ 1173 IVI_SetTempZon1_Sta 31;
BA_ "GenSigSendType" SG_ 1173 IVI_SetTempZon1_Sta 3;
BA_ "GenSigInvalidValue" SG_ 1173 IVI_DSEAT_Slide_Cmd 3;
BA_ "GenSigRoutingTimeoutValue_String" SG_ 1173 IVI_DSEAT_Slide_Cmd "0x3";
BA_ "GenSigRoutingTimeoutValue" SG_ 1173 IVI_DSEAT_Slide_Cmd 3;
BA_ "GenSigSendType" SG_ 1173 IVI_DSEAT_Slide_Cmd 3;
BA_ "GenSigRoutingTimeoutValue_String" SG_ 1173 IVI_DSEAT_Memory1_Sta "0x0";
BA_ "GenSigSendType" SG_ 1173 IVI_DSEAT_Memory1_Sta 3;
BA_ "GenSigRoutingTimeoutValue_String" SG_ 1173 IVI_DSEAT_Memory2_Sta "0x0";
BA_ "GenSigSendType" SG_ 1173 IVI_DSEAT_Memory2_Sta 3;
BA_ "GenSigRoutingTimeoutValue_String" SG_ 1173 DMS_Warning_Fatigue "0x0";
BA_ "GenSigRoutingTimeoutValue_String" SG_ 1173 DMS_Warning_Unresponsive "0x0";
BA_ "GenSigSendType" SG_ 1312 NM_IVI_Node_ID 7;
BA_ "GenSigSendType" SG_ 1312 NM_IVI_Rpt_Msg_Req 7;
BA_ "GenSigSendType" SG_ 1312 NM_IVI_CSB 7;
BA_ "GenSigSendType" SG_ 1312 NM_IVI_Active_WU 7;
BA_ "GenSigSendType" SG_ 1312 NM_IVI_PNI 7;
BA_ "GenSigSendType" SG_ 1312 NM_IVI_ERROR_State 7;
BA_ "GenSigSendType" SG_ 1568 DiagRespFromIVI 3;
BA_ "GenSigRoutingTimeoutValue_String" SG_ 2362634068 CP2VAutoTracH "0x2";
BA_ "GenSigRoutingTimeoutValue" SG_ 2362634068 CP2VAutoTracH 2;
BA_ "GenSigRoutingTimeoutValue_String" SG_ 2362634068 CP2VKneeReqLSide "0x2";
BA_ "GenSigRoutingTimeoutValue" SG_ 2362634068 CP2VKneeReqLSide 2;
BA_ "GenSigRoutingTimeoutValue_String" SG_ 2362634068 CP2VKneeReqRSide "0x2";
BA_ "GenSigRoutingTimeoutValue" SG_ 2362634068 CP2VKneeReqRSide 2;
BA_ "GenSigRoutingTimeoutValue_String" SG_ 2362634068 CP2VKneeCtrlMReq "0x2";
BA_ "GenSigRoutingTimeoutValue" SG_ 2362634068 CP2VKneeCtrlMReq 2;
BA_ "GenSigRoutingTimeoutValue_String" SG_ 2362634068 CP2VNLvReqFA "0x9";
BA_ "GenSigRoutingTimeoutValue" SG_ 2362634068 CP2VNLvReqFA 9;
BA_ "GenSigRoutingTimeoutValue_String" SG_ 2362634068 CP2VNLvReqRA "0x9";
BA_ "GenSigRoutingTimeoutValue" SG_ 2362634068 CP2VNLvReqRA 9;
BA_ "GenSigRoutingTimeoutValue_String" SG_ 2362634068 CP2VLvCtrlModeReq "0x9";
BA_ "GenSigRoutingTimeoutValue" SG_ 2362634068 CP2VLvCtrlModeReq 9;
BA_ "GenSigRoutingTimeoutValue_String" SG_ 2362634068 CP2VLA1PosCmd "0x2";
BA_ "GenSigRoutingTimeoutValue" SG_ 2362634068 CP2VLA1PosCmd 2;
BA_ "GenSigRoutingTimeoutValue_String" SG_ 2362634068 CP2VLA2PosCmd "0x2";
BA_ "GenSigRoutingTimeoutValue" SG_ 2362634068 CP2VLA2PosCmd 2;
BA_ "GenSigRoutingTimeoutValue_String" SG_ 2362634068 CP2VKneeReqFA "0x2";
BA_ "GenSigRoutingTimeoutValue" SG_ 2362634068 CP2VKneeReqFA 2;
BA_ "GenSigRoutingTimeoutValue_String" SG_ 2362634068 CP2VKneeReqRA "0x2";
BA_ "GenSigRoutingTimeoutValue" SG_ 2362634068 CP2VKneeReqRA 2;
BA_ "GenSigRoutingTimeoutValue_String" SG_ 2147484162 FDC_VCU_TUpASta_Sta "0x2";
BA_ "GenSigRoutingTimeoutValue" SG_ 2147484162 FDC_VCU_TUpASta_Sta 2;
BA_ "GenSigSendType" SG_ 2147484162 FDC_BCM_TgateSWL_Sta 3;
BA_ "GenSigSendType" SG_ 2147484162 FDC_BCM_TgateSWR_Sta 3;
BA_ "GenSigInvalidValue" SG_ 2566000691 T1_TPMS_RBOPressIndi 3;
BA_ "GenSigRoutingTimeoutValue_String" SG_ 2566000691 T1_TPMS_RBOPressIndi "0x3";
BA_ "GenSigRoutingTimeoutValue" SG_ 2566000691 T1_TPMS_RBOPressIndi 3;
BA_ "GenSigInvalidValue" SG_ 2566000691 T1_TPMS_LBOPressIndi 3;
BA_ "GenSigRoutingTimeoutValue_String" SG_ 2566000691 T1_TPMS_LBOPressIndi "0x3";
BA_ "GenSigRoutingTimeoutValue" SG_ 2566000691 T1_TPMS_LBOPressIndi 3;
BA_ "GenSigInvalidValue" SG_ 2566000691 T1_TPMS_RBIPressIndi 3;
BA_ "GenSigRoutingTimeoutValue_String" SG_ 2566000691 T1_TPMS_RBIPressIndi "0x3";
BA_ "GenSigRoutingTimeoutValue" SG_ 2566000691 T1_TPMS_RBIPressIndi 3;
BA_ "GenSigInvalidValue" SG_ 2566000691 T1_TPMS_LBIPressIndi 3;
BA_ "GenSigRoutingTimeoutValue_String" SG_ 2566000691 T1_TPMS_LBIPressIndi "0x3";
BA_ "GenSigRoutingTimeoutValue" SG_ 2566000691 T1_TPMS_LBIPressIndi 3;
BA_ "GenSigRoutingTimeoutValue_String" SG_ 2566000691 T1_TPMS_RBOWheelTmpIndi "0x1";
BA_ "GenSigRoutingTimeoutValue" SG_ 2566000691 T1_TPMS_RBOWheelTmpIndi 1;
BA_ "GenSigRoutingTimeoutValue_String" SG_ 2566000691 T1_TPMS_LBOWheelTmpIndi "0x1";
BA_ "GenSigRoutingTimeoutValue" SG_ 2566000691 T1_TPMS_LBOWheelTmpIndi 1;
BA_ "GenSigRoutingTimeoutValue_String" SG_ 2566000691 T1_TPMS_RBIWheelTmpIndi "0x1";
BA_ "GenSigRoutingTimeoutValue" SG_ 2566000691 T1_TPMS_RBIWheelTmpIndi 1;
BA_ "GenSigRoutingTimeoutValue_String" SG_ 2566000691 T1_TPMS_LBIWheelTmpIndi "0x1";
BA_ "GenSigRoutingTimeoutValue" SG_ 2566000691 T1_TPMS_LBIWheelTmpIndi 1;
BA_ "GenSigRoutingTimeoutValue_String" SG_ 2566000691 T1_TPMS_RBOSensorFail "0x1";
BA_ "GenSigRoutingTimeoutValue" SG_ 2566000691 T1_TPMS_RBOSensorFail 1;
BA_ "GenSigInvalidValue" SG_ 2566000691 T1_TPMS_LBOSensorFail 1;
BA_ "GenSigRoutingTimeoutValue_String" SG_ 2566000691 T1_TPMS_LBOSensorFail "0x1";
BA_ "GenSigRoutingTimeoutValue" SG_ 2566000691 T1_TPMS_LBOSensorFail 1;
BA_ "GenSigRoutingTimeoutValue_String" SG_ 2566000691 T1_TPMS_RBISensorFail "0x1";
BA_ "GenSigRoutingTimeoutValue" SG_ 2566000691 T1_TPMS_RBISensorFail 1;
BA_ "GenSigInvalidValue" SG_ 2566000691 T1_TPMS_LBISensorFail 1;
BA_ "GenSigRoutingTimeoutValue_String" SG_ 2566000691 T1_TPMS_LBISensorFail "0x1";
BA_ "GenSigRoutingTimeoutValue" SG_ 2566000691 T1_TPMS_LBISensorFail 1;
BA_ "GenSigInvalidValue" SG_ 2566000691 T1_TPMS_RFPressIndi 3;
BA_ "GenSigRoutingTimeoutValue_String" SG_ 2566000691 T1_TPMS_RFPressIndi "0x3";
BA_ "GenSigRoutingTimeoutValue" SG_ 2566000691 T1_TPMS_RFPressIndi 3;
BA_ "GenSigInvalidValue" SG_ 2566000691 T1_TPMS_TPMSWarnIndi 3;
BA_ "GenSigRoutingTimeoutValue_String" SG_ 2566000691 T1_TPMS_TPMSWarnIndi "0x3";
BA_ "GenSigRoutingTimeoutValue" SG_ 2566000691 T1_TPMS_TPMSWarnIndi 3;
BA_ "GenSigInvalidValue" SG_ 2566000691 T1_TPMS_LFPressIndi 3;
BA_ "GenSigRoutingTimeoutValue_String" SG_ 2566000691 T1_TPMS_LFPressIndi "0x3";
BA_ "GenSigRoutingTimeoutValue" SG_ 2566000691 T1_TPMS_LFPressIndi 3;
BA_ "GenSigRoutingTimeoutValue_String" SG_ 2566000691 T1_TPMS_LFSensorFail "0x1";
BA_ "GenSigRoutingTimeoutValue" SG_ 2566000691 T1_TPMS_LFSensorFail 1;
BA_ "GenSigRoutingTimeoutValue_String" SG_ 2566000691 T1_TPMS_LFWheelTmpIndi "0x1";
BA_ "GenSigRoutingTimeoutValue" SG_ 2566000691 T1_TPMS_LFWheelTmpIndi 1;
BA_ "GenSigRoutingTimeoutValue_String" SG_ 2566000691 T1_TPMS_RFSensorFail "0x1";
BA_ "GenSigRoutingTimeoutValue" SG_ 2566000691 T1_TPMS_RFSensorFail 1;
BA_ "GenSigInvalidValue" SG_ 2566000947 T1_TPMS_RBOWheelPress 255;
BA_ "GenSigInvalidValue" SG_ 2566000947 T1_TPMS_RBIWheelPress 255;
BA_ "GenSigInvalidValue" SG_ 2566000947 T1_TPMS_LBOWheelPress 255;
BA_ "GenSigInvalidValue" SG_ 2566000947 T1_TPMS_LBIWheelPress 255;
BA_ "GenSigInvalidValue" SG_ 2566000947 T1_TPMS_LFWheelPress 255;
BA_ "GenSigRoutingTimeoutValue_String" SG_ 2566000947 T1_TPMS_LFWheelPress "0xFF";
BA_ "GenSigRoutingTimeoutValue" SG_ 2566000947 T1_TPMS_LFWheelPress 255;
BA_ "GenSigInvalidValue" SG_ 2566000947 T1_TPMS_RFWheelPress 255;
BA_ "GenSigRoutingTimeoutValue_String" SG_ 2566000947 T1_TPMS_RFWheelPress "0xFF";
BA_ "GenSigRoutingTimeoutValue" SG_ 2566000947 T1_TPMS_RFWheelPress 255;
BA_ "GenSigInvalidValue" SG_ 2566001203 T1_TPMS_LFWheelTemp 255;
BA_ "GenSigRoutingTimeoutValue_String" SG_ 2566001203 T1_TPMS_LFWheelTemp "0xFF";
BA_ "GenSigInactiveValue" SG_ 2566001203 T1_TPMS_LFWheelTemp 255;
BA_ "GenSigRoutingTimeoutValue" SG_ 2566001203 T1_TPMS_LFWheelTemp 255;
BA_ "GenSigInvalidValue" SG_ 2566001203 T1_TPMS_RFWheelTemp 255;
BA_ "GenSigRoutingTimeoutValue_String" SG_ 2566001203 T1_TPMS_RFWheelTemp "0xFF";
BA_ "GenSigInactiveValue" SG_ 2566001203 T1_TPMS_RFWheelTemp 255;
BA_ "GenSigRoutingTimeoutValue" SG_ 2566001203 T1_TPMS_RFWheelTemp 255;
BA_ "GenSigInvalidValue" SG_ 2566844752 EPB_ParkingBrake_Sta 3;
BA_ "GenSigRoutingTimeoutValue_String" SG_ 2566844752 EPB_ParkingBrake_Sta "0x2";
BA_ "GenSigRoutingTimeoutValue" SG_ 2566844752 EPB_ParkingBrake_Sta 2;
BA_ "GenSigInvalidValue" SG_ 2566896720 EPB_ParkBrakeStateLamp_sta 3;
BA_ "GenSigRoutingTimeoutValue_String" SG_ 2566896720 EPB_ParkBrakeStateLamp_sta "0x3";
BA_ "GenSigRoutingTimeoutValue" SG_ 2566896720 EPB_ParkBrakeStateLamp_sta 3;
BA_ "GenSigInvalidValue" SG_ 2566896720 EPB_BrakePedalActuationInd_cmd 3;
BA_ "GenSigRoutingTimeoutValue_String" SG_ 2566896720 EPB_BrakePedalActuationInd_cmd "0x2";
BA_ "GenSigRoutingTimeoutValue" SG_ 2566896720 EPB_BrakePedalActuationInd_cmd 2;
BA_ "GenSigInvalidValue" SG_ 2566896720 EPB_ParkBrake_Sta 15;
BA_ "GenSigRoutingTimeoutValue_String" SG_ 2566896720 EPB_ParkBrake_Sta "0xE";
BA_ "GenSigRoutingTimeoutValue" SG_ 2566896720 EPB_ParkBrake_Sta 14;
BA_ "GenSigInvalidValue" SG_ 2566896720 EPB_SpringBrakeABSActive_sta 3;
BA_ "GenSigRoutingTimeoutValue_String" SG_ 2566896720 EPB_SpringBrakeABSActive_sta "0x3";
BA_ "GenSigRoutingTimeoutValue" SG_ 2566896720 EPB_SpringBrakeABSActive_sta 3;
BA_ "GenSigInvalidValue" SG_ 2566896720 EPB_SpringBrakePressure_Sta 251;
BA_ "GenSigRoutingTimeoutValue_String" SG_ 2566896720 EPB_SpringBrakePressure_Sta "0xFB";
BA_ "GenSigRoutingTimeoutValue" SG_ 2566896720 EPB_SpringBrakePressure_Sta 251;
BA_ "GenSigInvalidValue" SG_ 2566896720 EPB_ParkBrakeApply_Sta 7;
BA_ "GenSigRoutingTimeoutValue_String" SG_ 2566896720 EPB_ParkBrakeApply_Sta "0x7";
BA_ "GenSigRoutingTimeoutValue" SG_ 2566896720 EPB_ParkBrakeApply_Sta 7;
BA_ "GenSigInvalidValue" SG_ 2566896720 EPB_ParkBrakeRelease_Sta 7;
BA_ "GenSigRoutingTimeoutValue_String" SG_ 2566896720 EPB_ParkBrakeRelease_Sta "0x7";
BA_ "GenSigRoutingTimeoutValue" SG_ 2566896720 EPB_ParkBrakeRelease_Sta 7;
BA_ "GenSigInvalidValue" SG_ 2566896720 EPB_ParkBrkReleaseInhibitInd_Cmd 3;
BA_ "GenSigRoutingTimeoutValue_String" SG_ 2566896720 EPB_ParkBrkReleaseInhibitInd_Cmd "0x3";
BA_ "GenSigRoutingTimeoutValue" SG_ 2566896720 EPB_ParkBrkReleaseInhibitInd_Cmd 3;
BA_ "GenSigInvalidValue" SG_ 2566896720 EPB_ExtParkBrakeSystem_Sta 7;
BA_ "GenSigRoutingTimeoutValue_String" SG_ 2566896720 EPB_ExtParkBrakeSystem_Sta "0x6";
BA_ "GenSigRoutingTimeoutValue" SG_ 2566896720 EPB_ExtParkBrakeSystem_Sta 6;
BA_ "GenSigInvalidValue" SG_ 2566896720 EPB_HcuSwitch_Sta 7;
BA_ "GenSigRoutingTimeoutValue_String" SG_ 2566896720 EPB_HcuSwitch_Sta "0x6";
BA_ "GenSigRoutingTimeoutValue" SG_ 2566896720 EPB_HcuSwitch_Sta 6;
BA_ "GenSigInvalidValue" SG_ 2566896720 EPB_ParkBrkLowAirIndication_Cmd 7;
BA_ "GenSigRoutingTimeoutValue_String" SG_ 2566896720 EPB_ParkBrkLowAirIndication_Cmd "0x7";
BA_ "GenSigRoutingTimeoutValue" SG_ 2566896720 EPB_ParkBrkLowAirIndication_Cmd 7;
BA_ "GenSigSendType" SG_ 515 Z24_BCM_FLTurnLampC_Sta 3;
BA_ "GenSigSendType" SG_ 515 Z24_BCM_FRTurnLampC_Sta 3;
BA_ "GenSigSendType" SG_ 515 Z24_BCM_RLTurnLampC_Sta 3;
BA_ "GenSigSendType" SG_ 515 Z24_BCM_RRTurnLampC_Sta 3;
BA_ "GenSigSendType" SG_ 515 Z24_BCM_FWiperProtection_Sta 3;
BA_ "GenSigSendType" SG_ 515 Z24_BCM_FWiperAS_Sta 3;
BA_ "GenSigSendType" SG_ 515 Z24_BCM_EmExitOP_Sta 3;
BA_ "GenSigSendType" SG_ 515 Z24_BCM_innerBuzzer_Sta 3;
BA_ "GenSigSendType" SG_ 515 Z24_BCM_SeatBeltSW_Sta 3;
BA_ "GenSigInvalidValue" SG_ 2566827568 Z24_CHA_AirPressurePC3_Sta 176;
BA_ "GenSigRoutingTimeoutValue_String" SG_ 2566827568 Z24_CHA_AirPressurePC3_Sta "0xB0";
BA_ "GenSigRoutingTimeoutValue" SG_ 2566827568 Z24_CHA_AirPressurePC3_Sta 176;
BA_ "GenSigInvalidValue" SG_ 2566827568 Z24_CHA_AirPressureRC1_Sta 176;
BA_ "GenSigRoutingTimeoutValue_String" SG_ 2566827568 Z24_CHA_AirPressureRC1_Sta "0xB0";
BA_ "GenSigRoutingTimeoutValue" SG_ 2566827568 Z24_CHA_AirPressureRC1_Sta 176;
BA_ "GenSigInvalidValue" SG_ 2566827568 Z24_CHA_AirPressureFC2_Sta 176;
BA_ "GenSigRoutingTimeoutValue_String" SG_ 2566827568 Z24_CHA_AirPressureFC2_Sta "0xB0";
BA_ "GenSigRoutingTimeoutValue" SG_ 2566827568 Z24_CHA_AirPressureFC2_Sta 176;
BA_ "GenSigRoutingTimeoutValue_String" SG_ 2565865967 FDC_CHA_CACTempWarn_Sta "0x1";
BA_ "GenSigRoutingTimeoutValue" SG_ 2565865967 FDC_CHA_CACTempWarn_Sta 1;
BA_ "GenSigRoutingTimeoutValue_String" SG_ 2565865967 FDC_CHA_CACPresWarn_Sta "0x1";
BA_ "GenSigRoutingTimeoutValue" SG_ 2565865967 FDC_CHA_CACPresWarn_Sta 1;
BA_ "GenSigRoutingTimeoutValue_String" SG_ 2566834735 ECASPLampSta "0x2";
BA_ "GenSigRoutingTimeoutValue" SG_ 2566834735 ECASPLampSta 2;
BA_ "GenSigSendType" SG_ 2566834735 ECASPLampSta 2;
BA_ "GenSigRoutingTimeoutValue_String" SG_ 2566834735 ECASAWarmLampSta "0x2";
BA_ "GenSigRoutingTimeoutValue" SG_ 2566834735 ECASAWarmLampSta 2;
BA_ "GenSigSendType" SG_ 2566834735 ECASAWarmLampSta 2;
BA_ "GenSigRoutingTimeoutValue_String" SG_ 2566834735 ECASRStopLampSta "0x2";
BA_ "GenSigRoutingTimeoutValue" SG_ 2566834735 ECASRStopLampSta 2;
BA_ "GenSigSendType" SG_ 2566834735 ECASRStopLampSta 2;
BA_ "GenSigRoutingTimeoutValue_String" SG_ 2566834735 ECASMFLampSta "0x2";
BA_ "GenSigRoutingTimeoutValue" SG_ 2566834735 ECASMFLampSta 2;
BA_ "GenSigSendType" SG_ 2566834735 ECASMFLampSta 2;
BA_ "GenSigSendType" SG_ 2566834735 ECASFEngPtcLamp 2;
BA_ "GenSigSendType" SG_ 2566834735 ECASAWL 2;
BA_ "GenSigSendType" SG_ 2566834735 ECASRSL 2;
BA_ "GenSigSendType" SG_ 2566834735 ECASMIL 2;
BA_ "GenSigSendType" SG_ 2566834735 ECASSPN_1 2;
BA_ "GenSigSendType" SG_ 2566834735 ECASSPN_2 2;
BA_ "GenSigSendType" SG_ 2566834735 ECASSPN_3 2;
BA_ "GenSigSendType" SG_ 2566834735 ECASFMI 2;
BA_ "GenSigSendType" SG_ 2566834735 ECASSPNCNV 2;
BA_ "GenSigSendType" SG_ 2566834735 ECASOcrCnt 2;
BA_ "GenSigInvalidValue" SG_ 2566887345 AC_Blower_lvl_sta 6;
BA_ "GenSigRoutingTimeoutValue_String" SG_ 2566887345 AC_Blower_lvl_sta "0x6";
BA_ "GenSigRoutingTimeoutValue" SG_ 2566887345 AC_Blower_lvl_sta 6;
BA_ "GenSigInvalidValue" SG_ 2566887345 AC_Set_temp_sta 25;
BA_ "GenSigRoutingTimeoutValue_String" SG_ 2566887345 AC_Set_temp_sta "0x19";
BA_ "GenSigRoutingTimeoutValue" SG_ 2566887345 AC_Set_temp_sta 25;
BA_ "GenSigInvalidValue" SG_ 2566831883 FASpeed 64256;
BA_ "GenSigInvalidValue" SG_ 2566831883 RelaSpdFALWheel 251;
BA_ "GenSigInvalidValue" SG_ 2566831883 RelaSpdFARWheel 251;
BA_ "GenSigInvalidValue" SG_ 2566831883 RelaSpdRA1LWheel 251;
BA_ "GenSigInvalidValue" SG_ 2566831883 RelaSpdRA1RWheel 251;
BA_ "GenSigInvalidValue" SG_ 2566831883 RelaSpdRA2LWheel 251;
BA_ "GenSigInvalidValue" SG_ 2566831883 RelaSpdRA2RWheel 251;
BA_ "GenSigSendType" SG_ 1175 IVI_DrBlower_Mode_Sta 3;
BA_ "GenSigRoutingTimeoutValue_String" SG_ 1175 IVI_LSEATvent_Cmd "0x0";
BA_ "GenSigSendType" SG_ 1175 IVI_LSEATvent_Cmd 3;
BA_ "GenSigRoutingTimeoutValue_String" SG_ 1175 IVI_MLFMost_Cmd "0x0";
BA_ "GenSigSendType" SG_ 1175 IVI_MLFMost_Cmd 3;
BA_ "GenSigRoutingTimeoutValue_String" SG_ 1175 IVI_MLFootLift_Cmd "0x0";
BA_ "GenSigSendType" SG_ 1175 IVI_MLFootLift_Cmd 3;
BA_ "GenSigRoutingTimeoutValue_String" SG_ 1175 IVI_MLNapMode_Cmd "0x0";
BA_ "GenSigSendType" SG_ 1175 IVI_MLNapMode_Cmd 3;
BA_ "GenSigRoutingTimeoutValue_String" SG_ 1175 IVI_MLRecliner_Cmd "0x0";
BA_ "GenSigSendType" SG_ 1175 IVI_MLRecliner_Cmd 3;
BA_ "GenSigRoutingTimeoutValue_String" SG_ 1175 IVI_MLRestore_Cmd "0x0";
BA_ "GenSigSendType" SG_ 1175 IVI_MLRestore_Cmd 3;
BA_ "GenSigRoutingTimeoutValue_String" SG_ 1175 IVI_MLSEATvent_Cmd "0x0";
BA_ "GenSigSendType" SG_ 1175 IVI_MLSEATvent_Cmd 3;
BA_ "GenSigRoutingTimeoutValue_String" SG_ 1175 IVI_MLSeatLift_Cmd "0x0";
BA_ "GenSigSendType" SG_ 1175 IVI_MLSeatLift_Cmd 3;
BA_ "GenSigRoutingTimeoutValue_String" SG_ 1175 IVI_MLSldRestore_Cmd "0x0";
BA_ "GenSigSendType" SG_ 1175 IVI_MLSldRestore_Cmd 3;
BA_ "GenSigRoutingTimeoutValue_String" SG_ 1175 IVI_MLSlider_Cmd "0x0";
BA_ "GenSigSendType" SG_ 1175 IVI_MLSlider_Cmd 3;
BA_ "GenSigRoutingTimeoutValue_String" SG_ 1175 IVI_MLZeroGravity_Cmd "0x0";
BA_ "GenSigSendType" SG_ 1175 IVI_MLZeroGravity_Cmd 3;
BA_ "GenSigRoutingTimeoutValue_String" SG_ 1175 IVI_MRFMost_Cmd "0x0";
BA_ "GenSigSendType" SG_ 1175 IVI_MRFMost_Cmd 3;
BA_ "GenSigRoutingTimeoutValue_String" SG_ 1175 IVI_MRFootLift_Cmd "0x0";
BA_ "GenSigSendType" SG_ 1175 IVI_MRFootLift_Cmd 3;
BA_ "GenSigRoutingTimeoutValue_String" SG_ 1175 IVI_MRNapMode_Cmd "0x0";
BA_ "GenSigSendType" SG_ 1175 IVI_MRNapMode_Cmd 3;
BA_ "GenSigRoutingTimeoutValue_String" SG_ 1175 IVI_MRRecliner_Cmd "0x0";
BA_ "GenSigSendType" SG_ 1175 IVI_MRRecliner_Cmd 3;
BA_ "GenSigRoutingTimeoutValue_String" SG_ 1175 IVI_MRRestore_Cmd "0x0";
BA_ "GenSigSendType" SG_ 1175 IVI_MRRestore_Cmd 3;
BA_ "GenSigRoutingTimeoutValue_String" SG_ 1175 IVI_MRSEATvent_Cmd "0x0";
BA_ "GenSigSendType" SG_ 1175 IVI_MRSEATvent_Cmd 3;
BA_ "GenSigRoutingTimeoutValue_String" SG_ 1175 IVI_MRSeatLift_Cmd "0x0";
BA_ "GenSigSendType" SG_ 1175 IVI_MRSeatLift_Cmd 3;
BA_ "GenSigRoutingTimeoutValue_String" SG_ 1175 IVI_MRSldRestore_Cmd "0x0";
BA_ "GenSigSendType" SG_ 1175 IVI_MRSldRestore_Cmd 3;
BA_ "GenSigRoutingTimeoutValue_String" SG_ 1175 IVI_MRSlider_Cmd "0x0";
BA_ "GenSigSendType" SG_ 1175 IVI_MRSlider_Cmd 3;
BA_ "GenSigRoutingTimeoutValue_String" SG_ 1175 IVI_MRZeroGravity_Cmd "0x0";
BA_ "GenSigSendType" SG_ 1175 IVI_MRZeroGravity_Cmd 3;
BA_ "GenSigSendType" SG_ 1175 IVI_PsBlower_Mode_Sta 3;
BA_ "GenSigRoutingTimeoutValue_String" SG_ 1175 IVI_RSEATvent_Cmd "0x0";
BA_ "GenSigSendType" SG_ 1175 IVI_RSEATvent_Cmd 3;
BA_ "GenSigRoutingTimeoutValue_String" SG_ 2566838066 Door_Fr_DoorEmergency_sta "0x1";
BA_ "GenSigRoutingTimeoutValue" SG_ 2566838066 Door_Fr_DoorEmergency_sta 1;
BA_ "GenSigSendType" SG_ 2566838066 Door_Fr_DoorEmergency_sta 3;
BA_ "GenSigRoutingTimeoutValue_String" SG_ 2566838066 Door_Fr_Doorposition_sta "0x1";
BA_ "GenSigRoutingTimeoutValue" SG_ 2566838066 Door_Fr_Doorposition_sta 1;
BA_ "GenSigSendType" SG_ 2566838066 Door_Fr_Doorposition_sta 3;
BA_ "GenSigRoutingTimeoutValue_String" SG_ 2566838066 Door_Fr_Dooroperation_sta "0x1";
BA_ "GenSigRoutingTimeoutValue" SG_ 2566838066 Door_Fr_Dooroperation_sta 1;
BA_ "GenSigSendType" SG_ 2566838066 Door_Fr_Dooroperation_sta 3;
VAL_ 2365479471 ASC1NomLvFAxis 7 "Lower Level" 6 "Upper Level" 5 "Customer Level" 4 "Preset Level" 3 "Normal Level 3" 2 "Normal Level 2" 1 "Normal Level 1" 0 "Level not specified";
VAL_ 2365479471 ASC1NomLvRAxis 7 "Lower Level" 6 "Upper Level" 5 "Customer Level" 4 "Preset Level" 3 "Normal Level 3" 2 "Normal Level 2" 1 "Normal Level 1" 0 "Level not specified";
VAL_ 2365479471 ASC1BlwNomLvFAxis 1 "below" 0 "not below";
VAL_ 2365479471 ASC1BlwNomLvRAxis 1 "below" 0 "not below";
VAL_ 2365479471 ASC1AbvNomLvFAxis 1 "above" 0 "not above";
VAL_ 2365479471 ASC1AbvNomLvRAxis 1 "above" 0 "not above";
VAL_ 2365479471 ASC1LowCtrlFAxis 2 "error state lifting not possible" 1 "lifting active" 0 "lifting not active";
VAL_ 2365479471 ASC1LowCtrlRAxis 2 "error state lifting not possible" 1 "lifting active" 0 "lifting not active";
VAL_ 2365479471 ASC1LiftCtrlFAxis 2 "error state lifting not possible" 1 "lifting active" 0 "lifting not active";
VAL_ 2365479471 ASC1LiftCtrlRAxis 2 "error state lifting not possible" 1 "lifting active" 0 "lifting not active";
VAL_ 2365479471 ASC1KneelingInfo 4 "Kneeling aborted" 3 "lifting active" 2 "Kneeling level reached" 1 "Lowering active" 0 "Not active";
VAL_ 2365479471 ASC1LvCtrlM 8 "Exhausting bellow function" 7 "Traction help (Load reduce)" 6 "Optimum Traction 2" 5 "Optimum Traction 1" 4 "Pressure ratio 2" 3 "Pressure ratio 1" 2 "Load fixing" 1 "Traction help (load transfer)" 0 "Normal operation";
VAL_ 2365479471 SADev 1 "Active" 0 "Not active";
VAL_ 2365479471 VehMotion 1 "Vehicle motion is inhibited" 0 "Vehicle may be moved";
VAL_ 2365479471 DoorRls 1 "Doors may be opened" 0 "Doors may not be opened";
VAL_ 2365479471 ASC1LiftAxle1P 1 "lift axle position up / tag axle unladen" 0 "lift axle position down / tag axle laden";
VAL_ 2365479471 FABumpR 1 "Actual level within bumper range" 0 "Actual level out of bumper range";
VAL_ 2365479471 RABumpR 1 "Actual level within bumper range" 0 "Actual level out of bumper range";
VAL_ 2365479471 LA2Pos 1 "lift axle position up / tag axle unladen" 0 "lift axle position down / tag axle laden";
VAL_ 2365479471 SuspenRmCtrl1 1 "Active" 0 "Not active";
VAL_ 2365479471 SuspenRmCtrl2 1 "Active" 0 "Not active";
VAL_ 2365479471 SuspCtrlrefuInfo 6 "General reject" 5 "Below speed limit" 4 "Above speed limit" 3 "Bogie differential not locked" 2 "Would exceed load limit (tag axle)" 1 "Axle load limit reached (load transfer)" 0 "Actual request not refused";
VAL_ 2550255781 EHPSErrLv 7 "Not available" 6 "Not available" 5 "Not available" 4 "Level4" 3 "Level3" 2 "Level2" 1 "Level1" 0 "No error";
VAL_ 2550255781 EHPSEnSta 3 "FAULT" 2 "RUN" 1 "Ready" 0 "INITIAL";
VAL_ 2550255781 EHPSHVILSig 1 "HV_interlock signal is Wrong" 0 "HV_interlock signal is OK";
VAL_ 2565865739 ASREngCtrlAtc 3 "Not available" 2 "Reserved" 1 "ASR engine control active" 0 "ASR engine control passive but installed";
VAL_ 2565865739 ASRBrakeCtrlAtc 3 "Not available" 2 "Reserved" 1 "ASR brake control active" 0 "ASR brake control passive but installed";
VAL_ 2565865739 AntiLBrakABSAct 3 "Not available" 2 "Reserved" 1 "ABS active" 0 "ABS passive but installed";
VAL_ 2565865739 EBSBrakeSw 3 "Not available" 2 "Error" 1 "Brake pedal is being pressed" 0 "Brake pedal is not being pressed";
VAL_ 2565865739 BrakePedalPos 251 "Invalid Value";
VAL_ 2565865739 ABSOffroadSw 3 "Not available" 2 "Error" 1 "ABS off-road switch active" 0 "ABS off-road switch passive";
VAL_ 2565865739 ASROffroadSw 3 "Not available" 2 "Error" 1 "ASR off-road switch active" 0 "ASR off-road switch passive";
VAL_ 2565865739 ASRHillHolderSw 3 "Not available" 2 "Error" 1 "ASR-hill holder switch active" 0 "ASR-hill holder switch passive";
VAL_ 2565865739 TractCtrlOvrSw 3 "Not available or not installed" 2 "Error" 1 "On" 0 "Off";
VAL_ 2565865739 AcltrInterlockSw 3 "Not available" 2 "Error" 1 "On" 0 "Off";
VAL_ 2565865739 EngDerateSw 3 "Not available" 2 "Error" 1 "On" 0 "Off";
VAL_ 2565865739 EngAuxShutdownSw 3 "Not available" 2 "Error" 1 "On" 0 "Off";
VAL_ 2565865739 RmAccelEnSw 3 "Not available" 2 "Error" 1 "On" 0 "Off";
VAL_ 2565865739 ABSFullyOper 3 "Not available" 2 "Reserved" 1 "Fully Operational" 0 "Not Fully Operational";
VAL_ 2565865739 EBSRedWarnLampSta 3 "Take no action" 2 "Reserved" 1 "On" 0 "Off";
VAL_ 2565865739 EBSAmWarnLampSta 3 "Take no action" 2 "Reserved" 1 "On" 0 "Off";
VAL_ 2565865739 ATCASRInfoSig 3 "Take no action" 2 "Reserved" 1 "On" 0 "Off";
VAL_ 2565865739 HaltBrakeSw 3 "Not available" 2 "Error" 1 "Halt brake switch active" 0 "Halt brake switch passive";
VAL_ 2565865739 TrailerABSSta 3 "Trailer ABS Status Information Not Available or Parameter Not Supported" 2 "Reserved" 1 "Trailer ABS Active" 0 "Trailer ABS Status Information Available But Not Active";
VAL_ 2565865739 TrailerABSWarnSig 3 "Take no action" 2 "Reserved" 1 "On " 0 "Off";
VAL_ 513 IVI_RrRoomlamp_Cmd 1 "Press" 0 "Release";
VAL_ 513 IVI_FrAtmoLamp_Cmd 1 "Auto" 0 "Off";
VAL_ 513 IVI_RrAtmoLamp_Cmd 1 "Auto" 0 "Off";
VAL_ 513 IVI_RrRmLampBright_Cmd 11 "Level11" 10 "Level10" 9 "Level9" 8 "Level8" 7 "Level7" 6 "Level6" 5 "Level5" 4 "Level4" 3 "Level3" 2 "Level2" 1 "Level1" 0 "No Request";
VAL_ 513 IVI_AmbiLgtSta 1 "Press" 0 "Release";
VAL_ 513 IVI_Passengerdoor_Sta 1 "Press" 0 "Release";
VAL_ 513 IVI_Frontindoorlight_Sta 1 "Press" 0 "Release";
VAL_ 513 IVI_FrRmLampBright_Cmd 11 "Level11" 10 "Level10" 9 "Level9" 8 "Level8" 7 "Level7" 6 "Level6" 5 "Level5" 4 "Level4" 3 "Level3" 2 "Level2" 1 "Level1" 0 "No Request";
VAL_ 602 METER_KPH_Calcu 255 "Invalid";
VAL_ 602 METER_MPH_Calcu 255 "Invalid";
VAL_ 602 ParkBrake 1 "On" 0 "Off";
VAL_ 602 Charge 1 "Disable (LED ON)" 0 "Enable (LED OFF)";
VAL_ 602 LEDlitWarnReq 1 "Warning request" 0 "No warning request";
VAL_ 602 Spd_Crl_Sta 1 "ON" 0 "OFF";
VAL_ 602 Spd_Crl_Mode 5 "invalid" 4 "ISA" 3 "LIM" 2 "CC" 1 "ACC" 0 "OFF";
VAL_ 1168 FCP_FrEvt_BtnSyncReq 1 "Press" 0 "Release";
VAL_ 1168 FCP_MidEvt_BtnAutoReq 1 "Press" 0 "Release";
VAL_ 1168 FCP_FrEvt_BtnAutoReq 1 "Press" 0 "Release";
VAL_ 1168 FCP_FrEvt_BtnACReq 1 "Press" 0 "Release";
VAL_ 1168 FCP_FrEvt_BtnACMaxReq 1 "Press" 0 "Release";
VAL_ 1168 VehACModReq 7 "Invalid" 6 "Signal not available" 5 "Reserved" 2 "Reserved" 1 "Economy mode" 0 "Standard";
VAL_ 1168 LINKtoDrive 1 "Press" 0 "Release";
VAL_ 1168 SmartEco_Mode_SW 1 "ON" 0 "OFF";
VAL_ 1168 OTA_CancelDL_Req 1 "Press" 0 "Release";
VAL_ 1168 IVI_OTA_Upd_Sta 3 "undefined" 2 "Completed" 1 "Uncompleted" 0 "No Update";
VAL_ 1168 OTA_UpdStart_Req 1 "Press" 0 "Release";
VAL_ 1168 OTA_SuspendDL_Req 1 "Press" 0 "Release";
VAL_ 1168 OTA_DL_Req 1 "Press" 0 "Release";
VAL_ 1168 AmbLigh_SafetyAlert_SW 1 "Press" 0 "Release";
VAL_ 1168 AmbLigh_LowBatAlert_SW 1 "Press" 0 "Release";
VAL_ 1168 AmbLight_WlcmLight_SW 1 "Press" 0 "Release";
VAL_ 1168 AmbLight_DimInDark_SW 1 "Press" 0 "Release";
VAL_ 1168 AmbLight_SW 1 "Press" 0 "Release";
VAL_ 1168 OpenDrOpenWdo_SW 1 "Press" 0 "Release";
VAL_ 1168 Upd_Countdown_Cancel 1 "Press" 0 "Release";
VAL_ 1168 Upd_Countdown_Skip 1 "Press" 0 "Release";
VAL_ 1168 AmbLightColorSet 65 "~0x7F undefined" 64 "No request" 63 "Red(255,0,0)" 62 "IndianRed(205,92,92)" 61 "LightCoral(240,128,128)" 60 "Tomato(255,99,71)" 59 "OrangeRed(255,69,0)" 58 "Coral(255,127,80)" 57 "LightSalmon(255,160,122)" 56 "DarkOrange(255,140,0)" 55 "Bisque(255,228,196)" 54 "NavajoWhite(255,222,173)" 53 "BlanchedAlmond(255,235,205)" 52 "Gold(255,215,0)" 51 "LemonChiffon(255,250,205)" 50 "Yellow(255,255,0)" 49 "LightYellow(255,255,224)" 48 "Ivory(255,255,240)" 47 "LightGoldenrodYellow(250,250,210)" 46 "Beige(245,245,220)" 45 "GreenYellow(73,255,47)" 44 "Chartreuse(127,255,0)" 43 "Lime(0,255,0)" 42 "LimeGreen(50,205,50)" 41 "PaleGreen(152,251,152)" 40 "LightGreen(144,238,144)" 39 "SeaGreen(46,139,87)" 38 "SpringGreen(60,179,113)" 37 "MediumSpringGreen(0,255,127)" 36 "MediumAquamarine(0,250,154)" 35 "Auqamarin(127,255,170)" 34 "MediumTurquoise(72,209,204)" 33 "DarkCyan(0,139,139)" 32 "DarkTurquoise(0,206,209)" 31 "Cyan(0,255,255)" 30 "PaleTurquoise(175,238,238)" 29 "DeepSkyBlue(0,191,255)" 28 "SkyBlue(135,206,235)" 27 "LightSkyBlue(135,206,250)" 26 "DoderBlue(30,144,255)" 25 "CornflowerBlue(100,149,237)" 24 "RoyalBlue(65,105,225)" 23 "Navy(0,0,128)" 22 "DarkBlue(0,0,139)" 21 "MidnightBlue(25,25,112)" 20 "MediumBlue(0,0,205)" 19 "Blue(0,0,255)" 18 "DarkSlateBlue(72,61,139)" 17 "SlateBlue(106,90,205)" 16 "MediumSlateBlue(123,104,238)" 15 "MediumPurple(147,112,219)" 14 "BlueViolet(138,43,226)" 13 "Indigo(75,0,130)" 12 "DarkOrchid(153,50,204)" 11 "DarkVoilet(148,0,211)" 10 "MediumOrchid(186,85,211)" 9 "DarkMagenta(139,0,139)" 8 "Magenta(255,0,255)" 7 "Violet(238,130,238)" 6 "Orchid(218,112,214)" 5 "MediumVioletRed(199,21,133)" 4 "DeepPink(255,20,147)" 3 "HotPink(255,105,180)" 2 "PaleVioletRed(219,112,147)" 1 "Crimson(220,20,60)" 0 "LightPink(255,182,193)";
VAL_ 1168 Sched_OTA_wake 1 "wake" 0 "standby";
VAL_ 1168 A2B_Node_sta 1 "Fail" 0 "Normal";
VAL_ 1168 Sched_Chg_Day_Set 1 "Weekday" 0 "Everyday";
VAL_ 1168 Re_Radio_Sta 1 "ON" 0 "OFF";
VAL_ 1168 UserSet 7 "Rent" 6 "Guest" 5 "User5" 4 "User4" 3 "User3" 2 "User2" 1 "User1" 0 "No Request";
VAL_ 1168 BrkAbn_GoReady_SW 1 "Press" 0 "Release";
VAL_ 1168 OTA_CompNTFY_Pres 1 "Presented" 0 "Not presented";
VAL_ 1168 mFRD_link_Sta 1 "Fail" 0 "Normal";
VAL_ 1168 PW_CLOSE_IMD 1 "Press" 0 "Release";
VAL_ 1168 PW_CONTINUE_USE 1 "Press" 0 "Release";
VAL_ 1168 IVI_DelAccReq_Sta 7 "undefined" 6 "undefined" 5 "Delete User 5 account" 4 "Delete User 4 account" 3 "Delete User 3 account" 2 "Delete User 2 account" 1 "Delete User 1 account" 0 "No Request";
VAL_ 1168 IVI_CreateAccReq_Sta 7 "undefined" 6 "undefined" 5 "Create User 5 account" 4 "Create User 4 account" 3 "Create User 3 account" 2 "Create User 2 account" 1 "Create User 1 account" 0 "No Request";
VAL_ 1168 IVI_Time_Month 15 "Not Used" 14 "Not Used" 13 "Not Used" 0 "invalid";
VAL_ 1168 IVI_LinkKey_Sta 15 "undefined" 14 "undefined" 13 "undefined" 12 "undefined" 11 "undefined" 10 "Link key 10" 9 "Link key 9" 8 "Link key 8" 7 "Link key 7" 6 "Link key 6" 5 "Link key 5" 4 "Link key 4" 3 "Link key 3" 2 "Link key 2" 1 "Link key 1" 0 "No Request";
VAL_ 1168 IVI_LinkAccReq_Sta 1 "Link account request" 0 "No Request";
VAL_ 1168 IVI_LinkAcc_Sta 7 "undefined" 6 "undefined" 5 "Link key to User 5" 4 "Link key to User 4" 3 "Link key to User 3" 2 "Link key to User 2" 1 "Link key to User 1" 0 "No Request";
VAL_ 1168 IVI_FrTrunk_UnlockReq_Sta 1 "Press" 0 "Release";
VAL_ 1168 IVI_CLWin_LockDoorSW_Sta 1 "Press" 0 "Release";
VAL_ 1168 IVI_Lock_SoundSW_Sta 1 "ON" 0 "OFF";
VAL_ 1168 AmbLightBrightnessSet 127 "Invalid" 102 "~0x7F undefined" 101 "No request" 100 "Max" 0 "Min";
VAL_ 1168 IVI_Located_STA 3 "Not Used" 2 "3D fix" 1 "2D fix" 0 "No fix";
VAL_ 1168 IVI_AutoTheme_But_Sta 1 "ON" 0 "OFF";
VAL_ 1168 IVI_NAVI_Foreground_Sta 1 "Enable" 0 "Close";
VAL_ 1168 IVI_HMI_Undefined_Sta 7 "Volume" 6 "FAN Level" 5 "Wind Direction" 4 "Auto Light/Dark Theme" 3 "NAVI" 2 "Interior Light" 1 "AVM/Rear View" 0 "A/C";
VAL_ 1168 IVI_QuickRefresh_Sta 1 "ON" 0 "OFF";
VAL_ 1168 IVI_DMS_SW_Sta 1 "ON" 0 "OFF";
VAL_ 1168 IVI_AirRefresh_ByDMS_Sta 1 "Press" 0 "Release";
VAL_ 1168 IVI_SWC_VibMode_Sta 3 "High" 2 "Middle" 1 "Low" 0 "OFF";
VAL_ 1168 IVI_sigScreenReq_Sta 1 "Press" 0 "Release";
VAL_ 1168 IVI_DSEAT_anti_set_Sta 1 "Press" 0 "Release";
VAL_ 1173 Perd_V2L 15 "8hr" 14 "7.5hr" 13 "7hr" 12 "6.5hr" 11 "6hr" 10 "5.5hr" 9 "5hr" 8 "4.5hr" 7 "4hr" 6 "3.5hr" 5 "3hr" 4 "2.5hr" 3 "2hr" 2 "1.5hr" 1 "1hr" 0 "0.5hr";
VAL_ 1173 SOC_V2LLimit 15 "invalid" 14 "undefined" 13 "undefined" 12 "80%" 11 "75%" 10 "70%" 9 "65%" 8 "60%" 7 "55%" 6 "50%" 5 "45%" 4 "40%" 3 "35%" 2 "30%" 1 "25%" 0 "20%";
VAL_ 1173 Walkaway_Lock_SW 1 "Press" 0 "Release";
VAL_ 1173 FalseNPrevent_SW 1 "ON" 0 "OFF";
VAL_ 1173 IVI_CreepSW_Req 1 "Press" 0 "Release";
VAL_ 1173 IVI_CfmTo_Rdy 1 "Press" 0 "Release";
VAL_ 1173 IVI_Req_V2L 2 "Request Internal V2L" 1 "Request External V2L" 0 "No request";
VAL_ 1173 IVI_PSEATHeater_Cmd 7 "Not used" 6 "Not used" 5 "Not used" 4 "OFF" 3 "High" 2 "Middle" 1 "Low" 0 "No request";
VAL_ 1173 IVI_DSEATHeater_Cmd 7 "Not used" 6 "Not used" 5 "Not used" 4 "OFF" 3 "High" 2 "Middle" 1 "Low" 0 "No request";
VAL_ 1173 Light_ShowStop_Req 1 "Press" 0 "Release";
VAL_ 1173 Light_ShowStart_Req 1 "Press" 0 "Release";
VAL_ 1173 WlcmLight_Mode 2 "Mode3" 1 "Mode2" 0 "Mode1";
VAL_ 1173 IVI_SWC_LUndefined_Sta 15 "Undefined" 14 "Undefined" 13 "Undefined" 12 "Undefined" 11 "Undefined" 10 "LDW Sound" 9 "SWC Heat" 8 "Fan Set" 7 "Temp Set" 6 "Wiper Sensitivity" 5 "Night Mode" 4 "LKA" 3 "NAVI" 2 "Interior Light" 1 "AVM/Rear View" 0 "Drive Mode";
VAL_ 1173 IVI_SWC_RUndefined_Sta 15 "Undefined" 14 "Undefined" 13 "Undefined" 12 "Undefined" 11 "Undefined" 10 "LDW Sound" 9 "SWC Heat" 8 "Fan Set" 7 "Temp Set" 6 "Wiper Sensitivity" 5 "Night Mode" 4 "LKA" 3 "NAVI" 2 "Interior Light" 1 "AVM/Rear View" 0 "Drive Mode";
VAL_ 1173 Sched_Chg_limit 31 "invalid" 26 "~0x1E undefined" 0 "~0x19 50%~100%";
VAL_ 1173 METER_Malfunc_Sta 2 "Warning flash" 1 "Warning" 0 "Normal";
VAL_ 1173 sigFootReq 1 "press" 0 "relesase";
VAL_ 1173 sigFaceReq 1 "press" 0 "relesase";
VAL_ 1173 Sched_Chg_Start 1 "press" 0 "release";
VAL_ 1173 Sched_Chg_wake 1 "wake" 0 "standby";
VAL_ 1173 Sched_Chg_butt 1 "on" 0 "off";
VAL_ 1173 Sched_Chg_Stop 1 "press" 0 "release";
VAL_ 1173 L_RRD_ControlCommand 127 "No Request" 100 "Max" 0 "Min";
VAL_ 1173 IVI_Start_Chg_req 1 "press" 0 "relesase";
VAL_ 1173 L_RLD_ControlCommand 127 "No Request" 100 "Max" 0 "Min";
VAL_ 1173 IVI_Stop_Chg_req 1 "press" 0 "relesase";
VAL_ 1173 L_Pas_ControlCommand 127 "No Request" 100 "Max" 0 "Min";
VAL_ 1173 IVI_Unlock_Chg_req 1 "press" 0 "relesase";
VAL_ 1173 L_Drv_ControlCommand 127 "No Request" 100 "Max" 0 "Min";
VAL_ 1173 TPMS_Cali_Butt 1 "press" 0 "relesase";
VAL_ 1173 sigHvacFrontReq 1 "Press" 0 "Release";
VAL_ 1173 sigDfrstReq 1 "press" 0 "relesase";
VAL_ 1173 sigRecircReq 1 "Press" 0 "Release";
VAL_ 1173 sigHvacReq 1 "ON" 0 "Off / Auto";
VAL_ 1173 AEB_BUTT 2 "Invalid" 1 "Pressed" 0 "No request";
VAL_ 1173 sigAirIntenZon3Req 15 "Invalid" 14 "Reserved" 11 "Reserved" 10 "NOT set" 9 "Level 8" 8 "Level 7" 7 "Level 6" 6 "Level 5" 5 "Level 4" 4 "Level 3" 3 "Level 2" 2 "Level 1" 1 "OFF" 0 "NO display / No request";
VAL_ 1173 sigAirIntenZon1Req 15 "Invalid" 14 "Reserved" 11 "Reserved" 10 "NOT set" 9 "Level 8" 8 "Level 7" 7 "Level 6" 6 "Level 5" 5 "Level 4" 4 "Level 3" 3 "Level 2" 2 "Level 1" 1 "OFF" 0 "NO display / No request";
VAL_ 1173 BSDMute_BUTT 2 "Invalid" 1 "Pressed" 0 "No request";
VAL_ 1173 sigWindDirZon3Req 7 "NOT Set / Reserved" 6 "All open" 5 "Face + Screen" 4 "DEFOG" 3 "Foot + Screen" 2 "Foot" 1 "Bilevel" 0 "FACE";
VAL_ 1173 FCWMute_BUTT 2 "Invalid" 1 "Pressed" 0 "No request";
VAL_ 1173 LKA_BUTT 2 "Invalid" 1 "Pressed" 0 "No request";
VAL_ 1173 ODAMute_BUTT 2 "Invalid" 1 "Pressed" 0 "No request";
VAL_ 1173 LDWMute_BUTT 2 "Invalid" 1 "Pressed" 0 "No request";
VAL_ 1173 NAVI_Speed_Limit_A 3 "invalid" 2 "Not Used" 1 "Applicable" 0 "Not Applicable";
VAL_ 1173 Temperature_unit 1 "Fahrenheit" 0 "Celsius";
VAL_ 1173 Distance_unit 1 "mile" 0 "kilometer";
VAL_ 1173 ESC_SW_Cmd 3 "Invaild" 2 "Undefined" 1 "Press" 0 "Release";
VAL_ 1173 IVI_Panel_Act 1 "PRESS" 0 "RELEASE";
VAL_ 1173 sigHvacRearReq 1 "Press" 0 "Release";
VAL_ 1173 Time_system 1 "24h" 0 "12h";
VAL_ 1173 Pressure_unit 1 "BAR" 0 "PSI";
VAL_ 1173 IVI_Screen 63 "invalid" 62 "undefined" 29 "undefined" 28 "APS-all" 27 "AVM-all" 26 "Phone:incoming call popup:upper" 25 "Phone:dialer-upper" 24 "Phone:call history-upper" 23 "Phone:contacts-upper" 22 "System setting-Display-all" 21 "System setting-Sound-all" 20 "System setting-Cellular-all" 19 "System setting-Bluetooth-all" 18 "System setting-WiFi-all" 17 "System setting-account-all" 16 "Setting-About-all" 15 "Setting-Software-all" 14 "Setting-Service-all" 13 "Setting-Security-all" 12 "Setting-ADAS-all" 11 "Setting-Doors-all" 10 "Setting-Charging-all" 9 "Setting-Energy-all" 8 "Setting-Spotlight-all" 7 "Navi page-upper" 6 "3rd party app page-upper" 5 "Android auto-upper" 4 "Car play-upper" 3 "All app page-upper" 2 "DropDown menu-upper" 1 "DropDown menu-all" 0 "Home-up";
VAL_ 1173 TurnSwTimeSet 3 "No Request" 2 "7 times" 1 "5 times" 0 "3 times";
VAL_ 1173 OFF_AC_MODE 7 "Invalid" 3 "CAMP" 2 "Pet" 1 "ON" 0 "OFF";
VAL_ 1173 IVI_PW_Mode_Req 3 "No request" 2 "ECO" 1 "Sport" 0 "Normal";
VAL_ 1173 User_p_upload 1 "upload" 0 "No Request";
VAL_ 1173 CameraWrn 1 "Warnning enable" 0 "Off";
VAL_ 1173 Wifi_Reset 1 "reset VIG Wifi" 0 "No Request";
VAL_ 1173 NAVI_Cam_Dist_info 255 "Invalid" 150 "MAX" 0 "Min";
VAL_ 1173 HeadLampSW 3 "OFF" 2 "Low beam" 1 "Postion lamp" 0 "AUTO";
VAL_ 1173 NAVI_State 3 "NAVI error" 2 "NAVI good reception" 1 "NAVI no satellite" 0 "No NAVI";
VAL_ 1173 Wifi_Sta_IVI_TBOX 9 "password error" 8 "Connection error" 6 "Internal Error" 5 "no signal" 4 "4 bar" 3 "3 bar" 2 "2 bar" 1 "1 bar" 0 "Invalid";
VAL_ 1173 MFRD_N_Bright_Req 127 "invalid" 100 "Max" 0 "Min";
VAL_ 1173 User_p_download 1 "download" 0 "No Request";
VAL_ 1173 PSEAT_vent_req 4 "OFF" 3 "Vent3" 2 "Vent2" 1 "Vent1" 0 "No request";
VAL_ 1173 FFogLampSW 1 "ON" 0 "OFF";
VAL_ 1173 DSEAT_vent_req 7 "Not used" 6 "Not used" 5 "Not used" 4 "OFF" 3 "High" 2 "Middle" 1 "Low" 0 "No request";
VAL_ 1173 RFogLampSW 1 "ON" 0 "OFF";
VAL_ 1173 IVI_PTG_Mode_SW 2 "Invalid" 1 "Press" 0 "No Request";
VAL_ 1173 IVI_PTG_Sta_SW 2 "Invalid" 1 "Press" 0 "Release";
VAL_ 1173 SLG_Sw 2 "invalid" 1 "ON" 0 "OFF";
VAL_ 1173 FS_Off_Sw 2 "invalid" 1 "ON" 0 "OFF";
VAL_ 1173 CAAS_Sw 2 "Invalid" 1 "Press" 0 "Release";
VAL_ 1173 DSEAT_entryfun_set 1 "ON" 0 "OFF";
VAL_ 1173 DSEAT_anti_set 1 "ON" 0 "OFF";
VAL_ 1173 IVI_TrailerCheckReq_Sta 1 "Press" 0 "Release";
VAL_ 1173 TPMS_Res_Butt 1 "Press" 0 "Release";
VAL_ 1173 FollowMeSW 1 "Press" 0 "Release";
VAL_ 1173 SetUnlockSingle 1 "Press" 0 "Release";
VAL_ 1173 IVI_Mute_Sta 1 "Mute On" 0 "Mute Off";
VAL_ 1173 IVI_PTG_USSta_SW 1 "Press" 0 "Release";
VAL_ 1173 IVI_WI_MAIN_SW 1 "ON" 0 "OFF";
VAL_ 1173 IVI_RR_Def_Req 1 "Press" 0 "Release";
VAL_ 1173 IVI_Night_Mode_Sta 1 "ON" 0 "OFF";
VAL_ 1173 IVI_Status 1 "Ready" 0 "Not ready";
VAL_ 1173 LVDAMute_BUTT 2 "Invalid" 1 "Pressed" 0 "No request";
VAL_ 1173 Hood_Latch_SW 2 "invalid" 1 "Press" 0 "No Request";
VAL_ 1173 IVI_TrailerModeSW_Sta 1 "ON" 0 "OFF";
VAL_ 1173 RCTA_BUTT 2 "Invalid" 1 "Pressed" 0 "No request";
VAL_ 1173 IVI_Pwroff_req 1 "Request" 0 "No request";
VAL_ 1173 IVI_Trigger_req 1 "Request" 0 "No request";
VAL_ 1173 AVM_Err_STA 1 "Error" 0 "No Error";
VAL_ 1173 SenstivityPosition 15 "not used" 14 "not used" 13 "not used" 12 "not used" 11 "not used" 10 "not used" 9 "not used" 8 "not used" 7 "not used" 6 "not used" 5 "not used" 4 "senstivity level-4" 3 "senstivity level-3" 2 "senstivity level-2" 1 "senstivity level-1" 0 "not used";
VAL_ 1173 AVM_Parking_mode 8 "Forced to end" 7 "emergency stop" 6 "Left parking out" 5 "Right parking out" 4 "Left Perpendicular parking" 3 "Right Perpendicular parking" 2 "Left Parallel parking" 1 "Right Parallel parking" 0 "No message";
VAL_ 1173 NAVI_ForwardLinkLevel 15 "undefined" 14 "undefined" 13 "undefined" 12 "undefined" 11 "undefined" 10 "undefined" 9 "undefined" 8 "etc" 7 "shoulder" 6 "ramp" 5 "Freeway" 4 "Bus lane" 3 "Roundabout" 2 "City Lv2" 1 "City Lv1" 0 "NA";
VAL_ 1173 NAVI_LinkClass 15 "undefined" 14 "undefined" 13 "undefined" 12 "undefined" 11 "undefined" 10 "undefined" 9 "undefined" 8 "etc" 7 "shoulder" 6 "ramp" 5 "Freeway" 4 "Bus lane" 3 "Roundabout" 2 "City Lv2" 1 "City Lv1" 0 "NA";
VAL_ 1173 NAVI_SpeedLimit 31 "80mph" 30 "75mph" 29 "70mph" 28 "65mph" 27 "60mph" 26 "55mph" 25 "50mph" 24 "45mph" 23 "40mph" 22 "35mph" 21 "30mph" 20 "25mph" 19 "20mph" 18 "15mph" 17 "10mph" 16 "160 km/h" 15 "150 km/h" 14 "140 km/h" 13 "130 km/h" 12 "120 km/h" 11 "110 km/h" 10 "100 km/h" 9 "90 km/h" 8 "80 km/h" 7 "70 km/h" 6 "60 km/h" 5 "50 km/h" 4 "40 km/h" 3 "30 km/h" 2 "20 km/h" 1 "10 km/h" 0 "No request";
VAL_ 1173 NAVI_RoadClass 7 "undefined" 6 "undefined" 5 "Freeway" 4 "School" 3 "Street" 2 "Interurban" 1 "City" 0 "NA";
VAL_ 1173 RoomLampMode 1 "Press" 0 "Release";
VAL_ 1173 IVI_SWC_ACCMode_Sta 1 "ACC+LFC" 0 "ACC";
VAL_ 1173 SOC_Limit_Set 31 "invalid" 26 "~0x1E undefined" 0 "~0x19 50%~100%";
VAL_ 1173 CDL_Lock_Butt 1 "Press" 0 "Release";
VAL_ 1173 CDL_Unlock_Butt 1 "Press" 0 "Release";
VAL_ 1173 SOC_ADJ_BUTT 1 "Press" 0 "Release";
VAL_ 1173 Roll_Mode_SW_Cmd 3 "Invaild" 2 "Undefined" 1 "Press" 0 "Release";
VAL_ 1173 TCS_SW_Cmd 3 "Invaild" 2 "Undefined" 1 "Press" 0 "Release";
VAL_ 1173 SLIF_BUTT 2 "Invalid" 1 "Pressed" 0 "No request";
VAL_ 1173 Roll_Eng_Mode 1 "on" 0 "off";
VAL_ 1173 IVI_LVChrgFuncSW 3 "Undefined" 2 "Invalid" 1 "Press (>0.5s)" 0 "Release";
VAL_ 1173 IVI_PwrLockSW 3 "Undefined" 2 "Invalid" 1 "Press (>0.5s)" 0 "Release";
VAL_ 1173 IVI_CoastDwSW 3 "Undefined" 2 "Invalid" 1 "Press (>0.5s)" 0 "Release";
VAL_ 1173 IVI_ActvDmpDisabSW 3 "Undefined" 2 "Invalid" 1 "Press (>0.5s)" 0 "Release";
VAL_ 1173 AVM_parking_cancel 2 "invalid" 1 "press" 0 "release";
VAL_ 1173 AVM_parking_excute 3 "remote request" 2 "invalid" 1 "press" 0 "release";
VAL_ 1173 AVM_OFF_Rec_Butt 1 "ON" 0 "OFF";
VAL_ 1173 Approach_Unlock_SW 1 "Press" 0 "Release";
VAL_ 1173 IVI_ISA_OffsetSpd 15 "Invalid" 14 "reserve" 13 "reserve" 12 "reserve" 11 "5 mph" 10 "0 mph" 9 "-5 mph" 8 "reserve" 7 "reserve" 6 "reserve" 5 "+10 km/h" 4 "+5 km/h" 3 "0 km/h" 2 "-5 km/h" 1 "-10 km/h" 0 "Off";
VAL_ 1173 IVI_PTG_Open_Height 7 "Invalid" 6 "Invalid" 5 "No Request" 4 "Set by User" 3 "Lv3(80%)" 2 "Lv2(60%)" 1 "Lv1(40%)" 0 "Full Open";
VAL_ 1173 IVI_ChargePortSW_Sta 1 "Press" 0 "Release";
VAL_ 1173 IVI_SLIF_Warning_Sta 3 "Reserve" 2 "OFF" 1 "Visual + Sound" 0 "Visual";
VAL_ 1173 IVI_ACC_Adaptive_Sta 1 "Adaptive" 0 "Non Adaptive";
VAL_ 1173 IVI_PSEAT_Slide_Cmd 3 "Invalid" 2 "Backward" 1 "Forward" 0 "No Request";
VAL_ 1173 IVI_DSEAT_FroEdge_Height_Cmd 3 "Invalid" 2 "Down" 1 "Up" 0 "No Request";
VAL_ 1173 IVI_DSEAT_Height_Cmd 3 "Invalid" 2 "Down" 1 "Up" 0 "No Request";
VAL_ 1173 IVI_DSEAT_Recline_Cmd 3 "Invalid" 2 "Backward" 1 "Forward" 0 "No Request";
VAL_ 1173 IVI_PSEAT_Recline_Cmd 3 "Invalid" 2 "Backward" 1 "Forward" 0 "No Request";
VAL_ 1173 IVI_DSEAT_Memory_OPTCLS_Sta 1 "Press" 0 "Release";
VAL_ 1173 IVI_SetTempZon2_Sta 31 "No request" 30 "32 DegC" 29 "31.5 DegC" 28 "31 DegC" 27 "30.5 DegC" 26 "30 DegC" 25 "29.5 DegC" 24 "29 DegC" 23 "28.5 DegC" 22 "28 DegC" 21 "27.5 DegC" 20 "27 DegC" 19 "26.5 DegC" 18 "26 DegC" 17 "25.5 DegC" 16 "25 DegC" 15 "24.5 DegC" 14 "24 DegC" 13 "23.5 DegC" 12 "23 DegC" 11 "22.5 DegC" 10 "22 DegC" 9 "21.5 DegC" 8 "21 DegC" 7 "20.5 DegC" 6 "20 DegC" 5 "19.5 DegC" 4 "19 DegC" 3 "18.5 DegC" 2 "18 DegC" 1 "17.5 DegC" 0 "17 DegC";
VAL_ 1173 IVI_AirIntZ3_Cmd 4 "Level 3" 3 "Level 2" 2 "Level 1" 1 "OFF" 0 "No Request";
VAL_ 1173 IVI_SetTempZon1_Sta 31 "No request" 30 "32 DegC" 29 "31.5 DegC" 28 "31 DegC" 27 "30.5 DegC" 26 "30 DegC" 25 "29.5 DegC" 24 "29 DegC" 23 "28.5 DegC" 22 "28 DegC" 21 "27.5 DegC" 20 "27 DegC" 19 "26.5 DegC" 18 "26 DegC" 17 "25.5 DegC" 16 "25 DegC" 15 "24.5 DegC" 14 "24 DegC" 13 "23.5 DegC" 12 "23 DegC" 11 "22.5 DegC" 10 "22 DegC" 9 "21.5 DegC" 8 "21 DegC" 7 "20.5 DegC" 6 "20 DegC" 5 "19.5 DegC" 4 "19 DegC" 3 "18.5 DegC" 2 "18 DegC" 1 "17.5 DegC" 0 "17 DegC";
VAL_ 1173 IVI_DSEAT_Slide_Cmd 3 "Invalid" 2 "Backward" 1 "Forward" 0 "No Request";
VAL_ 1173 IVI_DSEAT_Memory1_Sta 1 "Press" 0 "Release";
VAL_ 1173 IVI_DSEAT_Memory2_Sta 1 "Press" 0 "Release";
VAL_ 1173 DMS_Status 3 "Disable" 2 "Error" 1 "Active" 0 "Off";
VAL_ 1173 DMS_Warning_Distraction 3 "Phone Use" 2 "Short Distraction" 1 "Long Distraction" 0 "No Warning";
VAL_ 1173 DMS_Warning_Fatigue 3 "Sleep" 2 "Microsleep" 1 "Drowsiness" 0 "No Warning";
VAL_ 1173 DMS_Warning_Unresponsive 1 "Unresponsive" 0 "Responsive";
VAL_ 1312 NM_IVI_Rpt_Msg_Req 1 "Repeat Message State requested" 0 "Repeat Message State not requested";
VAL_ 1312 NM_IVI_CSB 1 "Start of synchronized shutdown is requested by main coordinator" 0 "Start of synchronized shutdown is not requested by main coordinator";
VAL_ 1312 NM_IVI_Active_WU 1 "Node has woken up the network (active Wakeup)" 0 "Node has not woken up the network (passive wakeup)";
VAL_ 1312 NM_IVI_PNI 1 "NM PDU contains Partial Network request information" 0 "NM PDU contains no Partial Network request information";
VAL_ 1312 NM_IVI_ERROR_State 8 "BUS OFF_L2" 4 "BUS OFF_L1" 2 "ERROR PASSIVE" 1 "ERROR ACTIVE" 0 "Inactive";
VAL_ 2362634068 CP2VAutoTracH 1 "Enable automatic traction help" 0 "Disable automatic traction help";
VAL_ 2362634068 CP2VKneeReqLSide 1 "Kneeling request" 0 "No Kneeling request";
VAL_ 2362634068 CP2VKneeReqRSide 1 "Kneeling request" 0 "No Kneeling request";
VAL_ 2362634068 CP2VKneeCtrlMReq 1 "Manually actuated" 0 "Automatically actuated";
VAL_ 2362634068 CP2VNLvReqFA 8 "Stop level change" 7 "Lower level" 6 "Upper level" 5 "Customer Level" 4 "Preset Level" 3 "Normal Level 3" 2 "Normal Level 2" 1 "Normal Level 1" 0 "No level request";
VAL_ 2362634068 CP2VNLvReqRA 8 "Stop level change" 7 "Lower level" 6 "Upper level" 5 "Customer Level" 4 "Preset Level" 3 "Normal Level 3" 2 "Normal Level 2" 1 "Normal Level 1" 0 "No level request";
VAL_ 2362634068 CP2VLvCtrlModeReq 8 "Exhausting bellow function" 7 "Traction help (Load reduce)" 6 "Optimum Traction 2" 5 "Optimum Traction 1" 4 "Pressure ratio 2" 3 "Pressure ratio 1" 2 "Load fixing" 1 "Traction help (load transfer)" 0 "Normal operation";
VAL_ 2362634068 CP2VLA1PosCmd 1 "Lift axle position up / tag axle unladen" 0 "Lift axle position down / tag axle laden";
VAL_ 2362634068 CP2VLA2PosCmd 1 "Lift axle position up / tag axle unladen" 0 "Lift axle position down / tag axle laden";
VAL_ 2362634068 CP2VKneeReqFA 1 "Kneeling request" 0 "No Kneeling request";
VAL_ 2362634068 CP2VKneeReqRA 1 "Kneeling request" 0 "No Kneeling request";
VAL_ 2147484162 FDC_VCU_DACStatus_Sta 3 "Disable" 2 "Warning" 1 "Run" 0 "Ready";
VAL_ 2147484162 FDC_VCU_TUpASta_Sta 3 "Disable" 2 "Warning" 1 "Run" 0 "Ready";
VAL_ 2147484162 FDC_BCM_WelcomeDemo_Sta 1 "Demo" 0 "No Request";
VAL_ 2147484162 FDC_BCM_TgateSWL_Sta 1 "Open" 0 "Close";
VAL_ 2147484162 FDC_BCM_TgateSWR_Sta 1 "Open" 0 "Close";
VAL_ 2566000691 T1_TPMS_RBOPressIndi 3 "invalid" 2 "pressure too low" 1 "pressure too high" 0 "Normal";
VAL_ 2566000691 T1_TPMS_LBOPressIndi 3 "invalid" 2 "pressure too low" 1 "pressure too high" 0 "Normal";
VAL_ 2566000691 T1_TPMS_RBIPressIndi 3 "invalid" 2 "pressure too low" 1 "pressure too high" 0 "Normal";
VAL_ 2566000691 T1_TPMS_LBIPressIndi 3 "invalid" 2 "pressure too low" 1 "pressure too high" 0 "Normal";
VAL_ 2566000691 T1_TPMS_RBOWheelTmpIndi 1 "overheated" 0 "Normal";
VAL_ 2566000691 T1_TPMS_LBOWheelTmpIndi 1 "overheated" 0 "Normal";
VAL_ 2566000691 T1_TPMS_RBIWheelTmpIndi 1 "overheated" 0 "Normal";
VAL_ 2566000691 T1_TPMS_LBIWheelTmpIndi 1 "overheated" 0 "Normal";
VAL_ 2566000691 T1_TPMS_RBOSensorFail 1 "Fail" 0 "Normal";
VAL_ 2566000691 T1_TPMS_LBOSensorFail 1 "Fail" 0 "Normal";
VAL_ 2566000691 T1_TPMS_RBISensorFail 1 "Fail" 0 "Normal";
VAL_ 2566000691 T1_TPMS_LBISensorFail 1 "Fail" 0 "Normal";
VAL_ 2566000691 T1_TPMS_RBOBatWarn 1 "Low" 0 "Normal";
VAL_ 2566000691 T1_TPMS_LBOBatWarn 1 "Low" 0 "Normal";
VAL_ 2566000691 T1_TPMS_RBIBatWarn 1 "Low" 0 "Normal";
VAL_ 2566000691 T1_TPMS_LBIBatWarn 1 "Low" 0 "Normal";
VAL_ 2566000691 T1_TPMS_TPMSExist 1 "Exist" 0 "Not Exist";
VAL_ 2566000691 T1_TPMS_RFPressIndi 3 "invalid" 2 "pressure too low" 1 "pressure too high" 0 "Normal";
VAL_ 2566000691 T1_TPMS_TPMSWarnIndi 3 "Invalid" 2 "Indicator Flash" 1 "Indicator ON" 0 "Indicator OFF";
VAL_ 2566000691 T1_TPMS_LFBatWarn 1 "Low" 0 "Normal";
VAL_ 2566000691 T1_TPMS_LFPressIndi 3 "invalid" 2 "pressure too low" 1 "pressure too high" 0 "Normal";
VAL_ 2566000691 T1_TPMS_LFSensorFail 1 "Fail" 0 "Normal";
VAL_ 2566000691 T1_TPMS_LFWheelTmpIndi 1 "overheated" 0 "Normal";
VAL_ 2566000691 T1_TPMS_RFBatWarn 1 "Low" 0 "Normal";
VAL_ 2566000691 T1_TPMS_RFSensorFail 1 "Fail" 0 "Normal";
VAL_ 2566000691 T1_TPMS_RFWheelTmpIndi 1 "overheated" 0 "Normal";
VAL_ 2566000947 T1_TPMS_MeterSpdFlag 1 "Count" 0 "Normal";
VAL_ 2566000947 T1_TPMS_RBOWheelDebug 1 "Receive" 0 "Normal";
VAL_ 2566000947 T1_TPMS_RBIWheelDebug 1 "Receive" 0 "Normal";
VAL_ 2566000947 T1_TPMS_LBOWheelDebug 1 "Receive" 0 "Normal";
VAL_ 2566000947 T1_TPMS_LBIWheelDebug 1 "Receive" 0 "Normal";
VAL_ 2566000947 T1_TPMS_LFWheelPress 255 "Invalid" 250 "Max" 0 "Min";
VAL_ 2566000947 T1_TPMS_RFWheelPress 255 "Invalid" 250 "Max" 0 "Min";
VAL_ 2566000947 T1_TPMS_LFWheelDebug 1 "Receive" 0 "Normal";
VAL_ 2566000947 T1_TPMS_RFWheelDebug 1 "Receive" 0 "Normal";
VAL_ 2566001203 T1_TPMS_LFWheelTemp 255 "Invalid";
VAL_ 2566001203 T1_TPMS_RFWheelTemp 255 "Invalid";
VAL_ 2566844752 EPB_ParkingBrake_Sta 3 "Not available" 2 "Error" 1 "Parking brake set" 0 "Parking brake not set";
VAL_ 2566896720 EPB_ParkBrakeStateLamp_sta 3 "not available" 2 "Flash" 1 "On" 0 "Off";
VAL_ 2566896720 EPB_BrakePedalActuationInd_cmd 3 "Unavailable" 2 "Error" 1 "Active" 0 "Not active";
VAL_ 2566896720 EPB_ParkBrake_Sta 15 "Unavailable" 14 "Error" 13 "Reserved" 12 "Reserved" 11 "Trailer check hold" 10 "Emergency Release" 9 "Dynamic brake spring brake / XBR" 8 "Dynamic brake XBR" 7 "Dynamic brake spring brake" 6 "ARB supervision" 5 "Workshop mode" 4 "Park brake released securing" 3 "Park brake state changes" 2 "Trailer check" 1 "Park brake applied" 0 "Park brake not applied";
VAL_ 2566896720 EPB_SpringBrakeABSActive_sta 3 "Unavailable" 2 "Error" 1 "Active" 0 "Not active";
VAL_ 2566896720 EPB_SpringBrakePressure_Sta 251 "Invalid Value";
VAL_ 2566896720 EPB_ParkBrakeApply_Sta 7 "not available" 6 "reserved" 5 "reserved" 4 "reserved" 3 "Auto request" 2 "External request" 1 "Manual request" 0 "No request";
VAL_ 2566896720 EPB_ParkBrakeRelease_Sta 7 "not available" 6 "reserved" 5 "reserved" 4 "reserved" 3 "Auto request" 2 "External request" 1 "Manual request" 0 "No request";
VAL_ 2566896720 EPB_ParkBrkReleaseInhibitInd_Cmd 3 "Unavailable" 2 "Reserved" 1 "Release inhibited" 0 "No indication";
VAL_ 2566896720 EPB_ExtParkBrakeSystem_Sta 7 "not available" 6 "error" 5 "reserved" 4 "reserved" 3 "no request possible" 2 "only release possible" 1 "only apply possible" 0 "unrestricted availability";
VAL_ 2566896720 EPB_HcuSwitch_Sta 7 "Unavailable" 6 "Error" 5 "Gradual" 4 "TrailerCheck" 3 "Toggle" 2 "Release" 1 "Apply" 0 "Neutral";
VAL_ 2566896720 EPB_ParkBrkLowAirIndication_Cmd 7 "Unavailable" 6 "Reserved" 5 "Reserved" 4 "Reserved" 3 "Release not possible" 2 "Release abort" 1 "Release inhibition" 0 "No indication";
VAL_ 515 Z24_BCM_FWiperProtection_Sta 1 "In protection" 0 "Not in Protectio";
VAL_ 515 Z24_BCM_FWiperAS_Sta 1 "Not at Stop Position" 0 "Stop Position";
VAL_ 515 Z24_BCM_EmExitOP_Sta 1 "ON" 0 "OFF";
VAL_ 515 Z24_BCM_innerBuzzer_Sta 1 "ON" 0 "OFF";
VAL_ 515 Z24_BCM_SeatBeltSW_Sta 1 "fasten" 0 "Unfasten";
VAL_ 2566827568 Z24_CHA_AirPressurePC3_Sta 176 "Invalid Value";
VAL_ 2566827568 Z24_CHA_AirPressureRC1_Sta 176 "Invalid Value";
VAL_ 2566827568 Z24_CHA_AirPressureFC2_Sta 176 "Invalid Value";
VAL_ 2565865967 FDC_CHA_CACTempWarn_Sta 1 "alarm" 0 "normal";
VAL_ 2565865967 FDC_CHA_CACPresWarn_Sta 1 "low pressure warning" 0 "no warning";
VAL_ 2566887584 IVI_D_ACSwitch_cmd 1 "ON" 0 "OFF";
VAL_ 2566887584 IVI_D_AirflowUpControl_cmd 1 "ON" 0 "OFF";
VAL_ 2566887584 IVI_D_AirflowDownControl_cmd 1 "ON" 0 "OFF";
VAL_ 2566887584 IVI_D_TemperatureUpControl_cmd 1 "ON" 0 "OFF";
VAL_ 2566887584 IVI_D_TempDownControl_cmd 1 "ON" 0 "OFF";
VAL_ 2566887584 IVI_D_AutoSwitch_cmd 1 "Manual" 0 "Auto";
VAL_ 2566887584 IVI_D_MaxAirflowSwitch_cmd 1 "MAX OFF" 0 "MAX ON";
VAL_ 2566887584 IVI_D_PowerSwitch_cmd 1 "AC Power OFF" 0 "AC Power 0N";
VAL_ 2566887584 IVI_RMirrorHeatSta_cmd 1 "Press" 0 "Release";
VAL_ 2566834735 ECASPLampSta 2 "Not defined" 1 "Lamp on" 0 "Lamp off";
VAL_ 2566834735 ECASAWarmLampSta 2 "Not defined" 1 "Lamp on" 0 "Lamp off";
VAL_ 2566834735 ECASRStopLampSta 2 "Not defined" 1 "Lamp on" 0 "Lamp off";
VAL_ 2566834735 ECASMFLampSta 2 "Not defined" 1 "Lamp on" 0 "Lamp off";
VAL_ 2566887345 AC_Blower_lvl_sta 253 "OUT OF RANGE" 6 "OUT OF RANGE" 5 "LV5" 4 "LV4" 3 "LV3" 2 "LV2" 1 "LV1" 0 "OFF";
VAL_ 2566887345 AC_D_ACOnDisplay_sta 1 "ON" 0 "OFF";
VAL_ 2566887345 AC_D_MaxAirflowDisplay_sta 1 "MAX OFF" 0 "MAX ON";
VAL_ 2566887345 AC_D_PowerOnDisplay_cmd 1 "Power OFF" 0 "Power 0N";
VAL_ 2566887345 AC_Set_temp_sta 254 "Out of range" 25 "Out of range" 24 "30" 23 "29.5" 22 "29" 21 "28.5" 20 "28" 19 "27.5" 18 "27" 17 "26.5" 16 "26" 15 "25.5" 14 "25" 13 "24.5" 12 "24" 11 "23.5" 10 "23" 9 "22.5" 8 "22" 7 "21.5" 6 "21" 5 "20.5" 4 "20" 3 "19.5" 2 "19" 1 "18.5" 0 "18";
VAL_ 2566887345 AC_D_AutoOnDisplay_sta 1 "AUTO ON" 0 "AUTO OFF";
VAL_ 1175 IVI_CLBlower_Y_Sta 127 "No Request" 126 "OFF";
VAL_ 1175 IVI_CLBlower_Z_Sta 127 "No Request";
VAL_ 1175 IVI_CRBlower_Y_Sta 127 "No Request" 126 "OFF";
VAL_ 1175 IVI_CRBlower_Z_Sta 127 "No Request";
VAL_ 1175 IVI_DrBlower_Mode_Sta 3 "Balanced" 2 "Sweep" 1 "Manual" 0 "No Request";
VAL_ 1175 IVI_DrBlower_Y_Sta 127 "No Request" 126 "OFF";
VAL_ 1175 IVI_DrBlower_Z_Sta 127 "No Request";
VAL_ 1175 IVI_LSEATvent_Cmd 4 "OFF" 3 "3(High)" 2 "2(Middle)" 1 "1(Low)" 0 "NoRequest";
VAL_ 1175 IVI_MLFMost_Cmd 1 "Press" 0 "Release";
VAL_ 1175 IVI_MLFootLift_Cmd 2 "Down" 1 "Up" 0 "StandBy";
VAL_ 1175 IVI_MLNapMode_Cmd 1 "Press" 0 "Release";
VAL_ 1175 IVI_MLRecliner_Cmd 2 "Backward" 1 "Forward" 0 "StandBy";
VAL_ 1175 IVI_MLRestore_Cmd 1 "Press" 0 "Release";
VAL_ 1175 IVI_MLSEATvent_Cmd 4 "OFF" 3 "3(High)" 2 "2(Middle)" 1 "1(Low)" 0 "NoRequest";
VAL_ 1175 IVI_MLSeatLift_Cmd 2 "Down" 1 "Up" 0 "StandBy";
VAL_ 1175 IVI_MLSldRestore_Cmd 1 "Press" 0 "Release";
VAL_ 1175 IVI_MLSlider_Cmd 2 "Backward" 1 "Forward" 0 "StandBy";
VAL_ 1175 IVI_MLZeroGravity_Cmd 1 "Press" 0 "Release";
VAL_ 1175 IVI_MRFMost_Cmd 1 "Press" 0 "Release";
VAL_ 1175 IVI_MRFootLift_Cmd 2 "Down" 1 "Up" 0 "StandBy";
VAL_ 1175 IVI_MRNapMode_Cmd 1 "Press" 0 "Release";
VAL_ 1175 IVI_MRRecliner_Cmd 2 "Backward" 1 "Forward" 0 "StandBy";
VAL_ 1175 IVI_MRRestore_Cmd 1 "Press" 0 "Release";
VAL_ 1175 IVI_MRSEATvent_Cmd 4 "OFF" 3 "3(High)" 2 "2(Middle)" 1 "1(Low)" 0 "NoRequest";
VAL_ 1175 IVI_MRSeatLift_Cmd 2 "Down" 1 "Up" 0 "StandBy";
VAL_ 1175 IVI_MRSldRestore_Cmd 1 "Press" 0 "Release";
VAL_ 1175 IVI_MRSlider_Cmd 2 "Backward" 1 "Forward" 0 "StandBy";
VAL_ 1175 IVI_MRZeroGravity_Cmd 1 "Press" 0 "Release";
VAL_ 1175 IVI_PsBlower_Mode_Sta 3 "Balanced" 2 "Sweep" 1 "Manual" 0 "No Request";
VAL_ 1175 IVI_PsBlower_Y_Sta 127 "No Request" 126 "OFF";
VAL_ 1175 IVI_PsBlower_Z_Sta 127 "No Request";
VAL_ 1175 IVI_RSEATvent_Cmd 4 "OFF" 3 "3(High)" 2 "2(Middle)" 1 "1(Low)" 0 "NoRequest";
VAL_ 2566838066 Door_Fr_DoorEmergency_sta 3 "Not defined" 2 "Not defined" 1 "Emergency" 0 "No Emergency";
VAL_ 2566838066 Door_Fr_Doorposition_sta 3 "Not defined" 2 "Partial opening" 1 "Open" 0 "Closed";
VAL_ 2566838066 Door_Fr_Dooroperation_sta 3 "Not defined" 2 "Opening" 1 "Opening" 0 "Door stopped";
